VERSION ""

NS_ :

BS_:

BU_: EHR_Spare FEHR_3 PTO_SpeedSelector Dummy_Node_Ch2 FEHR_2 TrailerBrake OffBoardDiagnosticTool1_Ch2 PowerTakeOff_Ch2 Transmission1_Ch2 FEHR_1 REHR_5 REHR_4 REHR_3 REHR_2 REHR_1 InstrumentCluster_Ch2 ManagementComputer_Ch2 GWAY_OnBoardDiagnosticUnit_Ch2 GWAY_OffBoardDiagTool1_VB1_Ch2 GWAY_Engine1_Ch2 GWAY_CabDisplay1_Ch2 AuxiliaryValveControl_Ch2

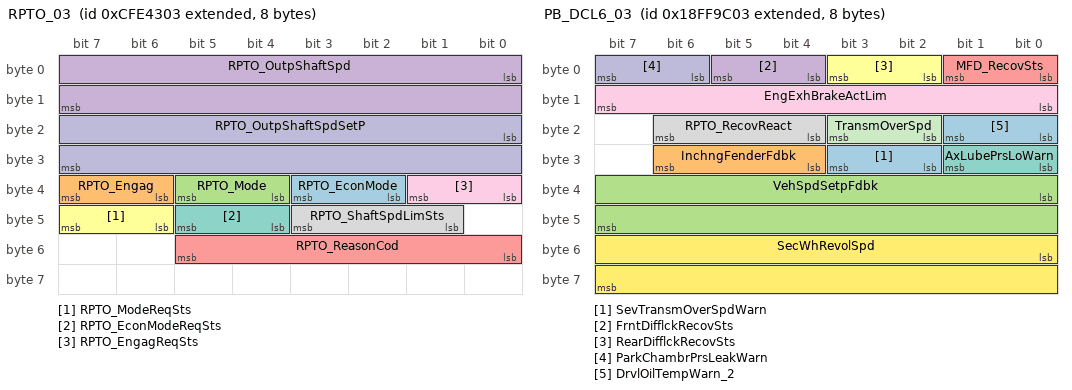
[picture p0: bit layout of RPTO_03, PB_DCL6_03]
BO_ 2365473539 RPTO_03: 8 Transmission1_Ch2
 SG_ RPTO_EconMode : 34|2@1+ (1,0) [0|3] ""  ManagementComputer_Ch2
 SG_ RPTO_Engag : 38|2@1+ (1,0) [0|3] ""  ManagementComputer_Ch2
 SG_ RPTO_Mode : 36|2@1+ (1,0) [0|3] ""  ManagementComputer_Ch2
 SG_ RPTO_OutpShaftSpd : 0|16@1+ (0.125,0) [0|8031.88] "1/min"  ManagementComputer_Ch2
 SG_ RPTO_ReasonCod : 48|6@1+ (1,0) [0|63] ""  ManagementComputer_Ch2
 SG_ RPTO_ModeReqSts : 46|2@1+ (1,0) [0|3] "" Vector__XXX
 SG_ RPTO_EconModeReqSts : 44|2@1+ (1,0) [0|3] "" Vector__XXX
 SG_ RPTO_ShaftSpdLimSts : 41|3@1+ (1,0) [0|7] "" Vector__XXX
 SG_ RPTO_EngagReqSts : 32|2@1+ (1,0) [0|3] "" Vector__XXX
 SG_ RPTO_OutpShaftSpdSetP : 16|16@1+ (0.125,0) [0|8031.88] "rpm" Vector__XXX

BO_ 2566877955 PB_ECU_DatasetChksum_03: 8 Transmission1_Ch2
 SG_ ECU_DatasetChksum : 0|32@1+ (1,0) [0|4294967295] ""  ManagementComputer_Ch2

BO_ 2565482243 RQST_03_27: 3 Transmission1_Ch2
 SG_ PGN_RQST_03_27 : 0|24@1+ (1,0) [0|16777200] ""  ManagementComputer_Ch2

BO_ 2566888451 PB_DCL6_03: 8 Transmission1_Ch2
 SG_ SevTransmOverSpdWarn : 26|2@1+ (1,0) [0|3] ""  ManagementComputer_Ch2
 SG_ InchngFenderFdbk : 28|3@1+ (1,0) [0|7] ""  ManagementComputer_Ch2
 SG_ VehSpdSetpFdbk : 32|16@1+ (0.015625,0) [0|1003.98] ""  ManagementComputer_Ch2
 SG_ FrntDifflckRecovSts : 4|2@1+ (1,0) [0|3] ""  ManagementComputer_Ch2
 SG_ MFD_RecovSts : 0|2@1+ (1,0) [0|3] ""  ManagementComputer_Ch2
 SG_ RearDifflckRecovSts : 2|2@1+ (1,0) [0|3] ""  ManagementComputer_Ch2
 SG_ AxLubePrsLoWarn : 24|2@1+ (1,0) [0|3] ""  ManagementComputer_Ch2
 SG_ RPTO_RecovReact : 20|3@1+ (1,0) [0|7] ""  ManagementComputer_Ch2
 SG_ EngExhBrakeActLim : 8|8@1+ (0.4,0) [0|100] "%"  ManagementComputer_Ch2
 SG_ ParkChambrPrsLeakWarn : 6|2@1+ (1,0) [0|3] ""  ManagementComputer_Ch2
 SG_ TransmOverSpd : 18|2@1+ (1,0) [0|3] ""  ManagementComputer_Ch2
 SG_ SecWhRevolSpd : 48|16@1+ (0.015625,0) [0|1003.98] ""  ManagementComputer_Ch2
 SG_ DrvlOilTempWarn_2 : 16|2@1+ (1,0) [0|3] "" Vector__XXX

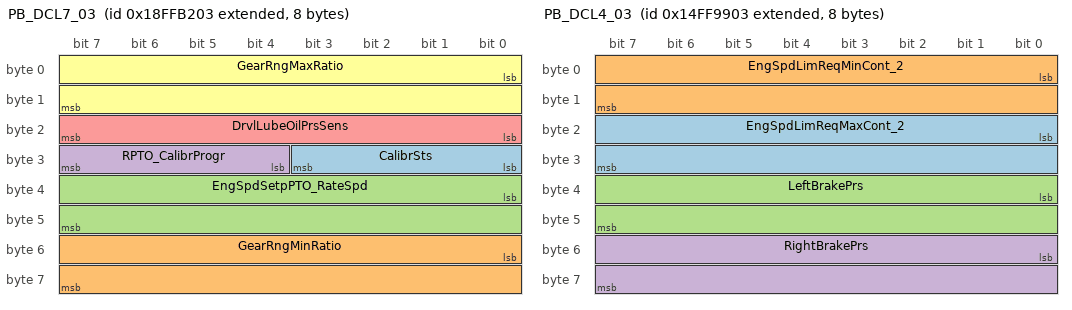
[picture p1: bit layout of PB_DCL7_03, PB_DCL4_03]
BO_ 2566894083 PB_DCL7_03: 8 Transmission1_Ch2
 SG_ CalibrSts : 24|4@1+ (1,0) [0|15] ""  ManagementComputer_Ch2
 SG_ GearRngMinRatio : 48|16@1+ (1E-05,0) [0|0.3] ""  ManagementComputer_Ch2
 SG_ EngSpdSetpPTO_RateSpd : 32|16@1+ (0.125,0) [0|8031.88] "rpm"  ManagementComputer_Ch2
 SG_ RPTO_CalibrProgr : 28|4@1+ (1,0) [0|15] ""  ManagementComputer_Ch2
 SG_ DrvlLubeOilPrsSens : 16|8@1+ (5,0) [0|1250] "kPa"  ManagementComputer_Ch2
 SG_ GearRngMaxRatio : 0|16@1+ (1E-05,0) [0|0.3] ""  ManagementComputer_Ch2

BO_ 2499778819 PB_DCL4_03: 8 Transmission1_Ch2
 SG_ EngSpdLimReqMaxCont_2 : 16|16@1+ (0.125,0) [0|8031.88] "rpm"  ManagementComputer_Ch2
 SG_ EngSpdLimReqMinCont_2 : 0|16@1+ (0.125,0) [0|8031.88] "rpm"  ManagementComputer_Ch2
 SG_ LeftBrakePrs : 32|16@1+ (1,0) [0|64255] "kPa"  ManagementComputer_Ch2
 SG_ RightBrakePrs : 48|16@1+ (1,0) [0|64255] "kPa"  ManagementComputer_Ch2

BO_ 2566842115 VH_03: 8 Transmission1_Ch2
 SG_ TotPTO_Hour : 32|32@1+ (0.05,0) [0|210554060.75] "h"  ManagementComputer_Ch2
 SG_ TotVehHour : 0|32@1+ (0.05,0) [0|2.10554E+18] "h"  ManagementComputer_Ch2

BO_ 2566801923 ETC7_03: 8 Transmission1_Ch2
 SG_ TransmReqGearFdbk : 24|8@1+ (1,-125) [-125|130] "gear value"  ManagementComputer_Ch2
 SG_ TransmMode_9Ind : 44|2@1+ (1,0) [0|3] "" Vector__XXX
 SG_ TransmMode_10Ind : 46|2@1+ (1,0) [0|3] "" Vector__XXX
 SG_ TransmAutoN_Sts : 51|3@1+ (1,0) [0|7] "" Vector__XXX
 SG_ TransmAirSupplyPrsInd : 48|3@1+ (1,0) [0|7] "" Vector__XXX
 SG_ TransmCurrRngDisplayBlnkSts : 0|2@1+ (1,0) [0|3] "" Vector__XXX
 SG_ TransmServInd : 2|2@1+ (1,0) [0|3] "" Vector__XXX
 SG_ TransmReqRngDisplayBlnkSts : 4|2@1+ (1,0) [0|3] "" Vector__XXX
 SG_ TransmReqRngDisplayFlashSts : 6|2@1+ (1,0) [0|3] "" Vector__XXX
 SG_ TransmReadyBrakeRleas : 8|2@1+ (1,0) [0|3] "" Vector__XXX
 SG_ ActvShftConsleInd : 10|2@1+ (1,0) [0|3] "" Vector__XXX
 SG_ TransmEngCrkEna : 12|2@1+ (1,0) [0|3] "" Vector__XXX
 SG_ TransmShftInhInd : 14|2@1+ (1,0) [0|3] "" Vector__XXX
 SG_ TransmMode_4Ind : 16|2@1+ (1,0) [0|3] "" Vector__XXX
 SG_ TransmMode_3Ind : 18|2@1+ (1,0) [0|3] "" Vector__XXX
 SG_ TransmMode_2Ind : 20|2@1+ (1,0) [0|3] "" Vector__XXX
 SG_ TransmMode_1Ind : 22|2@1+ (1,0) [0|3] "" Vector__XXX
 SG_ TransmMode_5Ind : 32|2@1+ (1,0) [0|3] "" Vector__XXX
 SG_ TransmMode_6Ind : 34|2@1+ (1,0) [0|3] "" Vector__XXX
 SG_ TransmMode_7Ind : 36|2@1+ (1,0) [0|3] "" Vector__XXX
 SG_ TransmMode_8Ind : 38|2@1+ (1,0) [0|3] "" Vector__XXX
 SG_ TransmRevGearShftInhSts : 40|2@1+ (1,0) [0|3] "" Vector__XXX
 SG_ TransmWarnInd : 42|2@1+ (1,0) [0|3] "" Vector__XXX

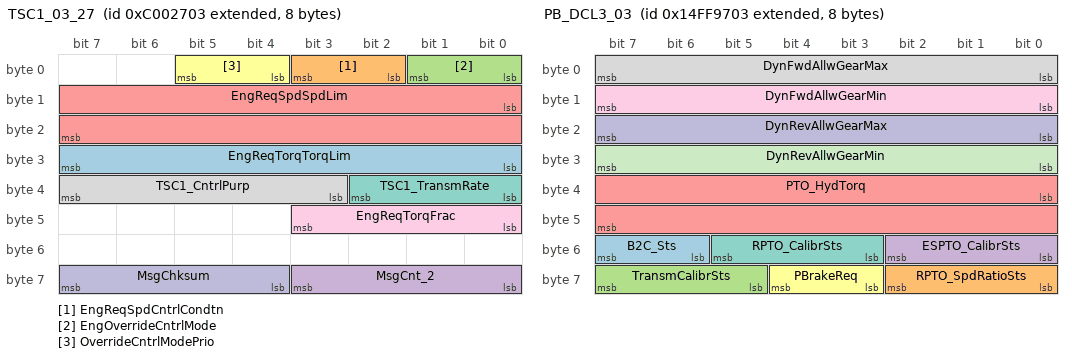
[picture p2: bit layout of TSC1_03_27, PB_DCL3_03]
BO_ 2348820227 TSC1_03_27: 8 Transmission1_Ch2
 SG_ EngReqTorqTorqLim : 24|8@1+ (1,-125) [-125|125] "%"  ManagementComputer_Ch2
 SG_ EngReqSpdCntrlCondtn : 2|2@1+ (1,0) [0|3] ""  ManagementComputer_Ch2
 SG_ EngOverrideCntrlMode : 0|2@1+ (1,0) [0|3] ""  ManagementComputer_Ch2
 SG_ MsgCnt_2 : 56|4@1+ (1,0) [0|15] "count"  ManagementComputer_Ch2
 SG_ EngReqSpdSpdLim : 8|16@1+ (0.125,0) [0|8031.88] "rpm"  ManagementComputer_Ch2
 SG_ OverrideCntrlModePrio : 4|2@1+ (1,0) [0|3] "" Vector__XXX
 SG_ TSC1_TransmRate : 32|3@1+ (1,0) [0|7] "" Vector__XXX
 SG_ TSC1_CntrlPurp : 35|5@1+ (1,0) [0|31] "" Vector__XXX
 SG_ EngReqTorqFrac : 40|4@1+ (0.125,0) [0|0.875] "%" Vector__XXX
 SG_ MsgChksum : 60|4@1+ (1,0) [0|15] "count" Vector__XXX

BO_ 2499778307 PB_DCL3_03: 8 Transmission1_Ch2
 SG_ B2C_Sts : 54|2@1+ (1,0) [0|3] ""  ManagementComputer_Ch2
 SG_ RPTO_SpdRatioSts : 56|3@1+ (1,0) [0|7] ""  ManagementComputer_Ch2
 SG_ TransmCalibrSts : 61|3@1+ (1,0) [0|7] ""  ManagementComputer_Ch2
 SG_ ESPTO_CalibrSts : 48|3@1+ (1,0) [0|7] ""  ManagementComputer_Ch2
 SG_ PTO_HydTorq : 32|16@1+ (1,0) [0|64255] "Nm"  ManagementComputer_Ch2
 SG_ PBrakeReq : 59|2@1+ (1,0) [0|3] ""  ManagementComputer_Ch2
 SG_ RPTO_CalibrSts : 51|3@1+ (1,0) [0|7] ""  ManagementComputer_Ch2
 SG_ DynFwdAllwGearMax : 0|8@1+ (1,-125) [-125|125] "gear value"  ManagementComputer_Ch2
 SG_ DynFwdAllwGearMin : 8|8@1+ (1,-125) [-125|125] "gear value"  ManagementComputer_Ch2
 SG_ DynRevAllwGearMax : 16|8@1+ (1,-125) [-125|125] "gear value"  ManagementComputer_Ch2
 SG_ DynRevAllwGearMin : 24|8@1+ (1,-125) [-125|125] "gear value"  ManagementComputer_Ch2

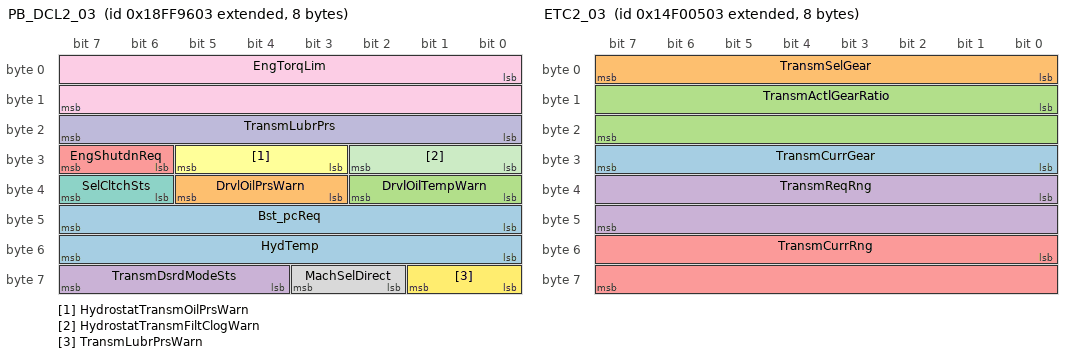
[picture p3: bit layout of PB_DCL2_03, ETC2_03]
BO_ 2566886915 PB_DCL2_03: 8 Transmission1_Ch2
 SG_ Bst_pcReq : 40|8@1+ (0.4,0) [0|100] "%"  ManagementComputer_Ch2
 SG_ DrvlOilPrsWarn : 35|3@1+ (1,0) [0|7] ""  ManagementComputer_Ch2
 SG_ DrvlOilTempWarn : 32|3@1+ (1,0) [0|7] ""  ManagementComputer_Ch2
 SG_ TransmDsrdModeSts : 60|4@1+ (1,0) [0|15] ""  ManagementComputer_Ch2
 SG_ EngShutdnReq : 30|2@1+ (1,0) [0|3] "enum"  ManagementComputer_Ch2
 SG_ HydrostatTransmOilPrsWarn : 27|3@1+ (1,0) [0|7] ""  ManagementComputer_Ch2
 SG_ SelCltchSts : 38|2@1+ (1,0) [0|3] ""  ManagementComputer_Ch2
 SG_ MachSelDirect : 58|2@1+ (1,0) [0|3] ""  ManagementComputer_Ch2
 SG_ EngTorqLim : 0|16@1+ (1,0) [0|64255] "Nm"  ManagementComputer_Ch2
 SG_ TransmLubrPrs : 16|8@1+ (16,0) [0|4000] "kPa"  ManagementComputer_Ch2
 SG_ HydrostatTransmFiltClogWarn : 24|3@1+ (1,0) [0|7] "" Vector__XXX
 SG_ TransmLubrPrsWarn : 56|2@1+ (1,0) [0|3] "" Vector__XXX
 SG_ HydTemp : 48|8@1+ (1,-40) [-40|210] "°C" Vector__XXX

BO_ 2566887427 PB_WRSAR_03: 8 Transmission1_Ch2
 SG_ FwdWhRevolSpdAllwRngMax : 16|16@1+ (0.015625,0) [0|1003.98] ""  ManagementComputer_Ch2
 SG_ RevWhRevolSpdAllwRngMax : 48|16@1+ (0.015625,0) [0|1003.98] ""  ManagementComputer_Ch2

BO_ 2498757891 ETC2_03: 8 Transmission1_Ch2
 SG_ TransmCurrGear : 24|8@1+ (1,-125) [-125|125] "gear value"  ManagementComputer_Ch2
 SG_ TransmSelGear : 0|8@1+ (1,-125) [-125|125] "gear value"  ManagementComputer_Ch2
 SG_ TransmActlGearRatio : 8|16@1+ (0.001,0) [0|64.255] "" Vector__XXX
 SG_ TransmReqRng : 32|16@1+ (1,0) [0|255] "per byte" Vector__XXX
 SG_ TransmCurrRng : 48|16@1+ (1,0) [0|255] "per byte" Vector__XXX

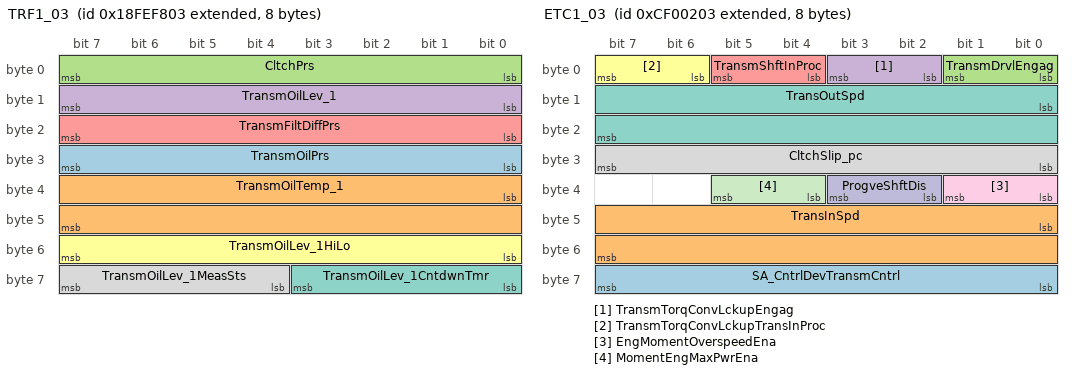
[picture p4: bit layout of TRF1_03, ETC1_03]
BO_ 2566846467 TRF1_03: 8 Transmission1_Ch2
 SG_ TransmOilPrs : 24|8@1+ (16,0) [0|4000] "kPa"  ManagementComputer_Ch2
 SG_ TransmOilTemp_1 : 32|16@1+ (0.03125,-273) [-273|1734.97] "°C"  ManagementComputer_Ch2
 SG_ CltchPrs : 0|8@1+ (16,0) [0|4000] "kPa" Vector__XXX
 SG_ TransmOilLev_1 : 8|8@1+ (0.4,0) [0|100] "%" Vector__XXX
 SG_ TransmFiltDiffPrs : 16|8@1+ (2,0) [0|500] "kPa" Vector__XXX
 SG_ TransmOilLev_1HiLo : 48|8@1+ (0.5,-62.5) [-62.5|62.5] "L" Vector__XXX
 SG_ TransmOilLev_1CntdwnTmr : 56|4@1+ (1,0) [0|15] "" Vector__XXX
 SG_ TransmOilLev_1MeasSts : 60|4@1+ (1,0) [0|15] "" Vector__XXX

BO_ 2364539395 ETC1_03: 8 Transmission1_Ch2
 SG_ SA_CntrlDevTransmCntrl : 56|8@1+ (1,0) [0|255] "source address/bit" Vector__XXX
 SG_ TransInSpd : 40|16@1+ (0.125,0) [0|8031.88] "rpm"  ManagementComputer_Ch2
 SG_ TransmDrvlEngag : 0|2@1+ (1,0) [0|3] "" Vector__XXX
 SG_ TransmTorqConvLckupEngag : 2|2@1+ (1,0) [0|3] "" Vector__XXX
 SG_ TransmShftInProc : 4|2@1+ (1,0) [0|3] "" Vector__XXX
 SG_ TransmTorqConvLckupTransInProc : 6|2@1+ (1,0) [0|3] "" Vector__XXX
 SG_ TransOutSpd : 8|16@1+ (0.125,0) [0|8031.88] "rpm" Vector__XXX
 SG_ CltchSlip_pc : 24|8@1+ (0.4,0) [0|100] "%" Vector__XXX
 SG_ EngMomentOverspeedEna : 32|2@1+ (1,0) [0|3] "" Vector__XXX
 SG_ ProgveShftDis : 34|2@1+ (1,0) [0|3] "" Vector__XXX
 SG_ MomentEngMaxPwrEna : 36|2@1+ (1,0) [0|3] "" Vector__XXX

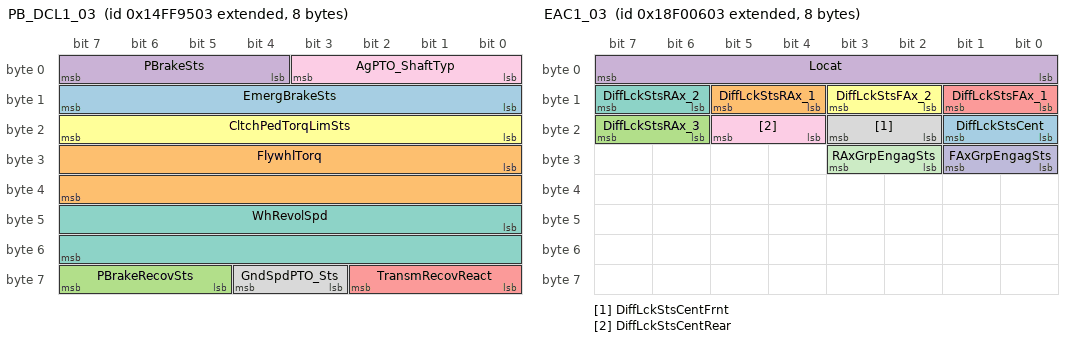
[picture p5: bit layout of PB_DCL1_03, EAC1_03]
BO_ 2499777795 PB_DCL1_03: 8 Transmission1_Ch2
 SG_ EmergBrakeSts : 8|8@1+ (0.4,0) [0|100] "%"  ManagementComputer_Ch2
 SG_ FlywhlTorq : 24|16@1+ (1,-32000) [-32000|32255] "Nm"  ManagementComputer_Ch2
 SG_ PBrakeRecovSts : 61|3@1+ (1,0) [0|7] ""  ManagementComputer_Ch2
 SG_ PBrakeSts : 4|4@1+ (1,0) [0|15] ""  ManagementComputer_Ch2
 SG_ TransmRecovReact : 56|3@1+ (1,0) [0|7] ""  ManagementComputer_Ch2
 SG_ CltchPedTorqLimSts : 16|8@1+ (1,-25) [-25|125] "%"  ManagementComputer_Ch2
 SG_ WhRevolSpd : 40|16@1+ (0.015625,0) [0|1003.98] ""  ManagementComputer_Ch2
 SG_ GndSpdPTO_Sts : 59|2@1+ (1,0) [0|3] ""  ManagementComputer_Ch2
 SG_ AgPTO_ShaftTyp : 0|4@1+ (1,0) [0|15] ""  ManagementComputer_Ch2

BO_ 2565867011 EAC1_03: 8 Transmission1_Ch2
 SG_ DiffLckStsCent : 16|2@1+ (1,0) [0|3] ""  ManagementComputer_Ch2
 SG_ DiffLckStsRAx_1 : 12|2@1+ (1,0) [0|3] ""  ManagementComputer_Ch2
 SG_ DiffLckStsRAx_3 : 22|2@1+ (1,0) [0|3] "" Vector__XXX
 SG_ Locat : 0|8@1+ (1,0) [0|255] "" Vector__XXX
 SG_ DiffLckStsFAx_1 : 8|2@1+ (1,0) [0|3] "" Vector__XXX
 SG_ DiffLckStsFAx_2 : 10|2@1+ (1,0) [0|3] "" Vector__XXX
 SG_ DiffLckStsRAx_2 : 14|2@1+ (1,0) [0|3] "" Vector__XXX
 SG_ DiffLckStsCentFrnt : 18|2@1+ (1,0) [0|3] "" Vector__XXX
 SG_ DiffLckStsCentRear : 20|2@1+ (1,0) [0|3] "" Vector__XXX
 SG_ FAxGrpEngagSts : 24|2@1+ (1,0) [0|3] "" Vector__XXX
 SG_ RAxGrpEngagSts : 26|2@1+ (1,0) [0|3] "" Vector__XXX

BO_ 2565344807 ACKM_27_0E: 8 ManagementComputer_Ch2
 SG_ PGN_RQST2_27_0E : 40|24@1+ (1,0) [0|16777200] ""  TrailerBrake
 SG_ AddrNegAck m1 : 32|8@1+ (1,0) [0|255] ""  TrailerBrake
 SG_ AddrBusy m3 : 32|8@1+ (1,0) [0|255] ""  TrailerBrake
 SG_ AddrAck m0 : 32|8@1+ (1,0) [0|255] ""  TrailerBrake
 SG_ AddrAccssDeny m2 : 32|8@1+ (1,0) [0|255] ""  TrailerBrake
 SG_ GrpFunctValAck : 8|8@1+ (1,0) [0|255] ""  TrailerBrake
 SG_ CByteAckm M : 0|8@1+ (1,0) [0|255] ""  TrailerBrake

BO_ 2565475879 RQST_27_0E: 3 ManagementComputer_Ch2
 SG_ PGN_RQST_27_0E : 0|24@1+ (1,0) [0|16777200] ""  TrailerBrake

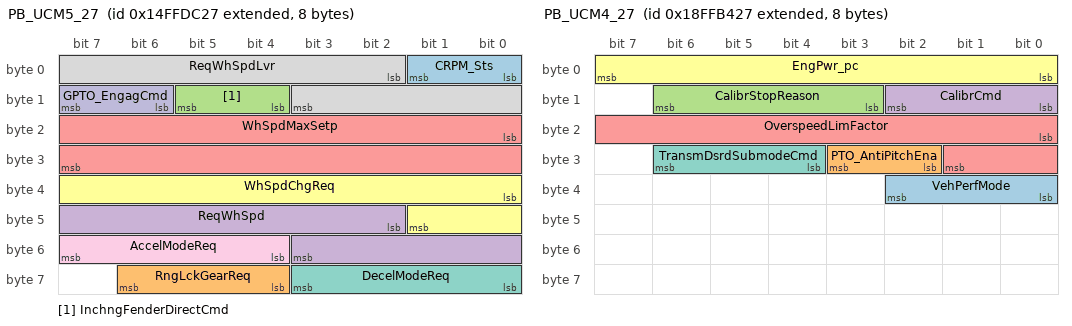
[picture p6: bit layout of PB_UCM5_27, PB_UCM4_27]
BO_ 2499796007 PB_UCM5_27: 8 ManagementComputer_Ch2
 SG_ CRPM_Sts : 0|2@1+ (1,0) [0|3] "" Vector__XXX
 SG_ RngLckGearReq : 60|3@1+ (1,0) [0|7] ""  Transmission1_Ch2
 SG_ InchngFenderDirectCmd : 12|2@1+ (1,0) [0|3] ""  Transmission1_Ch2
 SG_ ReqWhSpd : 42|10@1+ (0.1,0) [0|100] ""  Transmission1_Ch2
 SG_ WhSpdMaxSetp : 16|16@1+ (0.015625,0) [0|1003.98] ""  Transmission1_Ch2
 SG_ WhSpdChgReq : 32|10@1+ (0.1,-50) [-50|50] "%"  Transmission1_Ch2
 SG_ DecelModeReq : 56|4@1+ (1,0) [0|15] ""  Transmission1_Ch2
 SG_ ReqWhSpdLvr : 2|10@1+ (0.1,0) [0|100] ""  Transmission1_Ch2
 SG_ AccelModeReq : 52|4@1+ (1,0) [0|15] ""  Transmission1_Ch2
 SG_ GPTO_EngagCmd : 14|2@1+ (1,0) [0|3] "" Vector__XXX

BO_ 2566877991 PB_ECU_DatasetChksum_27: 8 ManagementComputer_Ch2
 SG_ ECU_DatasetChksum : 0|32@1+ (1,0) [0|4294967295] ""  Transmission1_Ch2

BO_ 2565473063 RQST_27_03: 3 ManagementComputer_Ch2
 SG_ PGN_RQST_27_03 : 0|24@1+ (1,0) [0|16777200] ""  Transmission1_Ch2

BO_ 2565341991 ACKM_27_03: 8 ManagementComputer_Ch2
 SG_ PGN_RQST2_27_03 : 40|24@1+ (1,0) [0|16777200] ""  Transmission1_Ch2
 SG_ AddrNegAck m1 : 32|8@1+ (1,0) [0|255] ""  Transmission1_Ch2
 SG_ AddrBusy m3 : 32|8@1+ (1,0) [0|255] ""  Transmission1_Ch2
 SG_ AddrAck m0 : 32|8@1+ (1,0) [0|255] ""  Transmission1_Ch2
 SG_ AddrAccssDeny m2 : 32|8@1+ (1,0) [0|255] ""  Transmission1_Ch2
 SG_ GrpFunctValAck : 8|8@1+ (1,0) [0|255] ""  Transmission1_Ch2
 SG_ CByteAckm M : 0|8@1+ (1,0) [0|255] ""  Transmission1_Ch2

BO_ 2566894631 PB_UCM4_27: 8 ManagementComputer_Ch2
 SG_ VehPerfMode : 32|3@1+ (1,0) [0|7] ""  Transmission1_Ch2
 SG_ PTO_AntiPitchEna : 26|2@1+ (1,0) [0|3] ""  Transmission1_Ch2
 SG_ CalibrStopReason : 11|4@1+ (1,0) [0|15] ""  Transmission1_Ch2
 SG_ CalibrCmd : 8|3@1+ (1,0) [0|7] ""  Transmission1_Ch2
 SG_ OverspeedLimFactor : 16|10@1+ (0.01,0) [0|10.23] " "  Transmission1_Ch2
 SG_ EngPwr_pc : 0|8@1+ (1,0) [0|250] "%"  Transmission1_Ch2
 SG_ TransmDsrdSubmodeCmd : 28|3@1+ (1,0) [0|7] ""  Transmission1_Ch2

BO_ 2566877735 PB_ECU_Dataset_27: 12 ManagementComputer_Ch2
 SG_ RAxRatio : 64|4@1+ (1,0) [0|15] "" Vector__XXX
 SG_ FrntBrakeOpt : 60|2@1+ (1,0) [0|3] "" Vector__XXX
 SG_ BrandDiff : 59|1@1+ (1,0) [0|1] "" Vector__XXX
 SG_ Brand : 56|3@1+ (1,0) [0|7] ""  Transmission1_Ch2
 SG_ EngRateSpd : 40|16@1+ (0.125,0) [0|8031.875] "rpm" Vector__XXX
 SG_ EngOverspeedLim : 8|16@1+ (1,0) [0|3500] "rpm" Vector__XXX
 SG_ EngAntistlLim : 24|16@1+ (1,0) [0|3500] "rpm" Vector__XXX
 SG_ ECU_DatasetInfoMapId : 0|8@1+ (1,0) [0|250] ""  Transmission1_Ch2

BO_ 2499798055 PB_Heartbeat_27_03: 8 ManagementComputer_Ch2
 SG_ SpecialModeResp : 47|1@1+ (1,0) [0|1] "" Vector__XXX
 SG_ SpecialModeReq : 44|3@1+ (1,0) [0|7] "" Vector__XXX
 SG_ MsgChksum_4 : 12|4@1+ (1,0) [0|15] "count"  Transmission1_Ch2
 SG_ KeyPositn : 48|8@1+ (1,0) [0|255] "" Vector__XXX
 SG_ BattMainSwHoldFunct : 40|4@1+ (1,0) [0|15] "" Vector__XXX
 SG_ ThisNetReq : 22|2@1+ (1,0) [0|3] "" Vector__XXX
 SG_ BattMainSwHoldReq : 20|2@1+ (1,0) [0|3] "" Vector__XXX
 SG_ OpSeatSw : 8|2@1+ (1,0) [0|3] ""  Transmission1_Ch2
 SG_ AutoGuideEnaSts : 16|2@1+ (1,0) [0|3] "" Vector__XXX
 SG_ Hrtbt : 0|8@1+ (1,0) [0|251] "count"  Transmission1_Ch2
 SG_ WakeUpInDozeMode : 24|2@1+ (1,0) [0|3] "" Vector__XXX
 SG_ WakeUpFunct : 28|4@1+ (1,0) [0|15] "" Vector__XXX
 SG_ VehMov : 36|2@1+ (1,0) [0|3] "" Vector__XXX
 SG_ KeySwNotOFF : 10|2@1+ (1,0) [0|3] "" Vector__XXX
 SG_ IgnON : 26|2@1+ (1,0) [0|3] "" Vector__XXX
 SG_ EngStartSts : 32|2@1+ (1,0) [0|3] "" Vector__XXX
 SG_ CByteNetManage : 18|2@1+ (1,0) [0|3] "" Vector__XXX
 SG_ EngRun : 34|2@1+ (1,0) [0|3] "" Vector__XXX
 SG_ EmergEngOff_ReqSts : 39|1@1+ (1,0) [0|1] "states/1 bit" Vector__XXX
 SG_ MasterDisconnSwSts : 38|1@1+ (1,0) [0|1] "states/1 bit" Vector__XXX

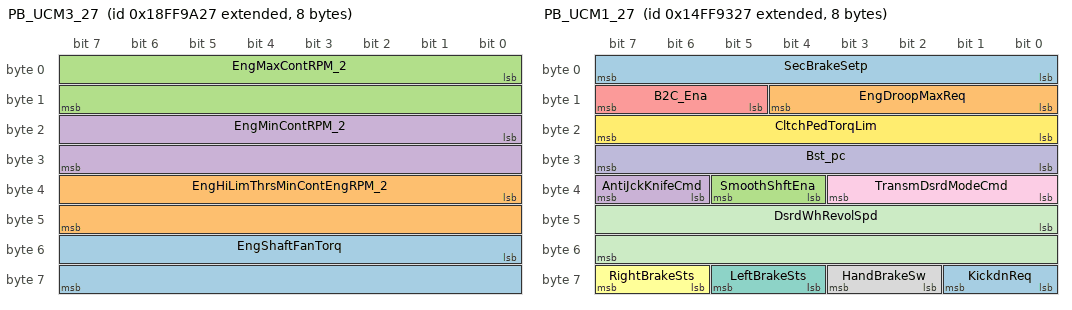
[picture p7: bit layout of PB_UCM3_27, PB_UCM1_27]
BO_ 2566887975 PB_UCM3_27: 8 ManagementComputer_Ch2
 SG_ EngShaftFanTorq : 48|16@1+ (1,0) [0|64255] "Nm"  Transmission1_Ch2
 SG_ EngHiLimThrsMinContEngRPM_2 : 32|16@1+ (0.125,0) [0|8031.88] "rpm"  Transmission1_Ch2
 SG_ EngMaxContRPM_2 : 0|16@1+ (0.125,0) [0|8031.88] "rpm"  Transmission1_Ch2
 SG_ EngMinContRPM_2 : 16|16@1+ (0.125,0) [0|8031.88] "rpm"  Transmission1_Ch2

BO_ 2499777319 PB_UCM1_27: 8 ManagementComputer_Ch2
 SG_ KickdnReq : 56|2@1+ (1,0) [0|3] ""  Transmission1_Ch2
 SG_ EngDroopMaxReq : 8|5@1+ (1,0) [0|31] ""  Transmission1_Ch2
 SG_ SmoothShftEna : 36|2@1+ (1,0) [0|3] ""  Transmission1_Ch2
 SG_ AntiJckKnifeCmd : 38|2@1+ (1,0) [0|3] ""  Transmission1_Ch2
 SG_ B2C_Ena : 13|3@1+ (1,0) [0|7] ""  Transmission1_Ch2
 SG_ RightBrakeSts : 62|2@1+ (1,0) [0|3] ""  Transmission1_Ch2
 SG_ LeftBrakeSts : 60|2@1+ (1,0) [0|3] ""  Transmission1_Ch2
 SG_ HandBrakeSw : 58|2@1+ (1,0) [0|3] ""  Transmission1_Ch2
 SG_ TransmDsrdModeCmd : 32|4@1+ (1,0) [0|15] ""  Transmission1_Ch2
 SG_ Bst_pc : 24|8@1+ (0.4,0) [0|100] "%"  Transmission1_Ch2
 SG_ DsrdWhRevolSpd : 40|16@1+ (0.015625,0) [0|1003.98] "rpm"  Transmission1_Ch2
 SG_ CltchPedTorqLim : 16|8@1+ (1,-25) [-25|125] "%"  Transmission1_Ch2
 SG_ SecBrakeSetp : 0|8@1+ (0.4,0) [0|100] "%"  Transmission1_Ch2

BO_ 2348941095 TC1_27: 8 ManagementComputer_Ch2
 SG_ TransmAutoN_Req : 48|2@1+ (1,0) [0|3] "" Vector__XXX
 SG_ TransmGearShftInhReq : 0|2@1+ (1,0) [0|3] "" Vector__XXX
 SG_ TransmTorqConvLckupDisReq : 2|2@1+ (1,0) [0|3] "" Vector__XXX
 SG_ DisengDrvlReq : 4|2@1+ (1,0) [0|3] ""  Transmission1_Ch2
 SG_ TransmRevGearShftInhReq : 6|2@1+ (1,0) [0|3] "" Vector__XXX
 SG_ Req_pcCltchSlip : 8|8@1+ (0.4,0) [0|100] "%" Vector__XXX
 SG_ TransmReqGear : 16|8@1+ (1,-125) [-125|125] "gear value"  Transmission1_Ch2
 SG_ DisengDiffLckReqFAx_1 : 24|2@1+ (1,0) [0|3] ""  Transmission1_Ch2
 SG_ DisengDiffLckReqFAx_2 : 26|2@1+ (1,0) [0|3] "" Vector__XXX
 SG_ DisengDiffLckReqRAx_1 : 28|2@1+ (1,0) [0|3] ""  Transmission1_Ch2
 SG_ DisengDiffLckReqRAx_2 : 30|2@1+ (1,0) [0|3] "" Vector__XXX
 SG_ DisengDiffLckReqCent : 32|2@1+ (1,0) [0|3] ""  Transmission1_Ch2
 SG_ DisengDiffLckReqCentFrnt : 34|2@1+ (1,0) [0|3] "" Vector__XXX
 SG_ DisengDiffLckReqCentRear : 36|2@1+ (1,0) [0|3] "" Vector__XXX
 SG_ TransmLoadReducInhReq : 38|2@1+ (1,0) [0|3] "" Vector__XXX
 SG_ TransmMode_1 : 40|2@1+ (1,0) [0|3] "" Vector__XXX
 SG_ TransmMode_2 : 42|2@1+ (1,0) [0|3] "" Vector__XXX
 SG_ TransmMode_3 : 44|2@1+ (1,0) [0|3] "" Vector__XXX
 SG_ TransmMode_4 : 46|2@1+ (1,0) [0|3] "" Vector__XXX
 SG_ TransmReqLaunchGear : 50|4@1+ (1,0) [0|15] "" Vector__XXX
 SG_ TransmShftSelDisplayModeSw : 54|2@1+ (1,0) [0|3] "" Vector__XXX
 SG_ TransmMode_5 : 56|2@1+ (1,0) [0|3] "" Vector__XXX
 SG_ TransmMode_6 : 58|2@1+ (1,0) [0|3] "" Vector__XXX
 SG_ TransmMode_7 : 60|2@1+ (1,0) [0|3] "" Vector__XXX
 SG_ TransmMode_8 : 62|2@1+ (1,0) [0|3] "" Vector__XXX

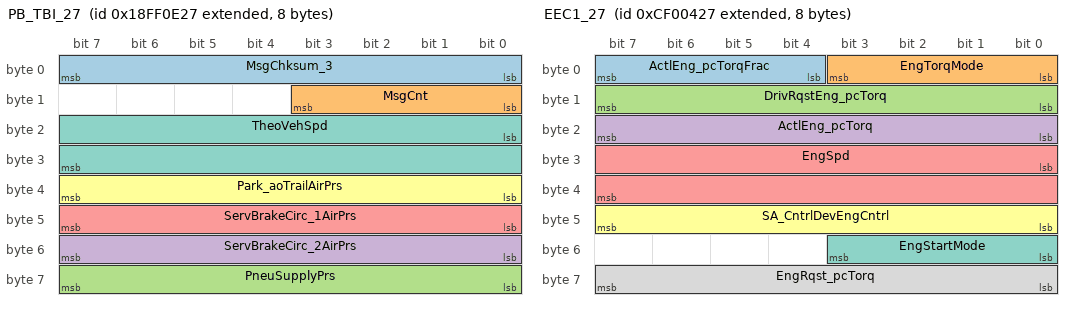
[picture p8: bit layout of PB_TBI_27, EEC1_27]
BO_ 2566852135 PB_TBI_27: 8 ManagementComputer_Ch2
 SG_ MsgChksum_3 : 0|8@1+ (1,0) [0|255] "count"  TrailerBrake
 SG_ MsgCnt : 8|4@1+ (1,0) [0|15] "count"  TrailerBrake
 SG_ PneuSupplyPrs : 56|8@1+ (8,0) [0|2000] "kPa"  TrailerBrake
 SG_ ServBrakeCirc_2AirPrs : 48|8@1+ (8,0) [0|2000] "kPa"  TrailerBrake
 SG_ ServBrakeCirc_1AirPrs : 40|8@1+ (8,0) [0|2000] "kPa"  TrailerBrake
 SG_ Park_aoTrailAirPrs : 32|8@1+ (8,0) [0|2000] "kPa"  TrailerBrake
 SG_ TheoVehSpd : 16|16@1+ (0.00390625,0) [0|250.996] "km/h"  TrailerBrake

BO_ 2632711975 TPDT_27: 8 ManagementComputer_Ch2
 SG_ PktDataTPDT : 8|56@1+ (1,0) [0|7.20575940379279E+16] ""  Transmission1_Ch2
 SG_ SN_TPDT : 0|8@1+ (1,0) [0|255] ""  Transmission1_Ch2

BO_ 2364539943 EEC1_27: 8 ManagementComputer_Ch2
 SG_ ActlEng_pcTorqFrac : 4|4@1+ (0.125,0) [0|0.875] "%" Vector__XXX
 SG_ EngTorqMode : 0|4@1+ (1,0) [0|15] ""  TrailerBrake
 SG_ DrivRqstEng_pcTorq : 8|8@1+ (1,-125) [-125|125] "%" Vector__XXX
 SG_ ActlEng_pcTorq : 16|8@1+ (1,-125) [-125|125] "%" Vector__XXX
 SG_ EngSpd : 24|16@1+ (0.125,0) [0|8031.88] "rpm" Vector__XXX
 SG_ SA_CntrlDevEngCntrl : 40|8@1+ (1,0) [0|255] "source address" Vector__XXX
 SG_ EngStartMode : 48|4@1+ (1,0) [0|15] "" Vector__XXX
 SG_ EngRqst_pcTorq : 56|8@1+ (1,-125) [-125|125] "%" Vector__XXX

BO_ 2632777511 TPCM_27: 8 ManagementComputer_Ch2
 SG_ CByteTPCM M : 0|8@1+ (1,0) [0|255] ""  Transmission1_Ch2
 SG_ TotMsgSizeTPCM_RTS m16 : 8|16@1+ (1,0) [0|64255] "counts"  Transmission1_Ch2
 SG_ TotNumPktTPCM_RTS m16 : 24|8@1+ (1,0) [0|255] ""  Transmission1_Ch2
 SG_ MaxNumPktTPCM_RTS m16 : 32|8@1+ (1,0) [0|255] ""  Transmission1_Ch2
 SG_ PGN_PktMsgTPCM_RTS m16 : 40|24@1+ (1,0) [0|16777200] ""  Transmission1_Ch2
 SG_ NumPktSentTPCM_CTS m17 : 8|8@1+ (1,0) [0|255] ""  Transmission1_Ch2
 SG_ NxtPktNumSentTPCM_CTS m17 : 16|8@1+ (1,0) [0|255] ""  Transmission1_Ch2
 SG_ ConnAbrtReason m255 : 8|8@1+ (1,0) [0|255] ""  Transmission1_Ch2
 SG_ TotNumPktBAM m32 : 24|8@1+ (1,0) [0|255] ""  Transmission1_Ch2
 SG_ TotMsgSizeBAM m32 : 8|16@1+ (1,0) [0|64255] "counts"  Transmission1_Ch2
 SG_ TotMsgSizeEoMA m19 : 8|16@1+ (1,0) [0|64255] "counts"  Transmission1_Ch2
 SG_ TotNumPktEoMA m19 : 24|8@1+ (1,0) [0|255] ""  Transmission1_Ch2
 SG_ PGN_PktMsgTPCM_ConnAbort m255 : 40|24@1+ (1,0) [0|16777200] ""  Transmission1_Ch2
 SG_ PGN_PktMsgTPCM_BAM m32 : 40|24@1+ (1,0) [0|16777200] ""  Transmission1_Ch2
 SG_ PGN_PktMsgTPCM_RTS2 m19 : 40|24@1+ (1,0) [0|16777200] ""  Transmission1_Ch2
 SG_ PGN_PktMsgTPCM_CTS m17 : 40|24@1+ (1,0) [0|16777200] ""  Transmission1_Ch2

CM_ BO_ 2365473539 "Primary or Rear Power Take off Output Shaft";
CM_ SG_ 2365473539 RPTO_Engag "VCL-DCL10-324 - feedback of RPTO_EngagCmd";
CM_ SG_ 2365473539 RPTO_OutpShaftSpd "VCL-DCL10-327 - revolution speed of the RPTO";
CM_ SG_ 2365473539 RPTO_ReasonCod "This parameter is used to indicate why the rear PTO cannot accept remote commands or has most recently ...";
CM_ SG_ 2365473539 RPTO_ModeReqSts "Parameter used to report the tractor ECUs status associated with a parameter whose requests are transient.";
CM_ SG_ 2365473539 RPTO_EconModeReqSts "Parameter used to report the tractor ECUs status associated with a parameter whose requests are transient.";
CM_ SG_ 2365473539 RPTO_ShaftSpdLimSts "Parameter used to report the tractor ECUs present limit status associated with a parameter whose commands are persistent";
CM_ SG_ 2365473539 RPTO_EngagReqSts "Parameter used to report the tractor ECUs status associated with a parameter whose requests are transient.";
CM_ BO_ 2566877955 "The message contains the checksum about ECU set PGN (0xFF72).";
CM_ SG_ 2566877955 ECU_DatasetChksum "The signal is a chekcusm according algorithm specified into system spec.";
CM_ BO_ 2565482243 "Used to Request a PGN from network device or devices.";
CM_ SG_ 2565482243 PGN_RQST_03_27 "PGN superset list which is requested by Request message";
CM_ BO_ 2566888451 "Message used to send to UCM some transmission parameters. This message was added after UCM-DEC splitting";
CM_ SG_ 2566888451 SevTransmOverSpdWarn "VCL-DCL10-58";
CM_ SG_ 2566888451 InchngFenderFdbk "VCL-DCL10-654 - Signal sent by DCL to UCM in order to give feedback about the Inching Fender availability/status";
CM_ SG_ 2566888451 VehSpdSetpFdbk "VCL-DCL10-404";
CM_ SG_ 2566888451 FrntDifflckRecovSts "VCL-DCL10-205, VCL-DCL10-508";
CM_ SG_ 2566888451 MFD_RecovSts "VCL-DCL10-207";
CM_ SG_ 2566888451 RearDifflckRecovSts "VCL-DCL10-206";
CM_ SG_ 2566888451 RPTO_RecovReact "VCL-DCL10-328";
CM_ SG_ 2566888451 EngExhBrakeActLim "VCL-DCL10-335 - This signal will set the amount of engine brake which is allowed according to the DEC algorithm. 100% = exhaust brake fully allowed/invalid, 0% = exhaust brake completely inhibited";
CM_ SG_ 2566888451 ParkChambrPrsLeakWarn "VCL-DCL10-354";
CM_ SG_ 2566888451 TransmOverSpd "VCL-DCL10-457";
CM_ SG_ 2566888451 SecWhRevolSpd "VCL-DCL10-67 - The speed measured contains the rear axle ratio";
CM_ SG_ 2566888451 DrvlOilTempWarn_2 "VCL-DCL10-58 - The DCL informs the VCL about the transmission oil temperature warning";
CM_ SG_ 2566894083 CalibrSts "VCL-DCL10-436 ACM0100 only";
CM_ SG_ 2566894083 GearRngMinRatio "VCL-DCL10-459";
CM_ SG_ 2566894083 RPTO_CalibrProgr "ACM0100 only";
CM_ SG_ 2566894083 DrvlLubeOilPrsSens "VCL-DCL10-413, ACM0100 only. ";
CM_ SG_ 2566894083 GearRngMaxRatio "VCL-DCL10-412";
CM_ BO_ 2499778819 "Message used to send to UCM some transmission parameters. This message was added after UCM-DEC splitting";
CM_ SG_ 2499778819 EngSpdLimReqMaxCont_2 "VCL-DCL10-85 - Requested maximum continuous engine speed. Engine Set Point Maximum Request parameter";
CM_ SG_ 2499778819 EngSpdLimReqMinCont_2 "VCL-DCL10-85 - Requested minimum continuous engine speed. Engine Set Point Minimum Request parameter";
CM_ SG_ 2499778819 LeftBrakePrs "VCL-DCL10-190 - absolute pressure of the left brake";
CM_ SG_ 2499778819 RightBrakePrs "VCL-DCL10-191 - absolute pressure of the right brake";
CM_ BO_ 2566842115 "Vehicle Hours";
CM_ SG_ 2566842115 TotPTO_Hour "Accumulated time of operation of power takeoff device.";
CM_ SG_ 2566842115 TotVehHour "Transmission hour - Accumulated time of operation of vehicle.";
CM_ BO_ 2566801923 "Transmission status information from the transmission controller to network.";
CM_ SG_ 2566801923 TransmReqGearFdbk "VCL-DCL10-203 - Feedback of the SPN 525 Transmission Requested Gear input as received from the VCL";
CM_ SG_ 2566801923 TransmMode_9Ind "Indicates that the transmission is operating under transmission mode 9 (SPN 6569) as commanded via the TC2 message (PGN 3328). The definition of the transmission mode is left to the discretion of the transmission manufacturer. 00 Transmission Mode 9 n...";
CM_ SG_ 2566801923 TransmMode_10Ind "Indicates that the transmission is operating under transmission mode 10 (SPN 6570) as commanded via the TC2 message (PGN 3328). The definition of the transmission mode is left to the discretion of the transmission manufacturer. 00 Transmission Mode 10...";
CM_ SG_ 2566801923 TransmAutoN_Sts "Indicates the transmission response to a Neutral request from SPN 7695 [Transmission Auto-Neutral (Manual Return) Request] or other vehicle input configured for Auto-Neutral (Manual Return) functionality. The applicability of the states and state tran...";
CM_ SG_ 2566801923 TransmAirSupplyPrsInd "Indicates whether transmission air supply is sufficient000   Normal Pressure Range - The transmission supply air pressure is within the normal operational range.001   Low pressure - The transmission supply air pressure is within a range that may reduc...";
CM_ SG_ 2566801923 TransmCurrRngDisplayBlnkSts "State signal indicating a transmission request for the display of the Transmission Current Range parameter (SPN 163) to ...";
CM_ SG_ 2566801923 TransmServInd "Signal from transmission indicating that some aspect of the gearbox requires servicing, such as the oil, filter, clutch(es) or ...";
CM_ SG_ 2566801923 TransmReqRngDisplayBlnkSts "State signal indicating a transmission request for the display of the Transmission Requested Range parameter (SPN162) ...";
CM_ SG_ 2566801923 TransmReqRngDisplayFlashSts "State signal indicating a transmission request for the display of the Transmission Requested Range parameter (SPN 162) ...";
CM_ SG_ 2566801923 TransmReadyBrakeRleas "This parameter indicates that enough torque / motive force is available at the transmission output shaft to release all the ...";
CM_ SG_ 2566801923 ActvShftConsleInd "Signal from transmission control unit indicating which shift console (primary or secondary) it currently considers as the ...";
CM_ SG_ 2566801923 TransmEngCrkEna "State signal from the transmission indicating if the transmission’s status is such that engine cranking is allowed (i.e.  at a ...";
CM_ SG_ 2566801923 TransmShftInhInd "State signal indicating a transmission request for the Shift Inhibit Indicator to be active or inactive. The shift inhibit ...";
CM_ SG_ 2566801923 TransmMode_4Ind "This state signal is the transmission’s indication that it is operating under transmission mode 4 (SPN 1855): Auto Function State: Auto Stand-By State Active";
CM_ SG_ 2566801923 TransmMode_3Ind "This state signal is the transmission’s indication that it is operating under transmission mode 3 (SPN 1854): Auto Function State: Auto Speed Matching State Active";
CM_ SG_ 2566801923 TransmMode_2Ind "This state signal is the transmission’s indication that it is operating under transmission mode 2 (SPN 1853): Control Mode: Autol Mode selection Request.";
CM_ SG_ 2566801923 TransmMode_1Ind "This state signal is the transmission’s indication that it is operating under transmission mode 1 (SPN 1852): Automatic Range Shift Enable.";
CM_ SG_ 2566801923 TransmMode_5Ind "Indicates whether transmission mode 5 is enabled. Auto Function State: Transport Mode ON State Active";
CM_ SG_ 2566801923 TransmMode_6Ind "Indicates whether transmission mode 6 is enabled: Auto Function State: Auto Upshift State Active";
CM_ SG_ 2566801923 TransmMode_7Ind "Indicates whether transmission mode 7 is enabled. Modes are manufacturer specific and are not necessarily mutually ...";
CM_ SG_ 2566801923 TransmMode_8Ind "Indicates whether transmission mode 8 is enabled. Modes are manufacturer specific and are not necessarily mutually ...";
CM_ SG_ 2566801923 TransmRevGearShftInhSts "Reflects the status of transmission reverse inhibit activity in response to requests via SPN 4242 - Transmission Reverse ...";
CM_ SG_ 2566801923 TransmWarnInd "Signal from transmission indicating that some aspect of its operation is not functioning correctly, and as a result, ...";
CM_ BO_ 2348820227 "NOTE - Retarder may be disabled by commanding a torque limit of 0%.  Use of the limit mode allows the use of the ...";
CM_ SG_ 2348820227 EngReqTorqTorqLim "VCL-DCL10-53.  Parameter provided to the engine or retarder in the torque/speed control message for controlling or limiting the output ...";
CM_ SG_ 2348820227 EngReqSpdCntrlCondtn "VCL-DCL10-51 - This mode tells the engine control system the governor characteristics that are desired during speed control. Engine Governor Suggested";
CM_ SG_ 2348820227 EngOverrideCntrlMode "VCL-DCL10-51 - The override control mode defines which sort of command is used: 00 Override disabled - Disable any existing control commanded by the source of this command.";
CM_ SG_ 2348820227 MsgCnt_2 "Used to detect situations where the transmitting ECU malfunction repeats the same frame all the time.Receiver may use this signal to detect this situation.The transmitter will increase the counter in every cycle, from 0 to 7 and then wrap.0xF if not used";
CM_ SG_ 2348820227 EngReqSpdSpdLim "VCL-DCL10-48 - Parameter provided to the engine from external sources in the torque/speed control message. Engine Suggested set point";
CM_ SG_ 2348820227 OverrideCntrlModePrio "VCL-DCL10-339 -This field is used as an input to the engine or retarder to determine the priority of the Override Control Mode received in ...";
CM_ SG_ 2348820227 TSC1_TransmRate "This parameter indicates the transmission rate at which the sending device will transmit the TSC1 message.  The engine ...";
CM_ SG_ 2348820227 TSC1_CntrlPurp "State signal which indicates which control mode the sending device is using to generate the TSC1 command.  Note that ...";
CM_ SG_ 2348820227 EngReqTorqFrac "This parameter displays an additional torque in percent of the reference engine torque.";
CM_ SG_ 2348820227 MsgChksum "The message checksum is used to verify the signal path from the transmitting device to the receiving device. It is calculated using the first 7 data bytes, the message counter and the bytes of the message identifier...";
CM_ BO_ 2499778307 "Message used to send to UCM some transmission parameters. This message was added after UCM-DEC splitting.Only for Discrete transmission";
CM_ SG_ 2499778307 B2C_Sts "VCL-DCL10-391.";
CM_ SG_ 2499778307 RPTO_SpdRatioSts "VCL-DCL10-331 - feedback of RPTO_SpdRatioCmd. Error value means that shifting is not allowed when in Neutral, RPTO_Mode and RPTO_EconMode must be not available";
CM_ SG_ 2499778307 TransmCalibrSts "VCL-DCL10-184";
CM_ SG_ 2499778307 ESPTO_CalibrSts "VCL-DCL10-332";
CM_ SG_ 2499778307 PTO_HydTorq "VCL-DCL10-91 - Measured torque by the PTO/Hydraulic Torque sensor";
CM_ SG_ 2499778307 PBrakeReq "VCL-DCL10-199 - This signal is used by DCL to inform the VCL about the needs of the Parking Brake System";
CM_ SG_ 2499778307 RPTO_CalibrSts "VCL-DCL10-329";
CM_ SG_ 2499778307 DynFwdAllwGearMax "VCL-DCL10-76 - Describes gear range allowed, maximum forward gear allowed";
CM_ SG_ 2499778307 DynFwdAllwGearMin "VCL-DCL10-76 - Describes gear range allowed, minimum forward gear allowed";
CM_ SG_ 2499778307 DynRevAllwGearMax "VCL-DCL10-76 - Describes gear range allowed, maximum reverse gear allowed";
CM_ SG_ 2499778307 DynRevAllwGearMin "VCL-DCL10-76 - Describes gear range allowed, minimum reverse gear allowed";
CM_ BO_ 2566886915 "Message used to send to UCM some transmission parameters. This message was added after UCM-DEC splitting";
CM_ SG_ 2566886915 Bst_pcReq "VCL-DCL10-90 - the signal Current Boost Percentage identifies the position of the current torque limit curve with respect to the unboosted (=0%) and boosted (=100%) curves";
CM_ SG_ 2566886915 DrvlOilPrsWarn "VCL-DCL10-453- The DCL informs the VCL about the internal recovery active (pressure warning)";
CM_ SG_ 2566886915 DrvlOilTempWarn "VCL-DCL10-58 - The DCL informs the VCL about the internal recovery active (temperature warning)";
CM_ SG_ 2566886915 TransmDsrdModeSts "VCL-DCL10-73 (DCT/PS) - Feedback of Desired Mode";
CM_ SG_ 2566886915 EngShutdnReq "VCL-DCL10-60 - FPT definition - Status signal which requests that all engine fuelling stop. External engine shutdown request is processed by the ECM only if vehicle speed is lower or equal to 20 Km/h.If speed is not available,it is considered as 0 Km/h.";
CM_ SG_ 2566886915 HydrostatTransmOilPrsWarn "VCL-DCL10-454 - This is the signal used by the DCL to notify the VCL about the HST Oil Pressure (Warning)";
CM_ SG_ 2566886915 SelCltchSts "The DCL informs the VCL about the Selected Clutch Status";
CM_ SG_ 2566886915 MachSelDirect "VCL-DCL10-37 - Current Wheel Direction Status";
CM_ SG_ 2566886915 EngTorqLim "Request by DCL to not exceed a specific Torque Value";
CM_ SG_ 2566886915 TransmLubrPrs "Used for 4WD tractor only";
CM_ SG_ 2566886915 HydrostatTransmFiltClogWarn "Not Used on ACM0100";
CM_ SG_ 2566886915 TransmLubrPrsWarn "VCL-DCL10-456";
CM_ SG_ 2566886915 HydTemp "Temp of hyd fluid.CH26 only.";
CM_ SG_ 2566887427 FwdWhRevolSpdAllwRngMax "VCL-DCL10-82 - wheel revolution speed setpoint (before wheels-no rolling circumference included)";
CM_ SG_ 2566887427 RevWhRevolSpdAllwRngMax "VCL-DCL10-82 - wheel revolution speed setpoint (before wheels-no rolling circumference included)";
CM_ BO_ 2498757891 "Electronic Transmission Controller 2";
CM_ SG_ 2498757891 TransmCurrGear "VCL-DCL10-74 - The gear currently engaged or the last gear engaged while the transmission is in the process of shifting to the new or selected gear,negative values are reverse gears, positive values are forward gears.Only for HiLoTransm: V1-Low; V2-High";
CM_ SG_ 2498757891 TransmSelGear "VCL-DCL10-75 - The gear the transmission will attempt to achieve during the current shift if a shift is in progress, or the next shift if one is pending. Values < 0 are reverse gears, values >0 are forward gears";
CM_ SG_ 2498757891 TransmActlGearRatio "Actual ratio of input shaft speed to output shaft speed.";
CM_ SG_ 2498757891 TransmReqRng "Range selected by the operator.  Characters may include P, Rx, Rx-1...R2, R1, R, Nx, Nx-1...N2, N1, N, D, D1, D2..., Dx, ...";
CM_ SG_ 2498757891 TransmCurrRng "Range currently being commanded by the transmission control system. Characters may include P, Rx, Rx-1...R2, R1, R, ...";
CM_ BO_ 2566846467 "Transmission Fluids 1";
CM_ SG_ 2566846467 TransmOilPrs "Gage pressure of lubrication fluid in transmission, measured after pump.";
CM_ SG_ 2566846467 TransmOilTemp_1 "VCL-DCL10-92 - First instance of transmission lubricant temperature.";
CM_ SG_ 2566846467 CltchPrs "Gage pressure of oil within a wet clutch.";
CM_ SG_ 2566846467 TransmOilLev_1 "First instance of a transmission oil level indicator. Conveys the ratio of volume of transmission sump oil to recommended ...";
CM_ SG_ 2566846467 TransmFiltDiffPrs "Change in transmission fluid pressure, measured after the filter, due to accumulation of solid or semisolid material on or in ...";
CM_ SG_ 2566846467 TransmOilLev_1HiLo "First instance of a transmission oil level indicator. Conveys the amount of current volume of transmission sump oil ...";
CM_ SG_ 2566846467 TransmOilLev_1CntdwnTmr "Countdown timer for the first instance of a transmission oil level indicator.  Once all vehicle conditions (such as vehicle ...";
CM_ SG_ 2566846467 TransmOilLev_1MeasSts "Measurement status for the first instance of a transmission oil level indicator.  Indicates if conditions are acceptable to ...";
CM_ BO_ 2364539395 "Electronic Transmission Controller 1";
CM_ SG_ 2364539395 SA_CntrlDevTransmCntrl "The source address of the SAE J1939 device currently controlling the transmission. Its value may be the source address ...";
CM_ SG_ 2364539395 TransInSpd "VCL-DCL10-65 - Rotational velocity of the primary shaft transferring power into the transmission.  When a torque converter is present, it is ...";
CM_ SG_ 2364539395 TransmDrvlEngag "VCL-DCL10-40 - Driveline engaged indicates the transmission controlled portion of the driveline is engaged sufficiently to allow a transfer.";
CM_ SG_ 2364539395 TransmTorqConvLckupEngag "State signal which indicates whether the torque converter lockup is engaged.";
CM_ SG_ 2364539395 TransmShftInProc "VCL-DCL10-338 - Indicates that the transmission is in process of shifting from the current gear to the selected gear.  This state is generally ...";
CM_ SG_ 2364539395 TransmTorqConvLckupTransInProc "State signal indicating whether or not the transmission torque converter lock up clutch is transitioning between being ...";
CM_ SG_ 2364539395 TransOutSpd "Calculated speed of the transmission output shaft.";
CM_ SG_ 2364539395 CltchSlip_pc "Parameter which represents the ratio of input shaft speed to current engine speed (in percent).";
CM_ SG_ 2364539395 EngMomentOverspeedEna "Command signal used to indicate that the engine speed may be boosted up to the maximum engine overspeed value to ...";
CM_ SG_ 2364539395 ProgveShftDis "Command signal used to indicate that progressive shifting by the engine should be disallowed.";
CM_ SG_ 2364539395 MomentEngMaxPwrEna "Momentarily Requesting highest torque map from the engine control ...";
CM_ BO_ 2499777795 "Message used to send to UCM some transmission parameters. This message was added after UCM-DEC splitting
";
CM_ SG_ 2499777795 EmergBrakeSts "VCL-DCL10-57 - Braking Status feedback calculated by the DCL";
CM_ SG_ 2499777795 FlywhlTorq "VCL-DCL10-66 - Measured torque by the damper inputs";
CM_ SG_ 2499777795 PBrakeRecovSts "VCL-DCL10-61 - This is the signal used by the DCL to notify the VCL about the Parking Brake status";
CM_ SG_ 2499777795 PBrakeSts "VCL-DCL10-38 - This is the signal used by the DCL to notify the VCL about the Parking Brake status";
CM_ SG_ 2499777795 TransmRecovReact "VCL-DCL10-59 - The DCL informs VCL about the effect on the vehicle that is in progress due to an internal recovery status";
CM_ SG_ 2499777795 CltchPedTorqLimSts "VCL-DCL10-41 - This signal is sent in order to notify the clutch coupling percentage";
CM_ SG_ 2499777795 WhRevolSpd "VCL-DCL10-67 - The speed measured contains the rear axle ratio";
CM_ SG_ 2499777795 GndSpdPTO_Sts "VCL-DCL10-325";
CM_ SG_ 2499777795 AgPTO_ShaftTyp "VCL-DCL10-326 - PTO splines detected";
CM_ BO_ 2565867011 "NOTE - Request has to be responded to with as many messages as necessary to transmit all available information.";
CM_ SG_ 2565867011 DiffLckStsCent "VCL-DCL10-179 - State used which indicates the condition of the central differential lock.  The differential locks are located as defined in ...";
CM_ SG_ 2565867011 DiffLckStsRAx_1 "VCL-DCL10-180 - State used which indicates the condition of the rear axle 1 differential lock.  The differential locks are located as defined in ...";
CM_ SG_ 2565867011 DiffLckStsRAx_3 "State used which indicates the condition of the rear axle 3 differential lock. The differential locks are located as defined in figure SPN 564_. [Ed note:  Forum comment resolution is in process.  The figure may need to be updated further and/or if an...";
CM_ SG_ 2565867011 Locat "NOT used. This byte should be filled with 0xFF.To identify to which of several similar devices (such as tires or fuel tanks) the information applies.";
CM_ SG_ 2565867011 DiffLckStsFAx_1 "VCL-DCL10-506 State used which indicates the condition of the front axle 1 differential lock.  The differential locks are located as defined ...";
CM_ SG_ 2565867011 DiffLckStsFAx_2 "NOT used. These bits should be filled with (11)b. State used which indicates the condition of the front axle 2 differential lock. The differential locks are located as defined in ...";
CM_ SG_ 2565867011 DiffLckStsRAx_2 "NOT used. These bits should be filled with (11)b. State used which indicates the condition of the rear axle 2 differential lock.  The differential locks are located as defined in ...";
CM_ SG_ 2565867011 DiffLckStsCentFrnt "NOT used. These bits should be filled with (11)b. State used which indicates the condition of the central front differential lock.  The differential locks are located as defined ...";
CM_ SG_ 2565867011 DiffLckStsCentRear "NOT used. These bits should be filled with (11)b. State used which indicates the condition of the central rear differential lock.  The differential locks are located as defined ...";
CM_ SG_ 2565867011 FAxGrpEngagSts "NOT used. These bits should be filled with (11)b. Front axle group engagement status ...";
CM_ SG_ 2565867011 RAxGrpEngagSts "NOT used. These bits should be filled with (11)b. Rear axle group engagement status ...";
CM_ BO_ 2565344807 "The Acknowledgment PG is used to provide a handshake mechanism between transmitting and receiving devices";
CM_ SG_ 2565344807 PGN_RQST2_27_0E "PGN which is requested by Request2 message";
CM_ SG_ 2565344807 GrpFunctValAck "Group Function of PGN being acknowledged. This field identifies for a device the specific group function of a PGN being acknowledged or declined.  This field is not used if the PGN being acknowledged or declined is not a group function PGN.";
CM_ BO_ 2565475879 "Used to Request a PGN from network device or devices.";
CM_ SG_ 2565475879 PGN_RQST_27_0E "Whenever it is necessary to identify a Parameter Group Number in the data field of a CAN data frame, it will be expressed in 24 bits.";
CM_ SG_ 2499796007 CRPM_Sts "VCL-DCL10-415";
CM_ SG_ 2499796007 RngLckGearReq "This a signal used to request to DEC a specific and fixed gear";
CM_ SG_ 2499796007 InchngFenderDirectCmd "VCL-DCL10-655 - This is signal used to request to the DCL a specific transmission status when the Fender Inching logic is in  enabled mode.";
CM_ SG_ 2499796007 ReqWhSpd "VCL-DCL10-402";
CM_ SG_ 2499796007 WhSpdMaxSetp "VCL-DCL10-401";
CM_ SG_ 2499796007 WhSpdChgReq "VCL-DCL10-403";
CM_ SG_ 2499796007 DecelModeReq "VCL-DCL10-406";
CM_ SG_ 2499796007 ReqWhSpdLvr "VCL-DCL10-458";
CM_ SG_ 2499796007 AccelModeReq "VCL-DCL10-405";
CM_ BO_ 2566877991 "The message contains the checksum about ECU set PGN (0xFF72).";
CM_ SG_ 2566877991 ECU_DatasetChksum "The signal is a chekcusm according algorithm specified into system spec.";
CM_ BO_ 2565473063 "Used to Request a PGN from network device or devices.";
CM_ SG_ 2565473063 PGN_RQST_27_03 "PGN superset list which is requested by Request message";
CM_ BO_ 2565341991 "The Acknowledgment PG is used to provide a handshake mechanism between transmitting and receiving devices";
CM_ SG_ 2565341991 PGN_RQST2_27_03 "PGN which is requested by Request2 message";
CM_ SG_ 2565341991 GrpFunctValAck "Group Function of PGN being acknowledged. This field identifies for a device the specific group function of a PGN being acknowledged or declined.  This field is not used if the PGN being acknowledged or declined is not a group function PGN.";
CM_ BO_ 2566894631 "Not Used on CH26";
CM_ SG_ 2566894631 CalibrStopReason "VCL-DCL10-435 ACM0100 only";
CM_ SG_ 2566894631 CalibrCmd "VCL-DCL10-434 ACM0100 Only";
CM_ SG_ 2566894631 OverspeedLimFactor "ACM0100 only";
CM_ SG_ 2566894631 EngPwr_pc "VCL-DCL10-396, Indicates the percentage relative to the maximum power.";
CM_ BO_ 2566877735 "The message contains the set of data of a specific ECU that are needed to other ECUs.";
CM_ SG_ 2566877735 EngRateSpd "The maximum governed rotational velocity of the engine crankshaft under full load conditions.  Note that the engine ...";
CM_ SG_ 2566877735 EngOverspeedLim "A signal from the UCM to the DEC to communicate the Engine Overspeed Limit";
CM_ SG_ 2566877735 EngAntistlLim "A signal from the UCM to the DEC to communicate the Engine Antistall Limit";
CM_ BO_ 2499798055 "All not used bits must be set at 1. Cycle time must be finalized (default value = 10 ms)";
CM_ SG_ 2499798055 SpecialModeResp "Not used on CH26. Setup with a value !=1 by all the other ECU that is receiving the Rqst information, on the WL SFB and maybe UCM";
CM_ SG_ 2499798055 SpecialModeReq "Not used on CH26. Setup with a value != 7 by each ECU that want to advise that it is starting a special mode, for the WL the display";
CM_ SG_ 2499798055 MsgChksum_4 "Chksum = (Byte1 + (Byte2 & 0x0F) + Byte3 + Byte4 + Byte5 + Byte6 + Byte7 + Bytes8 + msgID byte1 + msgID byte2 + msgID byte3 + msgID byte4)  = (((chksum >> 6) & 0x03) + (chksum >>3) + chksum) & 0x07 = ((chksum & 0x0F) << 4) + (chksum & 0x0F)";
CM_ SG_ 2499798055 KeyPositn "Bitmapped signal that indicates the Key position.";
CM_ SG_ 2499798055 BattMainSwHoldFunct "Managed by ECU performing the Manitain Power. Set to 0xF if not managed";
CM_ SG_ 2499798055 ThisNetReq "Request to hold the net on which the ECU is performing the communication. Set to 11b if not managed";
CM_ SG_ 2499798055 BattMainSwHoldReq "Request to hold the battery main switch.";
CM_ SG_ 2499798055 OpSeatSw "Senses the presence of the operator in the seat. (Satisfies requirement VCL-DCL10-357 only when mapped into PB_Heartbeat_27_03.)";
CM_ SG_ 2499798055 AutoGuideEnaSts "A status signal indicating the activation command sent to a subsystem. On the 'autoguidance' the transition 01->00 doesn't cause a status change (disable command not permitted). If not managed, set to 11b";
CM_ SG_ 2499798055 Hrtbt "Init Value 251; The transmitter will increase the counter in every cycle,  0 to 250 and then wrap.254 Error; 255 NA. Approach Unilateral";
CM_ SG_ 2499798055 WakeUpInDozeMode "Managed by ECU performing the Network Management. Set to 11b if not managed";
CM_ SG_ 2499798055 WakeUpFunct "Managed by ECU performing the Manitain Power. Set to 0xF if not managed";
CM_ SG_ 2499798055 VehMov "Set to 11b if not managed";
CM_ SG_ 2499798055 IgnON "Managed by ECU performing the Network Management. Set to 11b if not managed";
CM_ SG_ 2499798055 EngStartSts "If not managed, set to (11b)";
CM_ SG_ 2499798055 EngRun "Set to 11b if not managed";
CM_ BO_ 2566887975 "Message used to send to DEC some parameters. This message was added after UCM-DEC splitting";
CM_ SG_ 2566887975 EngShaftFanTorq "VCL-DCL10-361 - Only for NAR tractors.  This signal is the estimation of the current torque being consumed by the fan drive and therefore not available at the flywheel";
CM_ SG_ 2566887975 EngHiLimThrsMinContEngRPM_2 "VCL-DCL10-84 - Maximum allowable value for minimum continuous RPM from engine. Engine Lugging";
CM_ SG_ 2566887975 EngMaxContRPM_2 "VCL-DCL10-43 - Applied limit for maximum continuous engine RPM. Engine Set Point Maximum: Max Eng Speed that could be requested by VCL to Engine (via TSC1)";
CM_ SG_ 2566887975 EngMinContRPM_2 "VCL-DCL10-42 - Applied limit for minimum continuous engine RPM. Engine Set Point Minimum: Minimum Engine Speed that could be requested by VCL to Engine (via TSC1).";
CM_ BO_ 2499777319 "Message used to send to DEC some parameters. This message was added after UCM-DEC splitting";
CM_ SG_ 2499777319 KickdnReq "VCL-DCL10-373 - This signal is used to request to the DEC to downshift (if needed) the transmission in order to have the maximum acceleration of the vehicle. It is not used in manual mode";
CM_ SG_ 2499777319 EngDroopMaxReq "VCL-DCL10-370 - This signal is used only when in Auto Field or Auto Road, with PTO ON, to request a maximum droop on the Engine RPM between the requested and the measured.";
CM_ SG_ 2499777319 SmoothShftEna "VCL-DCL10-374 When Enabled, the DEC is not allowed to change RPM to improve drivability.";
CM_ SG_ 2499777319 AntiJckKnifeCmd "VCL-DCL10-372 If activated the DEC will downshift less aggressively.";
CM_ SG_ 2499777319 B2C_Ena "Feedback to the display about the status of Brake to clutch Function";
CM_ SG_ 2499777319 RightBrakeSts "VCL-DCL10-188 - This is the signal used by the VCL to notify the DCL about the Right Brake Pedal status";
CM_ SG_ 2499777319 LeftBrakeSts "VCL-DCL10-188 - This is the signal used by the VCL to notify the DCL about the Left Brake Pedal status";
CM_ SG_ 2499777319 HandBrakeSw "VCL-DCL10-375 satisfied by PB_UCM1_27 on VB2. This parameter is the current status of the handbrake switch input. ";
CM_ SG_ 2499777319 TransmDsrdModeCmd "VCL-DCL10-69 (10-78) - This signal is sent to request to the DCL a specific control mode to manage the Desired Gear requested";
CM_ SG_ 2499777319 Bst_pc "VCL-DCL10-89 - the signal Current Boost Percentage identifies the position of the current torque limit curve with respect to the unboosted (=0%) and boosted (=100%) curves.
Not Used on CH26";
CM_ SG_ 2499777319 DsrdWhRevolSpd "VCL-DCL10-72 (10-80) - wheel revolution speed used as limit for APM (for DCT). used as setpoint for CVT ";
CM_ SG_ 2499777319 CltchPedTorqLim "VCL-DCL10-39 - percentage of the applicable clutch torque";
CM_ SG_ 2499777319 SecBrakeSetp "VCL-DCL10-56 - Secondary brake setpoint";
CM_ BO_ 2348941095 "Transmission Control 1";
CM_ SG_ 2348941095 TransmAutoN_Req "This parameter conveys a vehicle system desire to override the operator’s current shift selector request (e.g. Drive, Reverse) and shift the transmission into Neutral. “Manual Return” indicates this parameter has the ability to initiate a transmission...";
CM_ SG_ 2348941095 TransmGearShftInhReq "Command signal to inhibit gear shifts.";
CM_ SG_ 2348941095 TransmTorqConvLckupDisReq "Command signal to prevent torque converter lockup, which may cause problems in certain circumstances for ASR.";
CM_ SG_ 2348941095 DisengDrvlReq "Command signal used to simply disengage the driveline, e.g., to prevent engine drag torque from causing high wheel slip ...";
CM_ SG_ 2348941095 TransmRevGearShftInhReq "Allows devices external to the normal transmission shift selector system to request the transmission to inhibit shifts into ...";
CM_ SG_ 2348941095 Req_pcCltchSlip "Parameter which represents the percent clutch slip requested by a device: Percent Clutch Slip = ((Engine rpm - Input shaft rpm)/(Engine rpm)) x 100. Clutch Engage Request";
CM_ SG_ 2348941095 TransmReqGear "VCL-DCL10-35 - Gear requested by the operator/VCL.To be used for Direction of Travel request too (F=0xFC, N=0x7D, R=0xDF, P=0xFB).Negative values are reverse gears, positive values are forward gears, zero is neutral";
CM_ SG_ 2348941095 DisengDiffLckReqFAx_1 "VCL-DCL10-635 - Command signal used to disengage the various differential locks, e.g., to allow an undistributed individual wheel control ...";
CM_ SG_ 2348941095 DisengDiffLckReqFAx_2 "Command signal used to disengage the various differential locks, e.g., to allow an undistributed individual wheel control ...";
CM_ SG_ 2348941095 DisengDiffLckReqRAx_1 "VCL-DCL10-177 - Command signal used to disengage the various differential locks, e.g., to allow an undistributed individual wheel control ...";
CM_ SG_ 2348941095 DisengDiffLckReqRAx_2 "Command signal used to disengage the various differential locks, e.g., to allow an undistributed individual wheel control ...";
CM_ SG_ 2348941095 DisengDiffLckReqCent "VCL-DCL10-176 - Command signal used to disengage the various differential locks, e.g., to allow an undistributed individual wheel control ...";
CM_ SG_ 2348941095 DisengDiffLckReqCentFrnt "Command signal used to disengage the various differential locks, e.g., to allow an undistributed individual wheel control ...";
CM_ SG_ 2348941095 DisengDiffLckReqCentRear "Command signal used to disengage the various differential locks, e.g., to allow an undistributed individual wheel control ...";
CM_ SG_ 2348941095 TransmLoadReducInhReq "Request signal to the transmission to inhibit activation of load reduction functions.";
CM_ SG_ 2348941095 TransmMode_1 "Automatic Range Shift Enable. Driveline is able to select the best gear after a range shift.";
CM_ SG_ 2348941095 TransmMode_2 "Control Mode: Autol Mode selection Request";
CM_ SG_ 2348941095 TransmMode_3 "Auto Function Mode: Auto Speed Matching Request";
CM_ SG_ 2348941095 TransmMode_4 "Auto Function Mode: Auto Stand-By Request";
CM_ SG_ 2348941095 TransmReqLaunchGear "Initial gear for the transmission to start out in when the vehicle is launched from a standing stop, as specified by the ...";
CM_ SG_ 2348941095 TransmShftSelDisplayModeSw "Status of the operator’s switch used to ‘toggle’ through multiple display modes of a shift selector display.";
CM_ SG_ 2348941095 TransmMode_5 "Auto Function Mode: Transport Mode ON Request";
CM_ SG_ 2348941095 TransmMode_6 "Auto Function Mode: Auto Upshift Request";
CM_ SG_ 2348941095 TransmMode_7 "Indicates whether transmission mode 7 is enabled. Modes are manufacturer specific and are not necessarily mutually ...";
CM_ SG_ 2348941095 TransmMode_8 "VCL-DCL10-679";
CM_ SG_ 2566852135 MsgChksum_3 "The message checksum is used to verify the signal path from the transmitting device to the receiving device. The message checksum is calculated using the first 7 data bytes, the message counter and the bytes of the message identifier. It is calculated...";
CM_ SG_ 2566852135 MsgCnt "Init Value 12. The transmitter will increase the counter in every cycle,  0 to 11 and then wrap.14 Error, 15 NA. Used to detect situations where the transmitting ECU malfunction repeats the same frame all the time";
CM_ SG_ 2566852135 PneuSupplyPrs "The pneumatic pressure in the main reservoir, sometimes referred to as the wet tank.";
CM_ SG_ 2566852135 ServBrakeCirc_2AirPrs "The pneumatic pressure in the secondary service brake circuit or reservoir, supplying the front axle.";
CM_ SG_ 2566852135 ServBrakeCirc_1AirPrs "The pneumatic pressure in the primary service brake circuit or reservoir, supplying the rear axle.";
CM_ SG_ 2566852135 Park_aoTrailAirPrs "The pneumatic pressure in the circuit or reservoir for the parking brake and/or the trailer supply.";
CM_ SG_ 2566852135 TheoVehSpd "A value of the speed of a machine as calculated from the measured wheel or tail shaft speed. If available from VCM. Out of operating range values are not considered and 0 km/h replacement value is used";
CM_ BO_ 2632711975 "Transport Protocol - Data Transfer";
CM_ SG_ 2632711975 PktDataTPDT "Relevant data for this PGNs unique use.";
CM_ BO_ 2364539943 "Ag: 20 ms time synchronous; CE: 10 ms time synchronous";
CM_ SG_ 2364539943 ActlEng_pcTorqFrac "Additional part of the calculated output torque of the engine, as a percent of the reference engine torque (SPN 544)";
CM_ SG_ 2364539943 EngTorqMode "State signal which indicates which engine or retarder torque mode is currently generating, limiting, or controlling the torque. Other modes are under control of VCM";
CM_ SG_ 2364539943 DrivRqstEng_pcTorq "The requested torque output of the engine by the driver (accelerator pedal), transmitted as inner torque, as a percent of the reference engine torque (SPN 544) Not evaluated by ECM in two box application.";
CM_ SG_ 2364539943 ActlEng_pcTorq "Actual engine – percent torque (related to the maximum positive torque). The calculated output torque of the engine. The data is transmitted as inner torque, as a percent of reference engine torque (SPN 544) 0xFE in case of error";
CM_ SG_ 2364539943 EngSpd "Actual engine speed which is calculated over a minimum crankshaft angle of 720 degrees divided by the number of cylinders. Current engine speed as sensed at crankshaft 0xFE00 in case of error";
CM_ SG_ 2364539943 SA_CntrlDevEngCntrl "The source address of the SAE J1939 device currently controlling the engine. For 2box application: will be only VCM, if it is requesting a positive torque";
CM_ SG_ 2364539943 EngRqst_pcTorq "The requested torque output of the engine (without considering TSC1 requests). The data is transmitted as inner torque, as a percent of reference engine torque (SPN 544)";
CM_ BO_ 2632777511 "Transport Protocol - Connection Management";
CM_ SG_ 2632777511 TotMsgSizeTPCM_RTS "Total message size (in bytes) for BAM message.Total message size (in bytes) for RTS/CTS message.Total message size (in bytes) for RTS/CTS message.";
CM_ SG_ 2632777511 TotNumPktTPCM_RTS "Total number of packets for BAM message.Total number of packets received for RTS/CTS message.Total number of packets for RTS/CTS message.";
CM_ SG_ 2632777511 MaxNumPktTPCM_RTS "Maximum number of packets for RTS/CTS message.";
CM_ SG_ 2632777511 NumPktSentTPCM_CTS "Number of Packets that can be sent (TP.CM_CTS)";
CM_ SG_ 2632777511 NxtPktNumSentTPCM_CTS "Next Packet Number to be sent (TP.CM_CTS)";
CM_ SG_ 2632777511 ConnAbrtReason "Reason for connection abort message.";
CM_ SG_ 2632777511 TotNumPktBAM "Total number of packets for BAM message.Total number of packets received for RTS/CTS message.Total number of packets for RTS/CTS message.";
CM_ SG_ 2632777511 TotMsgSizeBAM "Total message size (in bytes) for BAM message.Total message size (in bytes) for RTS/CTS message.Total message size (in bytes) for RTS/CTS message.";
CM_ SG_ 2632777511 TotMsgSizeEoMA "Total message size (in bytes) for BAM message.Total message size (in bytes) for RTS/CTS message.Total message size (in bytes) for RTS/CTS message.";
CM_ SG_ 2632777511 TotNumPktEoMA "Total number of packets for BAM message.Total number of packets received for RTS/CTS message.Total number of packets for RTS/CTS message.";
BA_DEF_ SG_  "GenSigReceiveSetting" STRING ;
BA_DEF_ SG_  "GenSigPreSetting" STRING ;
BA_DEF_ SG_  "GenSigPreIfSetting" STRING ;
BA_DEF_ SG_  "GenSigPostSetting" STRING ;
BA_DEF_ SG_  "GenSigPostIfSetting" STRING ;
BA_DEF_ SG_  "GenSigEnvVarType" ENUM  "int","float","undef";
BA_DEF_ SG_  "GenSigConditionalSend" STRING ;
BA_DEF_ SG_  "GenSigAutoGenSnd" ENUM  "No","Yes";
BA_DEF_ SG_  "GenSigAutoGenDsp" ENUM  "No","Yes";
BA_DEF_ SG_  "GenSigAssignSetting" STRING ;
BA_DEF_ SG_  "GenSigAltSetting" STRING ;
BA_DEF_ SG_  "SPN_Definition" STRING ;
BA_DEF_ SG_  "External_Reference_decod" STRING ;
BA_DEF_ SG_  "UtilizationOnNetwork" ENUM  "Used","NOT USED";
BA_DEF_ SG_  "CI_RepetitionNum" ENUM  "1","2";
BA_DEF_ SG_  "CI_RepetitionType" ENUM  "NA","1","2","3","4";
BA_DEF_ SG_  "CI_RepetitionComplemented" ENUM  "0","1","vector_leerstring";
BA_DEF_ SG_  "DDI" INT 0 65535;
BA_DEF_ SG_  "CI_FullName" STRING ;
BA_DEF_ SG_  "GenSigTimeoutTime" INT 0 3600000;
BA_DEF_ SG_  "CI_ParId" STRING ;
BA_DEF_ SG_  "CI_SLOT_Name" STRING ;
BA_DEF_ SG_  "CI_ParVersion" STRING ;
BA_DEF_ SG_  "GenSigSendType" ENUM  "Cyclic","OnWrite","OnWriteWithRepetition","OnChange","OnChangeWithRepetition","IfActive","IfActiveWithRepetition","NoSigSendType";
BA_DEF_ SG_  "GenSigInactiveValue" INT 0 2147483647;
BA_DEF_ SG_  "GenSigStartValue" INT 0 2147483647;
BA_DEF_ SG_  "GenSigEVName" STRING ;
BA_DEF_ SG_  "SPN" INT 0 524287;
BA_DEF_ SG_  "SigType" ENUM  "Default","Range","RangeSigned","ASCII","Discrete","Control","ReferencePGN","DTC","StringDelimiter","StringLength","StringLengthControl";
BA_DEF_ SG_  "GenSigILSupport" ENUM  "Yes","No";
BA_DEF_ BO_  "ShowSignals" INT -1 0;
BA_DEF_ BO_  "GroupSignals" INT 1 100;
BA_DEF_ BO_  "PGN_Definition" STRING ;
BA_DEF_ BO_  "External_Reference" STRING ;
BA_DEF_ BO_  "SingleFrame" INT 0 1;
BA_DEF_ BO_  "CI_AllowedLostMessages" ENUM  "NA","0","1","2","3","4";
BA_DEF_ BO_  "CI_AliveTimeout" INT 0 3600000;
BA_DEF_ BO_  "TpJ1939VarDlc" ENUM  "No","Yes";
BA_DEF_ BO_  "CI_ShowSignals" INT -1 0;
BA_DEF_ BO_  "CI_PgVersion" STRING ;
BA_DEF_ BO_  "CI_GroupSignals" INT 1 100;
BA_DEF_ BO_  "DiagUUDTResponse" ENUM  "No","Yes";
BA_DEF_ BO_  "DiagState" ENUM  "No","Yes";
BA_DEF_ BO_  "DiagResponse" ENUM  "No","Yes";
BA_DEF_ BO_  "DiagRequest" ENUM  "No","Yes";
BA_DEF_ BO_  "DiagConnection" INT 0 65535;
BA_DEF_ BO_  "GenMsgNrOfRepetition" INT 0 1000000;
BA_DEF_ BO_  "GenMsgILSupport" ENUM  "No","Yes";
BA_DEF_ BO_  "GenMsgFastOnStart" INT 0 100000;
BA_DEF_ BO_  "GenMsgCycleTimeFast" INT 0 3600000;
BA_DEF_ BO_  "GenMsgStartDelayTime" INT 0 100000;
BA_DEF_ BO_  "GenMsgDelayTime" INT 0 3600000;
BA_DEF_ BO_  "VFrameFormat" ENUM  "StandardCAN","ExtendedCAN","reserved","J1939PG";
BA_DEF_ BO_  "GenMsgCycleTime" INT 0 3600000;
BA_DEF_ BO_  "GenMsgRequestable" INT 0 1;
BA_DEF_ BO_  "GenMsgSendType" ENUM  "cyclic","reserved","cyclicIfActive","reserved","reserved","reserved","reserved","reserved","noMsgSendType";
BA_DEF_DEF_  "GenSigReceiveSetting" "";
BA_DEF_DEF_  "GenSigPreSetting" "";
BA_DEF_DEF_  "GenSigPreIfSetting" "";
BA_DEF_DEF_  "GenSigPostSetting" "";
BA_DEF_DEF_  "GenSigPostIfSetting" "";
BA_DEF_DEF_  "GenSigEnvVarType" "undef";
BA_DEF_DEF_  "GenSigConditionalSend" "";
BA_DEF_DEF_  "GenSigAutoGenSnd" "";
BA_DEF_DEF_  "GenSigAutoGenDsp" "";
BA_DEF_DEF_  "GenSigAssignSetting" "";
BA_DEF_DEF_  "GenSigAltSetting" "";
BA_DEF_DEF_  "SPN_Definition" "";
BA_DEF_DEF_  "External_Reference_decod" "";
BA_DEF_DEF_  "UtilizationOnNetwork" "Used";
BA_DEF_DEF_  "CI_RepetitionNum" "1";
BA_DEF_DEF_  "CI_RepetitionType" "NA";
BA_DEF_DEF_  "CI_RepetitionComplemented" "0";
BA_DEF_DEF_  "DDI" 0;
BA_DEF_DEF_  "CI_FullName" "";
BA_DEF_DEF_  "GenSigTimeoutTime" 0;
BA_DEF_DEF_  "CI_ParId" "";
BA_DEF_DEF_  "CI_SLOT_Name" "0";
BA_DEF_DEF_  "CI_ParVersion" "0";
BA_DEF_DEF_  "GenSigSendType" "NoSigSendType";
BA_DEF_DEF_  "GenSigInactiveValue" 0;
BA_DEF_DEF_  "GenSigStartValue" 0;
BA_DEF_DEF_  "GenSigEVName" "Env@Nodename_@Signame";
BA_DEF_DEF_  "SPN" 0;
BA_DEF_DEF_  "SigType" "Default";
BA_DEF_DEF_  "GenSigILSupport" "Yes";
BA_DEF_DEF_  "ShowSignals" -1;
BA_DEF_DEF_  "GroupSignals" 1;
BA_DEF_DEF_  "PGN_Definition" "N/A";
BA_DEF_DEF_  "External_Reference" "";
BA_DEF_DEF_  "SingleFrame" 1;
BA_DEF_DEF_  "CI_AllowedLostMessages" "NA";
BA_DEF_DEF_  "CI_AliveTimeout" 0;
BA_DEF_DEF_  "TpJ1939VarDlc" "No";
BA_DEF_DEF_  "CI_ShowSignals" -1;
BA_DEF_DEF_  "CI_PgVersion" "0";
BA_DEF_DEF_  "CI_GroupSignals" 1;
BA_DEF_DEF_  "DiagUUDTResponse" "No";
BA_DEF_DEF_  "DiagState" "No";
BA_DEF_DEF_  "DiagResponse" "No";
BA_DEF_DEF_  "DiagRequest" "No";
BA_DEF_DEF_  "DiagConnection" 0;
BA_DEF_DEF_  "GenMsgNrOfRepetition" 0;
BA_DEF_DEF_  "GenMsgILSupport" "Yes";
BA_DEF_DEF_  "GenMsgFastOnStart" 0;
BA_DEF_DEF_  "GenMsgCycleTimeFast" 0;
BA_DEF_DEF_  "GenMsgStartDelayTime" 0;
BA_DEF_DEF_  "GenMsgDelayTime" 1;
BA_DEF_DEF_  "VFrameFormat" "J1939PG";
BA_DEF_DEF_  "GenMsgCycleTime" 0;
BA_DEF_DEF_  "GenMsgRequestable" 0;
BA_DEF_DEF_  "GenMsgSendType" "noMsgSendType";
BA_ "CI_AliveTimeout" BO_ 2365473539 400;
BA_ "GenMsgCycleTime" BO_ 2365473539 100;
BA_ "GenMsgSendType" BO_ 2365473539 0;
BA_ "GenMsgRequestable" BO_ 2566877955 1;
BA_ "CI_PgVersion" BO_ 2565482243 "-1";
BA_ "CI_AliveTimeout" BO_ 2566888451 200;
BA_ "GenMsgCycleTime" BO_ 2566888451 50;
BA_ "GenMsgSendType" BO_ 2566888451 0;
BA_ "CI_AliveTimeout" BO_ 2566894083 800;
BA_ "GenMsgCycleTime" BO_ 2566894083 200;
BA_ "GenMsgSendType" BO_ 2566894083 0;
BA_ "CI_AliveTimeout" BO_ 2499778819 40;
BA_ "GenMsgCycleTime" BO_ 2499778819 10;
BA_ "GenMsgSendType" BO_ 2499778819 0;
BA_ "External_Reference" BO_ 2566842115 "720000";
BA_ "CI_AliveTimeout" BO_ 2566842115 120000;
BA_ "TpJ1939VarDlc" BO_ 2566842115 1;
BA_ "GenMsgCycleTime" BO_ 2566842115 60000;
BA_ "GenMsgSendType" BO_ 2566842115 0;
BA_ "CI_AliveTimeout" BO_ 2566801923 400;
BA_ "GenMsgCycleTime" BO_ 2566801923 100;
BA_ "GenMsgSendType" BO_ 2566801923 0;
BA_ "CI_AllowedLostMessages" BO_ 2348820227 2;
BA_ "CI_AliveTimeout" BO_ 2348820227 80;
BA_ "GenMsgCycleTime" BO_ 2348820227 20;
BA_ "GenMsgSendType" BO_ 2348820227 0;
BA_ "CI_AliveTimeout" BO_ 2499778307 40;
BA_ "GenMsgCycleTime" BO_ 2499778307 10;
BA_ "GenMsgSendType" BO_ 2499778307 0;
BA_ "CI_AliveTimeout" BO_ 2566886915 200;
BA_ "GenMsgCycleTime" BO_ 2566886915 50;
BA_ "GenMsgSendType" BO_ 2566886915 0;
BA_ "CI_AliveTimeout" BO_ 2566887427 2000;
BA_ "GenMsgCycleTime" BO_ 2566887427 500;
BA_ "GenMsgSendType" BO_ 2566887427 0;
BA_ "CI_AliveTimeout" BO_ 2498757891 40;
BA_ "GenMsgCycleTime" BO_ 2498757891 10;
BA_ "GenMsgSendType" BO_ 2498757891 0;
BA_ "External_Reference" BO_ 2566846467 "*";
BA_ "CI_AliveTimeout" BO_ 2566846467 4000;
BA_ "GenMsgCycleTime" BO_ 2566846467 1000;
BA_ "GenMsgSendType" BO_ 2566846467 0;
BA_ "CI_AliveTimeout" BO_ 2364539395 40;
BA_ "GenMsgCycleTime" BO_ 2364539395 10;
BA_ "GenMsgSendType" BO_ 2364539395 0;
BA_ "CI_AliveTimeout" BO_ 2499777795 40;
BA_ "GenMsgCycleTime" BO_ 2499777795 10;
BA_ "GenMsgSendType" BO_ 2499777795 0;
BA_ "CI_AliveTimeout" BO_ 2565867011 2000;
BA_ "GenMsgCycleTime" BO_ 2565867011 500;
BA_ "GenMsgSendType" BO_ 2565867011 0;
BA_ "CI_ShowSignals" BO_ 2565344807 0;
BA_ "CI_PgVersion" BO_ 2565344807 "-1";
BA_ "CI_GroupSignals" BO_ 2565344807 18;
BA_ "TpJ1939VarDlc" BO_ 2565475879 1;
BA_ "CI_GroupSignals" BO_ 2565475879 11;
BA_ "GenMsgRequestable" BO_ 2565475879 1;
BA_ "CI_AliveTimeout" BO_ 2499796007 40;
BA_ "GenMsgCycleTime" BO_ 2499796007 10;
BA_ "GenMsgSendType" BO_ 2499796007 0;
BA_ "CI_GroupSignals" BO_ 2566877991 2;
BA_ "GenMsgRequestable" BO_ 2566877991 1;
BA_ "CI_PgVersion" BO_ 2565473063 "-1";
BA_ "CI_GroupSignals" BO_ 2565473063 10;
BA_ "CI_ShowSignals" BO_ 2565341991 0;
BA_ "CI_PgVersion" BO_ 2565341991 "-1";
BA_ "CI_GroupSignals" BO_ 2565341991 18;
BA_ "CI_AliveTimeout" BO_ 2566894631 400;
BA_ "GenMsgCycleTime" BO_ 2566894631 100;
BA_ "GenMsgSendType" BO_ 2566894631 0;
BA_ "CI_GroupSignals" BO_ 2566877735 2;
BA_ "GenMsgRequestable" BO_ 2566877735 1;
BA_ "CI_AllowedLostMessages" BO_ 2499798055 3;
BA_ "CI_AliveTimeout" BO_ 2499798055 40;
BA_ "CI_GroupSignals" BO_ 2499798055 6;
BA_ "GenMsgCycleTime" BO_ 2499798055 10;
BA_ "GenMsgSendType" BO_ 2499798055 0;
BA_ "CI_AliveTimeout" BO_ 2566887975 200;
BA_ "GenMsgCycleTime" BO_ 2566887975 50;
BA_ "GenMsgSendType" BO_ 2566887975 0;
BA_ "CI_AliveTimeout" BO_ 2499777319 40;
BA_ "GenMsgCycleTime" BO_ 2499777319 10;
BA_ "GenMsgSendType" BO_ 2499777319 0;
BA_ "CI_AliveTimeout" BO_ 2348941095 40;
BA_ "GenMsgCycleTime" BO_ 2348941095 10;
BA_ "GenMsgSendType" BO_ 2348941095 0;
BA_ "GenMsgCycleTime" BO_ 2566852135 100;
BA_ "GenMsgSendType" BO_ 2566852135 0;
BA_ "TpJ1939VarDlc" BO_ 2632711975 1;
BA_ "CI_ShowSignals" BO_ 2632711975 0;
BA_ "CI_AliveTimeout" BO_ 2364539943 40;
BA_ "CI_ShowSignals" BO_ 2364539943 0;
BA_ "CI_PgVersion" BO_ 2364539943 "-1";
BA_ "GenMsgCycleTime" BO_ 2364539943 20;
BA_ "GenMsgSendType" BO_ 2364539943 0;
BA_ "TpJ1939VarDlc" BO_ 2632777511 1;
BA_ "CI_ShowSignals" BO_ 2632777511 0;
BA_ "CI_RepetitionComplemented" SG_ 2365473539 RPTO_EconMode 2;
BA_ "CI_FullName" SG_ 2365473539 RPTO_EconMode "Rear Power Take Off Economy Mode";
BA_ "CI_ParId" SG_ 2365473539 RPTO_EconMode "ESMD_09086";
BA_ "SPN" SG_ 2365473539 RPTO_EconMode 1892;
BA_ "CI_RepetitionComplemented" SG_ 2365473539 RPTO_Engag 2;
BA_ "CI_FullName" SG_ 2365473539 RPTO_Engag "Rear Power Take Off Engagement";
BA_ "CI_ParId" SG_ 2365473539 RPTO_Engag "ESMD_09089";
BA_ "SPN" SG_ 2365473539 RPTO_Engag 2408;
BA_ "CI_RepetitionComplemented" SG_ 2365473539 RPTO_Mode 2;
BA_ "CI_FullName" SG_ 2365473539 RPTO_Mode "Rear Power Take Off Mode";
BA_ "CI_ParId" SG_ 2365473539 RPTO_Mode "ESMD_09093";
BA_ "SPN" SG_ 2365473539 RPTO_Mode 1890;
BA_ "CI_RepetitionComplemented" SG_ 2365473539 RPTO_OutpShaftSpd 2;
BA_ "CI_FullName" SG_ 2365473539 RPTO_OutpShaftSpd "Rear PTO output shaft speed";
BA_ "CI_ParId" SG_ 2365473539 RPTO_OutpShaftSpd "ESMD_09096";
BA_ "SPN" SG_ 2365473539 RPTO_OutpShaftSpd 1883;
BA_ "CI_RepetitionComplemented" SG_ 2365473539 RPTO_ReasonCod 2;
BA_ "CI_FullName" SG_ 2365473539 RPTO_ReasonCod "Rear PTO exit/reason code";
BA_ "CI_ParId" SG_ 2365473539 RPTO_ReasonCod "ESMD_09092";
BA_ "SPN" SG_ 2365473539 RPTO_ReasonCod 5820;
BA_ "CI_RepetitionComplemented" SG_ 2365473539 RPTO_ModeReqSts 2;
BA_ "CI_FullName" SG_ 2365473539 RPTO_ModeReqSts "Rear PTO mode request status";
BA_ "CI_ParId" SG_ 2365473539 RPTO_ModeReqSts "ESMD_09095";
BA_ "SPN" SG_ 2365473539 RPTO_ModeReqSts 5157;
BA_ "CI_RepetitionComplemented" SG_ 2365473539 RPTO_EconModeReqSts 2;
BA_ "CI_FullName" SG_ 2365473539 RPTO_EconModeReqSts "Rear PTO Economy mode request status";
BA_ "CI_ParId" SG_ 2365473539 RPTO_EconModeReqSts "ESMD_09088";
BA_ "SPN" SG_ 2365473539 RPTO_EconModeReqSts 5158;
BA_ "CI_RepetitionComplemented" SG_ 2365473539 RPTO_ShaftSpdLimSts 2;
BA_ "CI_FullName" SG_ 2365473539 RPTO_ShaftSpdLimSts "Rear PTO shaft speed limit status";
BA_ "CI_ParId" SG_ 2365473539 RPTO_ShaftSpdLimSts "ESMD_09099";
BA_ "SPN" SG_ 2365473539 RPTO_ShaftSpdLimSts 5159;
BA_ "CI_RepetitionComplemented" SG_ 2365473539 RPTO_EngagReqSts 2;
BA_ "CI_FullName" SG_ 2365473539 RPTO_EngagReqSts "Rear PTO engagement request status";
BA_ "CI_ParId" SG_ 2365473539 RPTO_EngagReqSts "ESMD_09091";
BA_ "SPN" SG_ 2365473539 RPTO_EngagReqSts 5156;
BA_ "CI_RepetitionComplemented" SG_ 2365473539 RPTO_OutpShaftSpdSetP 2;
BA_ "CI_FullName" SG_ 2365473539 RPTO_OutpShaftSpdSetP "Rear PTO Output Shaft Speed Set Point";
BA_ "CI_ParId" SG_ 2365473539 RPTO_OutpShaftSpdSetP "ESMD_09097";
BA_ "CI_SLOT_Name" SG_ 2365473539 RPTO_OutpShaftSpdSetP "SAEvr01";
BA_ "SPN" SG_ 2365473539 RPTO_OutpShaftSpdSetP 1885;
BA_ "CI_FullName" SG_ 2566877955 ECU_DatasetChksum "ECU dataset Checksum";
BA_ "CI_ParId" SG_ 2566877955 ECU_DatasetChksum "ESMD_23038";
BA_ "CI_SLOT_Name" SG_ 2566877955 ECU_DatasetChksum "SAEct07";
BA_ "SPN" SG_ 2566877955 ECU_DatasetChksum 516612;
BA_ "SigType" SG_ 2566877955 ECU_DatasetChksum 1;
BA_ "CI_FullName" SG_ 2565482243 PGN_RQST_03_27 "Parameter Group Number (RQST)";
BA_ "CI_ParId" SG_ 2565482243 PGN_RQST_03_27 "ESMD_20277";
BA_ "SPN" SG_ 2565482243 PGN_RQST_03_27 2540;
BA_ "SigType" SG_ 2565482243 PGN_RQST_03_27 6;
BA_ "GenSigAutoGenSnd" SG_ 2566888451 SevTransmOverSpdWarn 0;
BA_ "GenSigAutoGenDsp" SG_ 2566888451 SevTransmOverSpdWarn 0;
BA_ "CI_RepetitionNum" SG_ 2566888451 SevTransmOverSpdWarn 1;
BA_ "CI_RepetitionType" SG_ 2566888451 SevTransmOverSpdWarn 3;
BA_ "CI_FullName" SG_ 2566888451 SevTransmOverSpdWarn "Severe Transmission Over Speed Warning";
BA_ "CI_ParId" SG_ 2566888451 SevTransmOverSpdWarn "ESMD_27764";
BA_ "CI_SLOT_Name" SG_ 2566888451 SevTransmOverSpdWarn "SAEbs02";
BA_ "SPN" SG_ 2566888451 SevTransmOverSpdWarn 519707;
BA_ "CI_FullName" SG_ 2566888451 InchngFenderFdbk "Inching by Fender Feedback";
BA_ "CI_ParId" SG_ 2566888451 InchngFenderFdbk "ESMD_20003";
BA_ "CI_SLOT_Name" SG_ 2566888451 InchngFenderFdbk "SAEbs03";
BA_ "SPN" SG_ 2566888451 InchngFenderFdbk 519812;
BA_ "CI_RepetitionNum" SG_ 2566888451 VehSpdSetpFdbk 1;
BA_ "CI_RepetitionType" SG_ 2566888451 VehSpdSetpFdbk 3;
BA_ "CI_FullName" SG_ 2566888451 VehSpdSetpFdbk "Vehicle Speed Setpoint Feedback";
BA_ "CI_ParId" SG_ 2566888451 VehSpdSetpFdbk "ESMD_23675";
BA_ "CI_SLOT_Name" SG_ 2566888451 VehSpdSetpFdbk "CNHvr02";
BA_ "SPN" SG_ 2566888451 VehSpdSetpFdbk 519390;
BA_ "CI_RepetitionNum" SG_ 2566888451 FrntDifflckRecovSts 1;
BA_ "CI_RepetitionType" SG_ 2566888451 FrntDifflckRecovSts 3;
BA_ "CI_FullName" SG_ 2566888451 FrntDifflckRecovSts "Front Difflock Recovery Status";
BA_ "CI_ParId" SG_ 2566888451 FrntDifflckRecovSts "ESMD_23623";
BA_ "CI_SLOT_Name" SG_ 2566888451 FrntDifflckRecovSts "SAEbs02";
BA_ "SPN" SG_ 2566888451 FrntDifflckRecovSts 518650;
BA_ "CI_RepetitionNum" SG_ 2566888451 MFD_RecovSts 1;
BA_ "CI_RepetitionType" SG_ 2566888451 MFD_RecovSts 3;
BA_ "CI_FullName" SG_ 2566888451 MFD_RecovSts "MFD Difflock Recovery Status";
BA_ "CI_ParId" SG_ 2566888451 MFD_RecovSts "ESMD_23624";
BA_ "CI_SLOT_Name" SG_ 2566888451 MFD_RecovSts "SAEbs02";
BA_ "SPN" SG_ 2566888451 MFD_RecovSts 518651;
BA_ "CI_RepetitionNum" SG_ 2566888451 RearDifflckRecovSts 1;
BA_ "CI_RepetitionType" SG_ 2566888451 RearDifflckRecovSts 3;
BA_ "CI_FullName" SG_ 2566888451 RearDifflckRecovSts "Rear Difflock Recovery Status";
BA_ "CI_ParId" SG_ 2566888451 RearDifflckRecovSts "ESMD_23625";
BA_ "CI_SLOT_Name" SG_ 2566888451 RearDifflckRecovSts "SAEbs02";
BA_ "SPN" SG_ 2566888451 RearDifflckRecovSts 518652;
BA_ "CI_RepetitionNum" SG_ 2566888451 AxLubePrsLoWarn 1;
BA_ "CI_RepetitionType" SG_ 2566888451 AxLubePrsLoWarn 3;
BA_ "CI_FullName" SG_ 2566888451 AxLubePrsLoWarn "Axle Lube Pressure Low Warning";
BA_ "CI_ParId" SG_ 2566888451 AxLubePrsLoWarn "ESMD_26238";
BA_ "CI_SLOT_Name" SG_ 2566888451 AxLubePrsLoWarn "SAEbs02";
BA_ "SPN" SG_ 2566888451 AxLubePrsLoWarn 517652;
BA_ "CI_RepetitionNum" SG_ 2566888451 RPTO_RecovReact 1;
BA_ "CI_RepetitionType" SG_ 2566888451 RPTO_RecovReact 3;
BA_ "CI_FullName" SG_ 2566888451 RPTO_RecovReact "RPTO Recovery Reaction";
BA_ "CI_ParId" SG_ 2566888451 RPTO_RecovReact "ESMD_27913";
BA_ "CI_SLOT_Name" SG_ 2566888451 RPTO_RecovReact "SAEbs03";
BA_ "SPN" SG_ 2566888451 RPTO_RecovReact 520325;
BA_ "CI_RepetitionNum" SG_ 2566888451 EngExhBrakeActLim 1;
BA_ "CI_RepetitionType" SG_ 2566888451 EngExhBrakeActLim 3;
BA_ "CI_FullName" SG_ 2566888451 EngExhBrakeActLim "Engine Exhaust Brake Actuator Limit";
BA_ "CI_ParId" SG_ 2566888451 EngExhBrakeActLim "ESMD_23626";
BA_ "CI_SLOT_Name" SG_ 2566888451 EngExhBrakeActLim "SAEpc03";
BA_ "SPN" SG_ 2566888451 EngExhBrakeActLim 517784;
BA_ "CI_RepetitionNum" SG_ 2566888451 ParkChambrPrsLeakWarn 1;
BA_ "CI_RepetitionType" SG_ 2566888451 ParkChambrPrsLeakWarn 3;
BA_ "CI_FullName" SG_ 2566888451 ParkChambrPrsLeakWarn "Park chamber pressure leakage warning";
BA_ "CI_ParId" SG_ 2566888451 ParkChambrPrsLeakWarn "ESMD_23629";
BA_ "CI_SLOT_Name" SG_ 2566888451 ParkChambrPrsLeakWarn "SAEbs02";
BA_ "SPN" SG_ 2566888451 ParkChambrPrsLeakWarn 517978;
BA_ "CI_RepetitionNum" SG_ 2566888451 TransmOverSpd 1;
BA_ "CI_RepetitionType" SG_ 2566888451 TransmOverSpd 3;
BA_ "CI_FullName" SG_ 2566888451 TransmOverSpd "Transmission Over Speed";
BA_ "CI_ParId" SG_ 2566888451 TransmOverSpd "ESMD_23628";
BA_ "CI_SLOT_Name" SG_ 2566888451 TransmOverSpd "SAEbs02";
BA_ "SPN" SG_ 2566888451 TransmOverSpd 517785;
BA_ "CI_RepetitionNum" SG_ 2566888451 SecWhRevolSpd 1;
BA_ "CI_RepetitionType" SG_ 2566888451 SecWhRevolSpd 3;
BA_ "CI_FullName" SG_ 2566888451 SecWhRevolSpd "Second Wheel Revolution Speed";
BA_ "CI_ParId" SG_ 2566888451 SecWhRevolSpd "ESMD_23682";
BA_ "CI_SLOT_Name" SG_ 2566888451 SecWhRevolSpd "CNHvr02";
BA_ "SPN" SG_ 2566888451 SecWhRevolSpd 519539;
BA_ "CI_RepetitionNum" SG_ 2566888451 DrvlOilTempWarn_2 1;
BA_ "CI_RepetitionType" SG_ 2566888451 DrvlOilTempWarn_2 3;
BA_ "CI_FullName" SG_ 2566888451 DrvlOilTempWarn_2 "driveline oil temperature warning 2";
BA_ "CI_ParId" SG_ 2566888451 DrvlOilTempWarn_2 "ESMD_23627";
BA_ "CI_SLOT_Name" SG_ 2566888451 DrvlOilTempWarn_2 "SAEbs02";
BA_ "SPN" SG_ 2566888451 DrvlOilTempWarn_2 517771;
BA_ "CI_FullName" SG_ 2566894083 CalibrSts "Calibration Status";
BA_ "CI_ParId" SG_ 2566894083 CalibrSts "ESMD_28274";
BA_ "CI_SLOT_Name" SG_ 2566894083 CalibrSts "SAEbs04";
BA_ "SPN" SG_ 2566894083 CalibrSts 519636;
BA_ "CI_FullName" SG_ 2566894083 GearRngMinRatio "Gear Range Min Ratio";
BA_ "CI_ParId" SG_ 2566894083 GearRngMinRatio "ESMD_28316";
BA_ "CI_SLOT_Name" SG_ 2566894083 GearRngMinRatio "CNHgr01";
BA_ "SPN" SG_ 2566894083 GearRngMinRatio 519729;
BA_ "CI_RepetitionNum" SG_ 2566894083 EngSpdSetpPTO_RateSpd 1;
BA_ "CI_RepetitionType" SG_ 2566894083 EngSpdSetpPTO_RateSpd 3;
BA_ "CI_FullName" SG_ 2566894083 EngSpdSetpPTO_RateSpd "Engine Speed Setpoint for PTO Rated Speed";
BA_ "CI_ParId" SG_ 2566894083 EngSpdSetpPTO_RateSpd "ESMD_28302";
BA_ "CI_SLOT_Name" SG_ 2566894083 EngSpdSetpPTO_RateSpd "SAEvr01";
BA_ "SPN" SG_ 2566894083 EngSpdSetpPTO_RateSpd 519704;
BA_ "CI_FullName" SG_ 2566894083 RPTO_CalibrProgr "RPTO Calibration Progress";
BA_ "CI_ParId" SG_ 2566894083 RPTO_CalibrProgr "ESMD_28303";
BA_ "CI_SLOT_Name" SG_ 2566894083 RPTO_CalibrProgr "SAEbs04";
BA_ "SPN" SG_ 2566894083 RPTO_CalibrProgr 519705;
BA_ "CI_FullName" SG_ 2566894083 DrvlLubeOilPrsSens "Driveline Lube Oil Pressure Sensor";
BA_ "CI_ParId" SG_ 2566894083 DrvlLubeOilPrsSens "ESMD_23647";
BA_ "CI_SLOT_Name" SG_ 2566894083 DrvlLubeOilPrsSens "SAEpr11";
BA_ "SPN" SG_ 2566894083 DrvlLubeOilPrsSens 519178;
BA_ "CI_FullName" SG_ 2566894083 GearRngMaxRatio "Gear Range Max Ratio";
BA_ "CI_ParId" SG_ 2566894083 GearRngMaxRatio "ESMD_23683";
BA_ "CI_SLOT_Name" SG_ 2566894083 GearRngMaxRatio "CNHgr01";
BA_ "SPN" SG_ 2566894083 GearRngMaxRatio 519729;
BA_ "CI_RepetitionNum" SG_ 2499778819 EngSpdLimReqMaxCont_2 1;
BA_ "CI_RepetitionType" SG_ 2499778819 EngSpdLimReqMaxCont_2 3;
BA_ "CI_FullName" SG_ 2499778819 EngSpdLimReqMaxCont_2 "Engine Speed Limit Request - Maximum Continuous 2";
BA_ "CI_ParId" SG_ 2499778819 EngSpdLimReqMaxCont_2 "ESMD_23613";
BA_ "CI_SLOT_Name" SG_ 2499778819 EngSpdLimReqMaxCont_2 "SAEvr01";
BA_ "SPN" SG_ 2499778819 EngSpdLimReqMaxCont_2 518637;
BA_ "CI_RepetitionNum" SG_ 2499778819 EngSpdLimReqMinCont_2 1;
BA_ "CI_RepetitionType" SG_ 2499778819 EngSpdLimReqMinCont_2 3;
BA_ "CI_FullName" SG_ 2499778819 EngSpdLimReqMinCont_2 "Engine Speed Limit Request - Minimum Continuous 2";
BA_ "CI_ParId" SG_ 2499778819 EngSpdLimReqMinCont_2 "ESMD_23614";
BA_ "CI_SLOT_Name" SG_ 2499778819 EngSpdLimReqMinCont_2 "SAEvr01";
BA_ "SPN" SG_ 2499778819 EngSpdLimReqMinCont_2 518638;
BA_ "CI_RepetitionNum" SG_ 2499778819 LeftBrakePrs 1;
BA_ "CI_RepetitionType" SG_ 2499778819 LeftBrakePrs 3;
BA_ "CI_FullName" SG_ 2499778819 LeftBrakePrs "Left Brake Pressure";
BA_ "CI_ParId" SG_ 2499778819 LeftBrakePrs "ESMD_23608";
BA_ "CI_SLOT_Name" SG_ 2499778819 LeftBrakePrs "SAEpr22";
BA_ "SPN" SG_ 2499778819 LeftBrakePrs 518632;
BA_ "CI_RepetitionNum" SG_ 2499778819 RightBrakePrs 1;
BA_ "CI_RepetitionType" SG_ 2499778819 RightBrakePrs 3;
BA_ "CI_FullName" SG_ 2499778819 RightBrakePrs "Right Brake Pressure";
BA_ "CI_ParId" SG_ 2499778819 RightBrakePrs "ESMD_23609";
BA_ "CI_SLOT_Name" SG_ 2499778819 RightBrakePrs "SAEpr22";
BA_ "SPN" SG_ 2499778819 RightBrakePrs 518633;
BA_ "CI_FullName" SG_ 2566842115 TotPTO_Hour "Total Power Takeoff Hours";
BA_ "CI_ParId" SG_ 2566842115 TotPTO_Hour "ESMD_03437";
BA_ "CI_SLOT_Name" SG_ 2566842115 TotPTO_Hour "SAEtm09";
BA_ "SPN" SG_ 2566842115 TotPTO_Hour 248;
BA_ "CI_RepetitionComplemented" SG_ 2566842115 TotVehHour 2;
BA_ "CI_FullName" SG_ 2566842115 TotVehHour "Total Vehicle Hours";
BA_ "CI_ParId" SG_ 2566842115 TotVehHour "ESMD_03439";
BA_ "CI_SLOT_Name" SG_ 2566842115 TotVehHour "SAEtm09";
BA_ "SPN" SG_ 2566842115 TotVehHour 246;
BA_ "CI_RepetitionNum" SG_ 2566801923 TransmReqGearFdbk 1;
BA_ "CI_RepetitionType" SG_ 2566801923 TransmReqGearFdbk 3;
BA_ "CI_FullName" SG_ 2566801923 TransmReqGearFdbk "Transmission Requested Gear Feedback";
BA_ "CI_ParId" SG_ 2566801923 TransmReqGearFdbk "ESMD_03583";
BA_ "CI_SLOT_Name" SG_ 2566801923 TransmReqGearFdbk "SAEgv01";
BA_ "SPN" SG_ 2566801923 TransmReqGearFdbk 3289;
BA_ "CI_FullName" SG_ 2566801923 TransmMode_9Ind "Transmission Mode 9 Indicator";
BA_ "CI_ParId" SG_ 2566801923 TransmMode_9Ind "ESMD_15669";
BA_ "CI_SLOT_Name" SG_ 2566801923 TransmMode_9Ind "SAEbs02";
BA_ "SPN" SG_ 2566801923 TransmMode_9Ind 6567;
BA_ "CI_FullName" SG_ 2566801923 TransmMode_10Ind "Transmission Mode 10 Indicator";
BA_ "CI_ParId" SG_ 2566801923 TransmMode_10Ind "ESMD_15670";
BA_ "CI_SLOT_Name" SG_ 2566801923 TransmMode_10Ind "SAEbs02";
BA_ "SPN" SG_ 2566801923 TransmMode_10Ind 6568;
BA_ "CI_FullName" SG_ 2566801923 TransmAutoN_Sts "Transmission Auto-Neutral (Manual Return) State";
BA_ "CI_ParId" SG_ 2566801923 TransmAutoN_Sts "ESMD_24010";
BA_ "CI_SLOT_Name" SG_ 2566801923 TransmAutoN_Sts "SAEbs03";
BA_ "SPN" SG_ 2566801923 TransmAutoN_Sts 7696;
BA_ "CI_FullName" SG_ 2566801923 TransmAirSupplyPrsInd "Transmission Air Supply Pressure Indicator";
BA_ "CI_ParId" SG_ 2566801923 TransmAirSupplyPrsInd "ESMD_15668";
BA_ "CI_SLOT_Name" SG_ 2566801923 TransmAirSupplyPrsInd "SAEbs03";
BA_ "SPN" SG_ 2566801923 TransmAirSupplyPrsInd 6566;
BA_ "CI_RepetitionNum" SG_ 2566801923 TransmCurrRngDisplayBlnkSts 1;
BA_ "CI_RepetitionType" SG_ 2566801923 TransmCurrRngDisplayBlnkSts 3;
BA_ "CI_FullName" SG_ 2566801923 TransmCurrRngDisplayBlnkSts "Transmission Current Range Display Blank State";
BA_ "CI_ParId" SG_ 2566801923 TransmCurrRngDisplayBlnkSts "ESMD_03666";
BA_ "CI_SLOT_Name" SG_ 2566801923 TransmCurrRngDisplayBlnkSts "SAEbs02";
BA_ "SPN" SG_ 2566801923 TransmCurrRngDisplayBlnkSts 4176;
BA_ "CI_RepetitionNum" SG_ 2566801923 TransmServInd 1;
BA_ "CI_RepetitionType" SG_ 2566801923 TransmServInd 3;
BA_ "CI_FullName" SG_ 2566801923 TransmServInd "Transmission Service Indicator";
BA_ "CI_ParId" SG_ 2566801923 TransmServInd "ESMD_03589";
BA_ "CI_SLOT_Name" SG_ 2566801923 TransmServInd "SAEbs02";
BA_ "SPN" SG_ 2566801923 TransmServInd 4178;
BA_ "CI_RepetitionNum" SG_ 2566801923 TransmReqRngDisplayBlnkSts 1;
BA_ "CI_RepetitionType" SG_ 2566801923 TransmReqRngDisplayBlnkSts 3;
BA_ "CI_FullName" SG_ 2566801923 TransmReqRngDisplayBlnkSts "Transmission Requested Range Display Blank State";
BA_ "CI_ParId" SG_ 2566801923 TransmReqRngDisplayBlnkSts "ESMD_03667";
BA_ "CI_SLOT_Name" SG_ 2566801923 TransmReqRngDisplayBlnkSts "SAEbs02";
BA_ "SPN" SG_ 2566801923 TransmReqRngDisplayBlnkSts 1850;
BA_ "CI_RepetitionNum" SG_ 2566801923 TransmReqRngDisplayFlashSts 1;
BA_ "CI_RepetitionType" SG_ 2566801923 TransmReqRngDisplayFlashSts 3;
BA_ "CI_FullName" SG_ 2566801923 TransmReqRngDisplayFlashSts "Transmission Requested Range Display Flash State";
BA_ "CI_ParId" SG_ 2566801923 TransmReqRngDisplayFlashSts "ESMD_03668";
BA_ "CI_SLOT_Name" SG_ 2566801923 TransmReqRngDisplayFlashSts "SAEbs02";
BA_ "SPN" SG_ 2566801923 TransmReqRngDisplayFlashSts 1849;
BA_ "CI_RepetitionNum" SG_ 2566801923 TransmReadyBrakeRleas 1;
BA_ "CI_RepetitionType" SG_ 2566801923 TransmReadyBrakeRleas 3;
BA_ "CI_FullName" SG_ 2566801923 TransmReadyBrakeRleas "Transmission Ready for Brake Release";
BA_ "CI_ParId" SG_ 2566801923 TransmReadyBrakeRleas "ESMD_03581";
BA_ "CI_SLOT_Name" SG_ 2566801923 TransmReadyBrakeRleas "SAEbs02";
BA_ "SPN" SG_ 2566801923 TransmReadyBrakeRleas 3086;
BA_ "CI_RepetitionNum" SG_ 2566801923 ActvShftConsleInd 1;
BA_ "CI_RepetitionType" SG_ 2566801923 ActvShftConsleInd 3;
BA_ "CI_FullName" SG_ 2566801923 ActvShftConsleInd "Active Shift Console Indicator";
BA_ "CI_ParId" SG_ 2566801923 ActvShftConsleInd "ESMD_00028";
BA_ "CI_SLOT_Name" SG_ 2566801923 ActvShftConsleInd "SAEbs02";
BA_ "SPN" SG_ 2566801923 ActvShftConsleInd 2945;
BA_ "CI_RepetitionNum" SG_ 2566801923 TransmEngCrkEna 1;
BA_ "CI_RepetitionType" SG_ 2566801923 TransmEngCrkEna 3;
BA_ "CI_FullName" SG_ 2566801923 TransmEngCrkEna "Transmission Engine Crank Enable";
BA_ "CI_ParId" SG_ 2566801923 TransmEngCrkEna "ESMD_03521";
BA_ "CI_SLOT_Name" SG_ 2566801923 TransmEngCrkEna "SAEbs02";
BA_ "SPN" SG_ 2566801923 TransmEngCrkEna 2900;
BA_ "CI_RepetitionNum" SG_ 2566801923 TransmShftInhInd 1;
BA_ "CI_RepetitionType" SG_ 2566801923 TransmShftInhInd 3;
BA_ "CI_FullName" SG_ 2566801923 TransmShftInhInd "Transmission Shift Inhibit Indicator";
BA_ "CI_ParId" SG_ 2566801923 TransmShftInhInd "ESMD_03597";
BA_ "CI_SLOT_Name" SG_ 2566801923 TransmShftInhInd "SAEbs02";
BA_ "SPN" SG_ 2566801923 TransmShftInhInd 1851;
BA_ "CI_RepetitionNum" SG_ 2566801923 TransmMode_4Ind 1;
BA_ "CI_RepetitionType" SG_ 2566801923 TransmMode_4Ind 3;
BA_ "CI_FullName" SG_ 2566801923 TransmMode_4Ind "Transmission Mode 4 Indicator";
BA_ "CI_ParId" SG_ 2566801923 TransmMode_4Ind "ESMD_03552";
BA_ "CI_SLOT_Name" SG_ 2566801923 TransmMode_4Ind "SAEbs02";
BA_ "SPN" SG_ 2566801923 TransmMode_4Ind 2539;
BA_ "CI_RepetitionNum" SG_ 2566801923 TransmMode_3Ind 1;
BA_ "CI_RepetitionType" SG_ 2566801923 TransmMode_3Ind 3;
BA_ "CI_FullName" SG_ 2566801923 TransmMode_3Ind "Transmission Mode 3 Indicator";
BA_ "CI_ParId" SG_ 2566801923 TransmMode_3Ind "ESMD_03550";
BA_ "CI_SLOT_Name" SG_ 2566801923 TransmMode_3Ind "SAEbs02";
BA_ "SPN" SG_ 2566801923 TransmMode_3Ind 2538;
BA_ "CI_RepetitionNum" SG_ 2566801923 TransmMode_2Ind 1;
BA_ "CI_RepetitionType" SG_ 2566801923 TransmMode_2Ind 3;
BA_ "CI_FullName" SG_ 2566801923 TransmMode_2Ind "Transmission Mode 2 Indicator";
BA_ "CI_ParId" SG_ 2566801923 TransmMode_2Ind "ESMD_03548";
BA_ "CI_SLOT_Name" SG_ 2566801923 TransmMode_2Ind "SAEbs02";
BA_ "SPN" SG_ 2566801923 TransmMode_2Ind 2537;
BA_ "CI_RepetitionNum" SG_ 2566801923 TransmMode_1Ind 1;
BA_ "CI_RepetitionType" SG_ 2566801923 TransmMode_1Ind 3;
BA_ "CI_FullName" SG_ 2566801923 TransmMode_1Ind "Transmission Mode 1 Indicator";
BA_ "CI_ParId" SG_ 2566801923 TransmMode_1Ind "ESMD_03546";
BA_ "CI_SLOT_Name" SG_ 2566801923 TransmMode_1Ind "SAEbs02";
BA_ "SPN" SG_ 2566801923 TransmMode_1Ind 2536;
BA_ "CI_RepetitionNum" SG_ 2566801923 TransmMode_5Ind 1;
BA_ "CI_RepetitionType" SG_ 2566801923 TransmMode_5Ind 3;
BA_ "CI_FullName" SG_ 2566801923 TransmMode_5Ind "Transmission Mode 5 Indicator";
BA_ "CI_ParId" SG_ 2566801923 TransmMode_5Ind "ESMD_03554";
BA_ "CI_SLOT_Name" SG_ 2566801923 TransmMode_5Ind "SAEbs02";
BA_ "SPN" SG_ 2566801923 TransmMode_5Ind 4250;
BA_ "CI_RepetitionNum" SG_ 2566801923 TransmMode_6Ind 1;
BA_ "CI_RepetitionType" SG_ 2566801923 TransmMode_6Ind 3;
BA_ "CI_FullName" SG_ 2566801923 TransmMode_6Ind "Transmission Mode 6 Indicator";
BA_ "CI_ParId" SG_ 2566801923 TransmMode_6Ind "ESMD_03556";
BA_ "CI_SLOT_Name" SG_ 2566801923 TransmMode_6Ind "SAEbs02";
BA_ "SPN" SG_ 2566801923 TransmMode_6Ind 4251;
BA_ "CI_RepetitionNum" SG_ 2566801923 TransmMode_7Ind 1;
BA_ "CI_RepetitionType" SG_ 2566801923 TransmMode_7Ind 3;
BA_ "CI_FullName" SG_ 2566801923 TransmMode_7Ind "Transmission Mode 7 Indicator";
BA_ "CI_ParId" SG_ 2566801923 TransmMode_7Ind "ESMD_03558";
BA_ "CI_SLOT_Name" SG_ 2566801923 TransmMode_7Ind "SAEbs02";
BA_ "SPN" SG_ 2566801923 TransmMode_7Ind 4252;
BA_ "CI_RepetitionNum" SG_ 2566801923 TransmMode_8Ind 1;
BA_ "CI_RepetitionType" SG_ 2566801923 TransmMode_8Ind 3;
BA_ "CI_FullName" SG_ 2566801923 TransmMode_8Ind "Transmission Mode 8 Indicator";
BA_ "CI_ParId" SG_ 2566801923 TransmMode_8Ind "ESMD_03560";
BA_ "CI_SLOT_Name" SG_ 2566801923 TransmMode_8Ind "SAEbs02";
BA_ "SPN" SG_ 2566801923 TransmMode_8Ind 4253;
BA_ "CI_RepetitionNum" SG_ 2566801923 TransmRevGearShftInhSts 1;
BA_ "CI_RepetitionType" SG_ 2566801923 TransmRevGearShftInhSts 3;
BA_ "CI_FullName" SG_ 2566801923 TransmRevGearShftInhSts "Transmission Reverse Gear Shift Inhibit Status";
BA_ "CI_ParId" SG_ 2566801923 TransmRevGearShftInhSts "ESMD_03669";
BA_ "CI_SLOT_Name" SG_ 2566801923 TransmRevGearShftInhSts "SAEbs02";
BA_ "SPN" SG_ 2566801923 TransmRevGearShftInhSts 4261;
BA_ "CI_RepetitionNum" SG_ 2566801923 TransmWarnInd 1;
BA_ "CI_RepetitionType" SG_ 2566801923 TransmWarnInd 3;
BA_ "CI_FullName" SG_ 2566801923 TransmWarnInd "Transmission Warning Indicator";
BA_ "CI_ParId" SG_ 2566801923 TransmWarnInd "ESMD_03605";
BA_ "CI_SLOT_Name" SG_ 2566801923 TransmWarnInd "SAEbs02";
BA_ "SPN" SG_ 2566801923 TransmWarnInd 5344;
BA_ "GenSigAutoGenSnd" SG_ 2348820227 EngReqTorqTorqLim 0;
BA_ "GenSigAutoGenDsp" SG_ 2348820227 EngReqTorqTorqLim 0;
BA_ "CI_RepetitionNum" SG_ 2348820227 EngReqTorqTorqLim 1;
BA_ "CI_RepetitionType" SG_ 2348820227 EngReqTorqTorqLim 3;
BA_ "CI_RepetitionComplemented" SG_ 2348820227 EngReqTorqTorqLim 2;
BA_ "CI_FullName" SG_ 2348820227 EngReqTorqTorqLim "Engine Requested Torque/Torque Limit";
BA_ "CI_ParId" SG_ 2348820227 EngReqTorqTorqLim "ESMD_01754";
BA_ "CI_SLOT_Name" SG_ 2348820227 EngReqTorqTorqLim "SAEpc05";
BA_ "SPN" SG_ 2348820227 EngReqTorqTorqLim 518;
BA_ "GenSigAutoGenSnd" SG_ 2348820227 EngReqSpdCntrlCondtn 0;
BA_ "GenSigAutoGenDsp" SG_ 2348820227 EngReqSpdCntrlCondtn 0;
BA_ "CI_RepetitionNum" SG_ 2348820227 EngReqSpdCntrlCondtn 1;
BA_ "CI_RepetitionType" SG_ 2348820227 EngReqSpdCntrlCondtn 3;
BA_ "CI_RepetitionComplemented" SG_ 2348820227 EngReqSpdCntrlCondtn 2;
BA_ "CI_FullName" SG_ 2348820227 EngReqSpdCntrlCondtn "Engine Requested Speed Control Conditions";
BA_ "CI_ParId" SG_ 2348820227 EngReqSpdCntrlCondtn "ESMD_20225";
BA_ "CI_SLOT_Name" SG_ 2348820227 EngReqSpdCntrlCondtn "SAEbs02";
BA_ "SPN" SG_ 2348820227 EngReqSpdCntrlCondtn 696;
BA_ "GenSigAutoGenSnd" SG_ 2348820227 EngOverrideCntrlMode 0;
BA_ "GenSigAutoGenDsp" SG_ 2348820227 EngOverrideCntrlMode 0;
BA_ "CI_RepetitionNum" SG_ 2348820227 EngOverrideCntrlMode 1;
BA_ "CI_RepetitionType" SG_ 2348820227 EngOverrideCntrlMode 3;
BA_ "CI_RepetitionComplemented" SG_ 2348820227 EngOverrideCntrlMode 2;
BA_ "CI_FullName" SG_ 2348820227 EngOverrideCntrlMode "Engine Override Control Mode";
BA_ "CI_ParId" SG_ 2348820227 EngOverrideCntrlMode "ESMD_01721";
BA_ "CI_SLOT_Name" SG_ 2348820227 EngOverrideCntrlMode "SAEbs02";
BA_ "SPN" SG_ 2348820227 EngOverrideCntrlMode 695;
BA_ "GenSigAutoGenSnd" SG_ 2348820227 MsgCnt_2 0;
BA_ "GenSigAutoGenDsp" SG_ 2348820227 MsgCnt_2 0;
BA_ "CI_RepetitionNum" SG_ 2348820227 MsgCnt_2 1;
BA_ "CI_RepetitionType" SG_ 2348820227 MsgCnt_2 3;
BA_ "CI_RepetitionComplemented" SG_ 2348820227 MsgCnt_2 2;
BA_ "CI_FullName" SG_ 2348820227 MsgCnt_2 "Message Counter 2";
BA_ "CI_ParId" SG_ 2348820227 MsgCnt_2 "ESMD_02700";
BA_ "CI_SLOT_Name" SG_ 2348820227 MsgCnt_2 "SAEct08";
BA_ "SPN" SG_ 2348820227 MsgCnt_2 4206;
BA_ "GenSigAutoGenSnd" SG_ 2348820227 EngReqSpdSpdLim 0;
BA_ "GenSigAutoGenDsp" SG_ 2348820227 EngReqSpdSpdLim 0;
BA_ "CI_RepetitionNum" SG_ 2348820227 EngReqSpdSpdLim 1;
BA_ "CI_RepetitionType" SG_ 2348820227 EngReqSpdSpdLim 3;
BA_ "CI_RepetitionComplemented" SG_ 2348820227 EngReqSpdSpdLim 2;
BA_ "CI_FullName" SG_ 2348820227 EngReqSpdSpdLim "Engine Requested Speed/Speed Limit";
BA_ "CI_ParId" SG_ 2348820227 EngReqSpdSpdLim "ESMD_01752";
BA_ "CI_SLOT_Name" SG_ 2348820227 EngReqSpdSpdLim "SAEvr01";
BA_ "SPN" SG_ 2348820227 EngReqSpdSpdLim 898;
BA_ "GenSigAutoGenSnd" SG_ 2348820227 OverrideCntrlModePrio 0;
BA_ "GenSigAutoGenDsp" SG_ 2348820227 OverrideCntrlModePrio 0;
BA_ "CI_RepetitionNum" SG_ 2348820227 OverrideCntrlModePrio 1;
BA_ "CI_RepetitionType" SG_ 2348820227 OverrideCntrlModePrio 3;
BA_ "CI_RepetitionComplemented" SG_ 2348820227 OverrideCntrlModePrio 2;
BA_ "CI_FullName" SG_ 2348820227 OverrideCntrlModePrio "Override Control Mode Priority";
BA_ "CI_ParId" SG_ 2348820227 OverrideCntrlModePrio "ESMD_02826";
BA_ "CI_SLOT_Name" SG_ 2348820227 OverrideCntrlModePrio "SAEbs02";
BA_ "SPN" SG_ 2348820227 OverrideCntrlModePrio 897;
BA_ "GenSigAutoGenSnd" SG_ 2348820227 TSC1_TransmRate 0;
BA_ "GenSigAutoGenDsp" SG_ 2348820227 TSC1_TransmRate 0;
BA_ "CI_RepetitionNum" SG_ 2348820227 TSC1_TransmRate 1;
BA_ "CI_RepetitionType" SG_ 2348820227 TSC1_TransmRate 3;
BA_ "CI_RepetitionComplemented" SG_ 2348820227 TSC1_TransmRate 2;
BA_ "CI_FullName" SG_ 2348820227 TSC1_TransmRate "TSC1 Transmission Rate";
BA_ "CI_ParId" SG_ 2348820227 TSC1_TransmRate "ESMD_03680";
BA_ "CI_SLOT_Name" SG_ 2348820227 TSC1_TransmRate "SAEbs03";
BA_ "SPN" SG_ 2348820227 TSC1_TransmRate 3349;
BA_ "GenSigAutoGenSnd" SG_ 2348820227 TSC1_CntrlPurp 0;
BA_ "GenSigAutoGenDsp" SG_ 2348820227 TSC1_CntrlPurp 0;
BA_ "CI_RepetitionNum" SG_ 2348820227 TSC1_CntrlPurp 1;
BA_ "CI_RepetitionType" SG_ 2348820227 TSC1_CntrlPurp 3;
BA_ "CI_RepetitionComplemented" SG_ 2348820227 TSC1_CntrlPurp 2;
BA_ "CI_FullName" SG_ 2348820227 TSC1_CntrlPurp "TSC1 Control Purpose";
BA_ "CI_ParId" SG_ 2348820227 TSC1_CntrlPurp "ESMD_03679";
BA_ "CI_SLOT_Name" SG_ 2348820227 TSC1_CntrlPurp "SAEbs05";
BA_ "SPN" SG_ 2348820227 TSC1_CntrlPurp 3350;
BA_ "GenSigAutoGenSnd" SG_ 2348820227 EngReqTorqFrac 0;
BA_ "GenSigAutoGenDsp" SG_ 2348820227 EngReqTorqFrac 0;
BA_ "CI_RepetitionNum" SG_ 2348820227 EngReqTorqFrac 1;
BA_ "CI_RepetitionType" SG_ 2348820227 EngReqTorqFrac 3;
BA_ "CI_RepetitionComplemented" SG_ 2348820227 EngReqTorqFrac 2;
BA_ "CI_FullName" SG_ 2348820227 EngReqTorqFrac "Engine Requested Torque (Fractional)";
BA_ "CI_ParId" SG_ 2348820227 EngReqTorqFrac "ESMD_01755";
BA_ "CI_SLOT_Name" SG_ 2348820227 EngReqTorqFrac "SAEpc10";
BA_ "SPN" SG_ 2348820227 EngReqTorqFrac 4191;
BA_ "CI_RepetitionNum" SG_ 2348820227 MsgChksum 1;
BA_ "CI_RepetitionType" SG_ 2348820227 MsgChksum 3;
BA_ "CI_FullName" SG_ 2348820227 MsgChksum "Message Checksum";
BA_ "CI_ParId" SG_ 2348820227 MsgChksum "ESMD_02697";
BA_ "CI_SLOT_Name" SG_ 2348820227 MsgChksum "SAEct08";
BA_ "SPN" SG_ 2348820227 MsgChksum 3690;
BA_ "CI_FullName" SG_ 2499778307 B2C_Sts "B2C Enable";
BA_ "CI_ParId" SG_ 2499778307 B2C_Sts "ESMD_23638";
BA_ "CI_SLOT_Name" SG_ 2499778307 B2C_Sts "SAEbs02";
BA_ "SPN" SG_ 2499778307 B2C_Sts 518318;
BA_ "CI_RepetitionNum" SG_ 2499778307 RPTO_SpdRatioSts 1;
BA_ "CI_RepetitionType" SG_ 2499778307 RPTO_SpdRatioSts 3;
BA_ "CI_FullName" SG_ 2499778307 RPTO_SpdRatioSts "RPTO Speed Ratio Status";
BA_ "CI_ParId" SG_ 2499778307 RPTO_SpdRatioSts "ESMD_23621";
BA_ "CI_SLOT_Name" SG_ 2499778307 RPTO_SpdRatioSts "SAEbs03";
BA_ "SPN" SG_ 2499778307 RPTO_SpdRatioSts 518642;
BA_ "CI_RepetitionNum" SG_ 2499778307 TransmCalibrSts 1;
BA_ "CI_RepetitionType" SG_ 2499778307 TransmCalibrSts 3;
BA_ "CI_FullName" SG_ 2499778307 TransmCalibrSts "Transmission Calibration Status";
BA_ "CI_ParId" SG_ 2499778307 TransmCalibrSts "ESMD_23630";
BA_ "CI_SLOT_Name" SG_ 2499778307 TransmCalibrSts "SAEbs03";
BA_ "SPN" SG_ 2499778307 TransmCalibrSts 518707;
BA_ "CI_RepetitionNum" SG_ 2499778307 ESPTO_CalibrSts 1;
BA_ "CI_RepetitionType" SG_ 2499778307 ESPTO_CalibrSts 3;
BA_ "CI_FullName" SG_ 2499778307 ESPTO_CalibrSts "Electronic Shiftable PTO Calibration Status";
BA_ "CI_ParId" SG_ 2499778307 ESPTO_CalibrSts "ESMD_23619";
BA_ "CI_SLOT_Name" SG_ 2499778307 ESPTO_CalibrSts "SAEbs03";
BA_ "SPN" SG_ 2499778307 ESPTO_CalibrSts 518640;
BA_ "CI_RepetitionNum" SG_ 2499778307 PTO_HydTorq 1;
BA_ "CI_RepetitionType" SG_ 2499778307 PTO_HydTorq 3;
BA_ "CI_FullName" SG_ 2499778307 PTO_HydTorq "PTO Hydraulic Torque";
BA_ "CI_ParId" SG_ 2499778307 PTO_HydTorq "ESMD_20080";
BA_ "CI_SLOT_Name" SG_ 2499778307 PTO_HydTorq "SAEtq02";
BA_ "SPN" SG_ 2499778307 PTO_HydTorq 518697;
BA_ "CI_RepetitionNum" SG_ 2499778307 PBrakeReq 1;
BA_ "CI_RepetitionType" SG_ 2499778307 PBrakeReq 3;
BA_ "CI_FullName" SG_ 2499778307 PBrakeReq "Parking Brake Request";
BA_ "CI_ParId" SG_ 2499778307 PBrakeReq "ESMD_23618";
BA_ "CI_SLOT_Name" SG_ 2499778307 PBrakeReq "SAEbs02";
BA_ "SPN" SG_ 2499778307 PBrakeReq 518639;
BA_ "CI_RepetitionNum" SG_ 2499778307 RPTO_CalibrSts 1;
BA_ "CI_RepetitionType" SG_ 2499778307 RPTO_CalibrSts 3;
BA_ "CI_FullName" SG_ 2499778307 RPTO_CalibrSts "RPTO Calibration Status";
BA_ "CI_ParId" SG_ 2499778307 RPTO_CalibrSts "ESMD_23620";
BA_ "CI_SLOT_Name" SG_ 2499778307 RPTO_CalibrSts "SAEbs03";
BA_ "SPN" SG_ 2499778307 RPTO_CalibrSts 518641;
BA_ "CI_RepetitionNum" SG_ 2499778307 DynFwdAllwGearMax 1;
BA_ "CI_RepetitionType" SG_ 2499778307 DynFwdAllwGearMax 3;
BA_ "CI_FullName" SG_ 2499778307 DynFwdAllwGearMax "Dynamic Forward Allowed Gear Max";
BA_ "CI_ParId" SG_ 2499778307 DynFwdAllwGearMax "ESMD_20021";
BA_ "CI_SLOT_Name" SG_ 2499778307 DynFwdAllwGearMax "SAEgv01";
BA_ "SPN" SG_ 2499778307 DynFwdAllwGearMax 517643;
BA_ "CI_RepetitionNum" SG_ 2499778307 DynFwdAllwGearMin 1;
BA_ "CI_RepetitionType" SG_ 2499778307 DynFwdAllwGearMin 3;
BA_ "CI_FullName" SG_ 2499778307 DynFwdAllwGearMin "Dynamic Forward Allowed Gear Min";
BA_ "CI_ParId" SG_ 2499778307 DynFwdAllwGearMin "ESMD_20022";
BA_ "CI_SLOT_Name" SG_ 2499778307 DynFwdAllwGearMin "SAEgv01";
BA_ "SPN" SG_ 2499778307 DynFwdAllwGearMin 517644;
BA_ "CI_RepetitionNum" SG_ 2499778307 DynRevAllwGearMax 1;
BA_ "CI_RepetitionType" SG_ 2499778307 DynRevAllwGearMax 3;
BA_ "CI_FullName" SG_ 2499778307 DynRevAllwGearMax "Dynamic Reverse Allowed Gear Max";
BA_ "CI_ParId" SG_ 2499778307 DynRevAllwGearMax "ESMD_20024";
BA_ "CI_SLOT_Name" SG_ 2499778307 DynRevAllwGearMax "SAEgv01";
BA_ "SPN" SG_ 2499778307 DynRevAllwGearMax 517655;
BA_ "CI_RepetitionNum" SG_ 2499778307 DynRevAllwGearMin 1;
BA_ "CI_RepetitionType" SG_ 2499778307 DynRevAllwGearMin 3;
BA_ "CI_FullName" SG_ 2499778307 DynRevAllwGearMin "Dynamic Reverse Allowed Gear Min";
BA_ "CI_ParId" SG_ 2499778307 DynRevAllwGearMin "ESMD_20023";
BA_ "CI_SLOT_Name" SG_ 2499778307 DynRevAllwGearMin "SAEgv01";
BA_ "SPN" SG_ 2499778307 DynRevAllwGearMin 517656;
BA_ "CI_RepetitionNum" SG_ 2566886915 Bst_pcReq 1;
BA_ "CI_RepetitionType" SG_ 2566886915 Bst_pcReq 3;
BA_ "CI_FullName" SG_ 2566886915 Bst_pcReq "Boost Percentage request";
BA_ "CI_ParId" SG_ 2566886915 Bst_pcReq "ESMD_20089";
BA_ "CI_SLOT_Name" SG_ 2566886915 Bst_pcReq "SAEpc03";
BA_ "SPN" SG_ 2566886915 Bst_pcReq 518696;
BA_ "CI_RepetitionNum" SG_ 2566886915 DrvlOilPrsWarn 1;
BA_ "CI_RepetitionType" SG_ 2566886915 DrvlOilPrsWarn 3;
BA_ "CI_FullName" SG_ 2566886915 DrvlOilPrsWarn "driveline oil pressure warning";
BA_ "CI_ParId" SG_ 2566886915 DrvlOilPrsWarn "ESMD_20081";
BA_ "CI_SLOT_Name" SG_ 2566886915 DrvlOilPrsWarn "SAEbs03";
BA_ "SPN" SG_ 2566886915 DrvlOilPrsWarn 518698;
BA_ "CI_RepetitionNum" SG_ 2566886915 DrvlOilTempWarn 1;
BA_ "CI_RepetitionType" SG_ 2566886915 DrvlOilTempWarn 3;
BA_ "CI_FullName" SG_ 2566886915 DrvlOilTempWarn "driveline oil temperature warning";
BA_ "CI_ParId" SG_ 2566886915 DrvlOilTempWarn "ESMD_20082";
BA_ "CI_SLOT_Name" SG_ 2566886915 DrvlOilTempWarn "SAEbs03";
BA_ "SPN" SG_ 2566886915 DrvlOilTempWarn 518699;
BA_ "CI_RepetitionNum" SG_ 2566886915 TransmDsrdModeSts 1;
BA_ "CI_RepetitionType" SG_ 2566886915 TransmDsrdModeSts 3;
BA_ "CI_FullName" SG_ 2566886915 TransmDsrdModeSts "Transmission Desired mode Status";
BA_ "CI_ParId" SG_ 2566886915 TransmDsrdModeSts "ESMD_20091";
BA_ "CI_SLOT_Name" SG_ 2566886915 TransmDsrdModeSts "SAEbs04";
BA_ "SPN" SG_ 2566886915 TransmDsrdModeSts 518706;
BA_ "GenSigAutoGenSnd" SG_ 2566886915 EngShutdnReq 0;
BA_ "GenSigAutoGenDsp" SG_ 2566886915 EngShutdnReq 0;
BA_ "CI_RepetitionNum" SG_ 2566886915 EngShutdnReq 1;
BA_ "CI_RepetitionType" SG_ 2566886915 EngShutdnReq 3;
BA_ "CI_FullName" SG_ 2566886915 EngShutdnReq "Engine Shutdown Request";
BA_ "CI_ParId" SG_ 2566886915 EngShutdnReq "ESMD_20162";
BA_ "CI_RepetitionNum" SG_ 2566886915 HydrostatTransmOilPrsWarn 1;
BA_ "CI_RepetitionType" SG_ 2566886915 HydrostatTransmOilPrsWarn 3;
BA_ "CI_FullName" SG_ 2566886915 HydrostatTransmOilPrsWarn "Hydrostatic Transmission oil pressure warning";
BA_ "CI_ParId" SG_ 2566886915 HydrostatTransmOilPrsWarn "ESMD_20079";
BA_ "CI_SLOT_Name" SG_ 2566886915 HydrostatTransmOilPrsWarn "SAEbs03";
BA_ "SPN" SG_ 2566886915 HydrostatTransmOilPrsWarn 518691;
BA_ "CI_RepetitionNum" SG_ 2566886915 SelCltchSts 1;
BA_ "CI_RepetitionType" SG_ 2566886915 SelCltchSts 3;
BA_ "CI_FullName" SG_ 2566886915 SelCltchSts "Selected Clutch Status ";
BA_ "CI_ParId" SG_ 2566886915 SelCltchSts "ESMD_20083";
BA_ "CI_SLOT_Name" SG_ 2566886915 SelCltchSts "SAEbs02";
BA_ "SPN" SG_ 2566886915 SelCltchSts 518700;
BA_ "CI_RepetitionNum" SG_ 2566886915 MachSelDirect 1;
BA_ "CI_RepetitionType" SG_ 2566886915 MachSelDirect 3;
BA_ "CI_FullName" SG_ 2566886915 MachSelDirect "Machine selected direction";
BA_ "CI_ParId" SG_ 2566886915 MachSelDirect "ESMD_08840";
BA_ "SPN" SG_ 2566886915 MachSelDirect 4309;
BA_ "CI_RepetitionNum" SG_ 2566886915 EngTorqLim 1;
BA_ "CI_RepetitionType" SG_ 2566886915 EngTorqLim 3;
BA_ "CI_FullName" SG_ 2566886915 EngTorqLim "Engine Torque Limit";
BA_ "CI_ParId" SG_ 2566886915 EngTorqLim "ESMD_20018";
BA_ "CI_SLOT_Name" SG_ 2566886915 EngTorqLim "SAEtq02";
BA_ "SPN" SG_ 2566886915 EngTorqLim 517661;
BA_ "CI_RepetitionNum" SG_ 2566886915 TransmLubrPrs 1;
BA_ "CI_RepetitionType" SG_ 2566886915 TransmLubrPrs 3;
BA_ "CI_FullName" SG_ 2566886915 TransmLubrPrs "Transmission Lubrication Pressure";
BA_ "CI_ParId" SG_ 2566886915 TransmLubrPrs "ESMD_20025";
BA_ "CI_SLOT_Name" SG_ 2566886915 TransmLubrPrs "SAEpr14";
BA_ "SPN" SG_ 2566886915 TransmLubrPrs 517663;
BA_ "CI_RepetitionNum" SG_ 2566886915 HydrostatTransmFiltClogWarn 1;
BA_ "CI_RepetitionType" SG_ 2566886915 HydrostatTransmFiltClogWarn 3;
BA_ "CI_FullName" SG_ 2566886915 HydrostatTransmFiltClogWarn "Hydrostatic Transmission Filter clogged warning";
BA_ "CI_ParId" SG_ 2566886915 HydrostatTransmFiltClogWarn "ESMD_20084";
BA_ "CI_SLOT_Name" SG_ 2566886915 HydrostatTransmFiltClogWarn "SAEbs03";
BA_ "SPN" SG_ 2566886915 HydrostatTransmFiltClogWarn 518701;
BA_ "CI_RepetitionNum" SG_ 2566886915 TransmLubrPrsWarn 1;
BA_ "CI_RepetitionType" SG_ 2566886915 TransmLubrPrsWarn 3;
BA_ "CI_RepetitionComplemented" SG_ 2566886915 TransmLubrPrsWarn 2;
BA_ "CI_FullName" SG_ 2566886915 TransmLubrPrsWarn "Transmission lubrication pressure warning";
BA_ "CI_ParId" SG_ 2566886915 TransmLubrPrsWarn "ESMD_20026";
BA_ "CI_SLOT_Name" SG_ 2566886915 TransmLubrPrsWarn "SAEbs02";
BA_ "SPN" SG_ 2566886915 TransmLubrPrsWarn 517664;
BA_ "CI_RepetitionNum" SG_ 2566886915 HydTemp 1;
BA_ "CI_RepetitionType" SG_ 2566886915 HydTemp 3;
BA_ "CI_FullName" SG_ 2566886915 HydTemp "Hydraulic Temperature";
BA_ "CI_ParId" SG_ 2566886915 HydTemp "ESMD_02113";
BA_ "CI_SLOT_Name" SG_ 2566886915 HydTemp "SAEtp01";
BA_ "SPN" SG_ 2566886915 HydTemp 1638;
BA_ "CI_RepetitionNum" SG_ 2566887427 FwdWhRevolSpdAllwRngMax 1;
BA_ "CI_RepetitionType" SG_ 2566887427 FwdWhRevolSpdAllwRngMax 3;
BA_ "CI_FullName" SG_ 2566887427 FwdWhRevolSpdAllwRngMax "Forward Wheel Revolution Speed Allowed Range Max";
BA_ "CI_ParId" SG_ 2566887427 FwdWhRevolSpdAllwRngMax "ESMD_20015";
BA_ "SPN" SG_ 2566887427 FwdWhRevolSpdAllwRngMax 517645;
BA_ "CI_RepetitionNum" SG_ 2566887427 RevWhRevolSpdAllwRngMax 1;
BA_ "CI_RepetitionType" SG_ 2566887427 RevWhRevolSpdAllwRngMax 3;
BA_ "CI_FullName" SG_ 2566887427 RevWhRevolSpdAllwRngMax "Reverse Wheel Revolution Speed Allowed Range Max";
BA_ "CI_ParId" SG_ 2566887427 RevWhRevolSpdAllwRngMax "ESMD_20017";
BA_ "SPN" SG_ 2566887427 RevWhRevolSpdAllwRngMax 517657;
BA_ "CI_RepetitionNum" SG_ 2498757891 TransmCurrGear 1;
BA_ "CI_RepetitionType" SG_ 2498757891 TransmCurrGear 3;
BA_ "CI_FullName" SG_ 2498757891 TransmCurrGear "Transmission Current Gear";
BA_ "CI_ParId" SG_ 2498757891 TransmCurrGear "ESMD_03517";
BA_ "CI_SLOT_Name" SG_ 2498757891 TransmCurrGear "SAEgv01";
BA_ "SPN" SG_ 2498757891 TransmCurrGear 523;
BA_ "CI_RepetitionNum" SG_ 2498757891 TransmSelGear 1;
BA_ "CI_RepetitionType" SG_ 2498757891 TransmSelGear 3;
BA_ "CI_FullName" SG_ 2498757891 TransmSelGear "Transmission Selected Gear";
BA_ "CI_ParId" SG_ 2498757891 TransmSelGear "ESMD_03588";
BA_ "CI_SLOT_Name" SG_ 2498757891 TransmSelGear "SAEgv01";
BA_ "SPN" SG_ 2498757891 TransmSelGear 524;
BA_ "CI_RepetitionNum" SG_ 2498757891 TransmActlGearRatio 1;
BA_ "CI_RepetitionType" SG_ 2498757891 TransmActlGearRatio 3;
BA_ "CI_FullName" SG_ 2498757891 TransmActlGearRatio "Transmission Actual Gear Ratio";
BA_ "CI_ParId" SG_ 2498757891 TransmActlGearRatio "ESMD_03514";
BA_ "CI_SLOT_Name" SG_ 2498757891 TransmActlGearRatio "SAEr01";
BA_ "SPN" SG_ 2498757891 TransmActlGearRatio 526;
BA_ "CI_RepetitionNum" SG_ 2498757891 TransmReqRng 1;
BA_ "CI_RepetitionType" SG_ 2498757891 TransmReqRng 3;
BA_ "CI_FullName" SG_ 2498757891 TransmReqRng "Transmission Requested Range";
BA_ "CI_ParId" SG_ 2498757891 TransmReqRng "ESMD_03585";
BA_ "CI_SLOT_Name" SG_ 2498757891 TransmReqRng "SAEatf0002";
BA_ "SPN" SG_ 2498757891 TransmReqRng 162;
BA_ "CI_RepetitionNum" SG_ 2498757891 TransmCurrRng 1;
BA_ "CI_RepetitionType" SG_ 2498757891 TransmCurrRng 3;
BA_ "CI_FullName" SG_ 2498757891 TransmCurrRng "Transmission Current Range";
BA_ "CI_ParId" SG_ 2498757891 TransmCurrRng "ESMD_03518";
BA_ "CI_SLOT_Name" SG_ 2498757891 TransmCurrRng "SAEatf0002";
BA_ "SPN" SG_ 2498757891 TransmCurrRng 163;
BA_ "CI_RepetitionNum" SG_ 2566846467 TransmOilPrs 1;
BA_ "CI_RepetitionType" SG_ 2566846467 TransmOilPrs 3;
BA_ "CI_FullName" SG_ 2566846467 TransmOilPrs "Transmission Oil Pressure";
BA_ "CI_ParId" SG_ 2566846467 TransmOilPrs "ESMD_03573";
BA_ "CI_SLOT_Name" SG_ 2566846467 TransmOilPrs "SAEpr14";
BA_ "SPN" SG_ 2566846467 TransmOilPrs 127;
BA_ "CI_RepetitionNum" SG_ 2566846467 TransmOilTemp_1 1;
BA_ "CI_RepetitionType" SG_ 2566846467 TransmOilTemp_1 3;
BA_ "CI_RepetitionComplemented" SG_ 2566846467 TransmOilTemp_1 2;
BA_ "CI_FullName" SG_ 2566846467 TransmOilTemp_1 "Transmission Oil Temperature 1";
BA_ "CI_ParId" SG_ 2566846467 TransmOilTemp_1 "ESMD_03574";
BA_ "CI_SLOT_Name" SG_ 2566846467 TransmOilTemp_1 "SAEtp02";
BA_ "SPN" SG_ 2566846467 TransmOilTemp_1 177;
BA_ "CI_RepetitionNum" SG_ 2566846467 CltchPrs 1;
BA_ "CI_RepetitionType" SG_ 2566846467 CltchPrs 3;
BA_ "CI_FullName" SG_ 2566846467 CltchPrs "Clutch Pressure";
BA_ "CI_ParId" SG_ 2566846467 CltchPrs "ESMD_00913";
BA_ "CI_SLOT_Name" SG_ 2566846467 CltchPrs "SAEpr14";
BA_ "SPN" SG_ 2566846467 CltchPrs 123;
BA_ "CI_RepetitionNum" SG_ 2566846467 TransmOilLev_1 1;
BA_ "CI_RepetitionType" SG_ 2566846467 TransmOilLev_1 3;
BA_ "CI_FullName" SG_ 2566846467 TransmOilLev_1 "Transmission Oil Level 1";
BA_ "CI_ParId" SG_ 2566846467 TransmOilLev_1 "ESMD_03563";
BA_ "CI_SLOT_Name" SG_ 2566846467 TransmOilLev_1 "SAEpc03";
BA_ "SPN" SG_ 2566846467 TransmOilLev_1 124;
BA_ "CI_RepetitionNum" SG_ 2566846467 TransmFiltDiffPrs 1;
BA_ "CI_RepetitionType" SG_ 2566846467 TransmFiltDiffPrs 3;
BA_ "CI_FullName" SG_ 2566846467 TransmFiltDiffPrs "Transmission Filter Differential Pressure";
BA_ "CI_ParId" SG_ 2566846467 TransmFiltDiffPrs "ESMD_03526";
BA_ "CI_SLOT_Name" SG_ 2566846467 TransmFiltDiffPrs "SAEpr07";
BA_ "SPN" SG_ 2566846467 TransmFiltDiffPrs 126;
BA_ "CI_RepetitionNum" SG_ 2566846467 TransmOilLev_1HiLo 1;
BA_ "CI_RepetitionType" SG_ 2566846467 TransmOilLev_1HiLo 3;
BA_ "CI_FullName" SG_ 2566846467 TransmOilLev_1HiLo "Transmission Oil Level 1 High / Low";
BA_ "CI_ParId" SG_ 2566846467 TransmOilLev_1HiLo "ESMD_03565";
BA_ "CI_SLOT_Name" SG_ 2566846467 TransmOilLev_1HiLo "SAEvm3";
BA_ "SPN" SG_ 2566846467 TransmOilLev_1HiLo 3027;
BA_ "CI_RepetitionNum" SG_ 2566846467 TransmOilLev_1CntdwnTmr 1;
BA_ "CI_RepetitionType" SG_ 2566846467 TransmOilLev_1CntdwnTmr 3;
BA_ "CI_FullName" SG_ 2566846467 TransmOilLev_1CntdwnTmr "Transmission Oil Level 1 Countdown Timer";
BA_ "CI_ParId" SG_ 2566846467 TransmOilLev_1CntdwnTmr "ESMD_03564";
BA_ "CI_SLOT_Name" SG_ 2566846467 TransmOilLev_1CntdwnTmr "SAEbs04";
BA_ "SPN" SG_ 2566846467 TransmOilLev_1CntdwnTmr 3028;
BA_ "CI_RepetitionNum" SG_ 2566846467 TransmOilLev_1MeasSts 1;
BA_ "CI_RepetitionType" SG_ 2566846467 TransmOilLev_1MeasSts 3;
BA_ "CI_FullName" SG_ 2566846467 TransmOilLev_1MeasSts "Transmission Oil Level 1 Measurement Status";
BA_ "CI_ParId" SG_ 2566846467 TransmOilLev_1MeasSts "ESMD_03566";
BA_ "CI_SLOT_Name" SG_ 2566846467 TransmOilLev_1MeasSts "SAEbs04";
BA_ "SPN" SG_ 2566846467 TransmOilLev_1MeasSts 3026;
BA_ "CI_RepetitionNum" SG_ 2364539395 SA_CntrlDevTransmCntrl 1;
BA_ "CI_RepetitionType" SG_ 2364539395 SA_CntrlDevTransmCntrl 3;
BA_ "CI_FullName" SG_ 2364539395 SA_CntrlDevTransmCntrl "Source Address of Controlling Device for Transmission Control";
BA_ "CI_ParId" SG_ 2364539395 SA_CntrlDevTransmCntrl "ESMD_03266";
BA_ "CI_SLOT_Name" SG_ 2364539395 SA_CntrlDevTransmCntrl "SAEsa01";
BA_ "SPN" SG_ 2364539395 SA_CntrlDevTransmCntrl 1482;
BA_ "CI_RepetitionNum" SG_ 2364539395 TransInSpd 1;
BA_ "CI_RepetitionType" SG_ 2364539395 TransInSpd 3;
BA_ "CI_FullName" SG_ 2364539395 TransInSpd "Transmission Input Shaft Speed";
BA_ "CI_ParId" SG_ 2364539395 TransInSpd "ESMD_03535";
BA_ "CI_SLOT_Name" SG_ 2364539395 TransInSpd "SAEvr01";
BA_ "SPN" SG_ 2364539395 TransInSpd 161;
BA_ "CI_RepetitionNum" SG_ 2364539395 TransmDrvlEngag 1;
BA_ "CI_RepetitionType" SG_ 2364539395 TransmDrvlEngag 3;
BA_ "CI_FullName" SG_ 2364539395 TransmDrvlEngag "Transmission Driveline Engaged";
BA_ "CI_ParId" SG_ 2364539395 TransmDrvlEngag "ESMD_03520";
BA_ "CI_SLOT_Name" SG_ 2364539395 TransmDrvlEngag "SAEbs02";
BA_ "SPN" SG_ 2364539395 TransmDrvlEngag 560;
BA_ "CI_RepetitionNum" SG_ 2364539395 TransmTorqConvLckupEngag 1;
BA_ "CI_RepetitionType" SG_ 2364539395 TransmTorqConvLckupEngag 3;
BA_ "CI_FullName" SG_ 2364539395 TransmTorqConvLckupEngag "Transmission Torque Converter Lockup Engaged";
BA_ "CI_ParId" SG_ 2364539395 TransmTorqConvLckupEngag "ESMD_03673";
BA_ "CI_SLOT_Name" SG_ 2364539395 TransmTorqConvLckupEngag "SAEbs02";
BA_ "SPN" SG_ 2364539395 TransmTorqConvLckupEngag 573;
BA_ "CI_RepetitionNum" SG_ 2364539395 TransmShftInProc 1;
BA_ "CI_RepetitionType" SG_ 2364539395 TransmShftInProc 3;
BA_ "CI_FullName" SG_ 2364539395 TransmShftInProc "Transmission Shift In Process";
BA_ "CI_ParId" SG_ 2364539395 TransmShftInProc "ESMD_03598";
BA_ "CI_SLOT_Name" SG_ 2364539395 TransmShftInProc "SAEbs02";
BA_ "SPN" SG_ 2364539395 TransmShftInProc 574;
BA_ "CI_RepetitionNum" SG_ 2364539395 TransmTorqConvLckupTransInProc 1;
BA_ "CI_RepetitionType" SG_ 2364539395 TransmTorqConvLckupTransInProc 3;
BA_ "CI_FullName" SG_ 2364539395 TransmTorqConvLckupTransInProc "Transmission Torque Converter Lockup Transition in Process";
BA_ "CI_ParId" SG_ 2364539395 TransmTorqConvLckupTransInProc "ESMD_03675";
BA_ "CI_SLOT_Name" SG_ 2364539395 TransmTorqConvLckupTransInProc "SAEbs02";
BA_ "SPN" SG_ 2364539395 TransmTorqConvLckupTransInProc 4816;
BA_ "CI_RepetitionNum" SG_ 2364539395 TransOutSpd 1;
BA_ "CI_RepetitionType" SG_ 2364539395 TransOutSpd 3;
BA_ "CI_FullName" SG_ 2364539395 TransOutSpd "Transmission Output Shaft Speed";
BA_ "CI_ParId" SG_ 2364539395 TransOutSpd "ESMD_03577";
BA_ "CI_SLOT_Name" SG_ 2364539395 TransOutSpd "SAEvr01";
BA_ "SPN" SG_ 2364539395 TransOutSpd 191;
BA_ "CI_RepetitionNum" SG_ 2364539395 CltchSlip_pc 1;
BA_ "CI_RepetitionType" SG_ 2364539395 CltchSlip_pc 3;
BA_ "CI_FullName" SG_ 2364539395 CltchSlip_pc "Clutch Slip Percent";
BA_ "CI_ParId" SG_ 2364539395 CltchSlip_pc "ESMD_02860";
BA_ "CI_SLOT_Name" SG_ 2364539395 CltchSlip_pc "SAEpc03";
BA_ "SPN" SG_ 2364539395 CltchSlip_pc 522;
BA_ "CI_RepetitionNum" SG_ 2364539395 EngMomentOverspeedEna 1;
BA_ "CI_RepetitionType" SG_ 2364539395 EngMomentOverspeedEna 3;
BA_ "CI_FullName" SG_ 2364539395 EngMomentOverspeedEna "Engine Momentary Overspeed Enable";
BA_ "CI_ParId" SG_ 2364539395 EngMomentOverspeedEna "ESMD_01694";
BA_ "CI_SLOT_Name" SG_ 2364539395 EngMomentOverspeedEna "SAEbs02";
BA_ "SPN" SG_ 2364539395 EngMomentOverspeedEna 606;
BA_ "CI_RepetitionNum" SG_ 2364539395 ProgveShftDis 1;
BA_ "CI_RepetitionType" SG_ 2364539395 ProgveShftDis 3;
BA_ "CI_FullName" SG_ 2364539395 ProgveShftDis "Progressive Shift Disable";
BA_ "CI_ParId" SG_ 2364539395 ProgveShftDis "ESMD_02900";
BA_ "CI_SLOT_Name" SG_ 2364539395 ProgveShftDis "SAEbs02";
BA_ "SPN" SG_ 2364539395 ProgveShftDis 607;
BA_ "CI_RepetitionNum" SG_ 2364539395 MomentEngMaxPwrEna 1;
BA_ "CI_RepetitionType" SG_ 2364539395 MomentEngMaxPwrEna 3;
BA_ "CI_FullName" SG_ 2364539395 MomentEngMaxPwrEna "Momentary Engine Maximum Power Enable";
BA_ "CI_ParId" SG_ 2364539395 MomentEngMaxPwrEna "ESMD_02718";
BA_ "CI_SLOT_Name" SG_ 2364539395 MomentEngMaxPwrEna "SAEbs02";
BA_ "SPN" SG_ 2364539395 MomentEngMaxPwrEna 5015;
BA_ "CI_RepetitionNum" SG_ 2499777795 EmergBrakeSts 1;
BA_ "CI_RepetitionType" SG_ 2499777795 EmergBrakeSts 3;
BA_ "CI_FullName" SG_ 2499777795 EmergBrakeSts "Emergency Braking Status";
BA_ "CI_ParId" SG_ 2499777795 EmergBrakeSts "ESMD_20004";
BA_ "CI_SLOT_Name" SG_ 2499777795 EmergBrakeSts "SAEpc03";
BA_ "SPN" SG_ 2499777795 EmergBrakeSts 517635;
BA_ "CI_RepetitionNum" SG_ 2499777795 FlywhlTorq 1;
BA_ "CI_RepetitionType" SG_ 2499777795 FlywhlTorq 3;
BA_ "CI_FullName" SG_ 2499777795 FlywhlTorq "Flywheel Torque";
BA_ "CI_ParId" SG_ 2499777795 FlywhlTorq "ESMD_20009";
BA_ "CI_SLOT_Name" SG_ 2499777795 FlywhlTorq "SAEtq01";
BA_ "SPN" SG_ 2499777795 FlywhlTorq 517650;
BA_ "CI_RepetitionNum" SG_ 2499777795 PBrakeRecovSts 1;
BA_ "CI_RepetitionType" SG_ 2499777795 PBrakeRecovSts 3;
BA_ "CI_FullName" SG_ 2499777795 PBrakeRecovSts "Parking Brake Recovery Status";
BA_ "CI_ParId" SG_ 2499777795 PBrakeRecovSts "ESMD_20078";
BA_ "CI_SLOT_Name" SG_ 2499777795 PBrakeRecovSts "SAEbs03";
BA_ "SPN" SG_ 2499777795 PBrakeRecovSts 518690;
BA_ "CI_RepetitionNum" SG_ 2499777795 PBrakeSts 1;
BA_ "CI_RepetitionType" SG_ 2499777795 PBrakeSts 3;
BA_ "CI_FullName" SG_ 2499777795 PBrakeSts "Parking Brake Status";
BA_ "CI_ParId" SG_ 2499777795 PBrakeSts "ESMD_20815";
BA_ "CI_SLOT_Name" SG_ 2499777795 PBrakeSts "SAEbs04";
BA_ "SPN" SG_ 2499777795 PBrakeSts 518692;
BA_ "CI_RepetitionNum" SG_ 2499777795 TransmRecovReact 1;
BA_ "CI_RepetitionType" SG_ 2499777795 TransmRecovReact 3;
BA_ "CI_FullName" SG_ 2499777795 TransmRecovReact "Transmission Recovery Reaction";
BA_ "CI_ParId" SG_ 2499777795 TransmRecovReact "ESMD_20085";
BA_ "CI_SLOT_Name" SG_ 2499777795 TransmRecovReact "SAEbs03";
BA_ "SPN" SG_ 2499777795 TransmRecovReact 518702;
BA_ "CI_RepetitionNum" SG_ 2499777795 CltchPedTorqLimSts 1;
BA_ "CI_RepetitionType" SG_ 2499777795 CltchPedTorqLimSts 3;
BA_ "CI_FullName" SG_ 2499777795 CltchPedTorqLimSts "Clutch Pedal Torque Limit Status";
BA_ "CI_ParId" SG_ 2499777795 CltchPedTorqLimSts "ESMD_20007";
BA_ "SPN" SG_ 2499777795 CltchPedTorqLimSts 517638;
BA_ "CI_RepetitionNum" SG_ 2499777795 WhRevolSpd 1;
BA_ "CI_RepetitionType" SG_ 2499777795 WhRevolSpd 3;
BA_ "CI_FullName" SG_ 2499777795 WhRevolSpd "Wheel Revolution Speed";
BA_ "CI_ParId" SG_ 2499777795 WhRevolSpd "ESMD_20422";
BA_ "SPN" SG_ 2499777795 WhRevolSpd 517639;
BA_ "CI_RepetitionNum" SG_ 2499777795 GndSpdPTO_Sts 1;
BA_ "CI_RepetitionType" SG_ 2499777795 GndSpdPTO_Sts 3;
BA_ "CI_FullName" SG_ 2499777795 GndSpdPTO_Sts "Ground Speed PTO Status";
BA_ "CI_ParId" SG_ 2499777795 GndSpdPTO_Sts "ESMD_20000";
BA_ "CI_SLOT_Name" SG_ 2499777795 GndSpdPTO_Sts "SAEbs02";
BA_ "SPN" SG_ 2499777795 GndSpdPTO_Sts 517649;
BA_ "CI_RepetitionNum" SG_ 2499777795 AgPTO_ShaftTyp 1;
BA_ "CI_RepetitionType" SG_ 2499777795 AgPTO_ShaftTyp 3;
BA_ "CI_FullName" SG_ 2499777795 AgPTO_ShaftTyp "Agricoltural PTO Shaft Type";
BA_ "CI_ParId" SG_ 2499777795 AgPTO_ShaftTyp "ESMD_20001";
BA_ "CI_SLOT_Name" SG_ 2499777795 AgPTO_ShaftTyp "SAEbs04";
BA_ "SPN" SG_ 2499777795 AgPTO_ShaftTyp 517633;
BA_ "CI_RepetitionNum" SG_ 2565867011 DiffLckStsCent 1;
BA_ "CI_RepetitionType" SG_ 2565867011 DiffLckStsCent 3;
BA_ "CI_FullName" SG_ 2565867011 DiffLckStsCent "Differential Lock State - Central";
BA_ "CI_ParId" SG_ 2565867011 DiffLckStsCent "ESMD_01035";
BA_ "CI_SLOT_Name" SG_ 2565867011 DiffLckStsCent "SAEbs02";
BA_ "SPN" SG_ 2565867011 DiffLckStsCent 564;
BA_ "CI_RepetitionNum" SG_ 2565867011 DiffLckStsRAx_1 1;
BA_ "CI_RepetitionType" SG_ 2565867011 DiffLckStsRAx_1 3;
BA_ "CI_FullName" SG_ 2565867011 DiffLckStsRAx_1 "Differential Lock State - Rear Axle 1";
BA_ "CI_ParId" SG_ 2565867011 DiffLckStsRAx_1 "ESMD_01040";
BA_ "CI_SLOT_Name" SG_ 2565867011 DiffLckStsRAx_1 "SAEbs02";
BA_ "SPN" SG_ 2565867011 DiffLckStsRAx_1 569;
BA_ "CI_FullName" SG_ 2565867011 DiffLckStsRAx_3 "Differential Lock State - Rear Axle 3";
BA_ "CI_ParId" SG_ 2565867011 DiffLckStsRAx_3 "ESMD_24030";
BA_ "CI_SLOT_Name" SG_ 2565867011 DiffLckStsRAx_3 "SAEbs02";
BA_ "SPN" SG_ 2565867011 DiffLckStsRAx_3 7716;
BA_ "CI_RepetitionNum" SG_ 2565867011 Locat 1;
BA_ "CI_RepetitionType" SG_ 2565867011 Locat 3;
BA_ "CI_FullName" SG_ 2565867011 Locat "Location";
BA_ "CI_ParId" SG_ 2565867011 Locat "ESMD_02621";
BA_ "CI_SLOT_Name" SG_ 2565867011 Locat "SAEbs08";
BA_ "SPN" SG_ 2565867011 Locat 927;
BA_ "CI_RepetitionNum" SG_ 2565867011 DiffLckStsFAx_1 1;
BA_ "CI_RepetitionType" SG_ 2565867011 DiffLckStsFAx_1 3;
BA_ "CI_FullName" SG_ 2565867011 DiffLckStsFAx_1 "Differential Lock State - Front Axle 1";
BA_ "CI_ParId" SG_ 2565867011 DiffLckStsFAx_1 "ESMD_01038";
BA_ "CI_SLOT_Name" SG_ 2565867011 DiffLckStsFAx_1 "SAEbs02";
BA_ "SPN" SG_ 2565867011 DiffLckStsFAx_1 567;
BA_ "CI_RepetitionNum" SG_ 2565867011 DiffLckStsFAx_2 1;
BA_ "CI_RepetitionType" SG_ 2565867011 DiffLckStsFAx_2 3;
BA_ "CI_FullName" SG_ 2565867011 DiffLckStsFAx_2 "Differential Lock State - Front Axle 2";
BA_ "CI_ParId" SG_ 2565867011 DiffLckStsFAx_2 "ESMD_01039";
BA_ "CI_SLOT_Name" SG_ 2565867011 DiffLckStsFAx_2 "SAEbs02";
BA_ "SPN" SG_ 2565867011 DiffLckStsFAx_2 568;
BA_ "CI_RepetitionNum" SG_ 2565867011 DiffLckStsRAx_2 1;
BA_ "CI_RepetitionType" SG_ 2565867011 DiffLckStsRAx_2 3;
BA_ "CI_FullName" SG_ 2565867011 DiffLckStsRAx_2 "Differential Lock State - Rear Axle 2";
BA_ "CI_ParId" SG_ 2565867011 DiffLckStsRAx_2 "ESMD_01041";
BA_ "CI_SLOT_Name" SG_ 2565867011 DiffLckStsRAx_2 "SAEbs02";
BA_ "SPN" SG_ 2565867011 DiffLckStsRAx_2 570;
BA_ "CI_RepetitionNum" SG_ 2565867011 DiffLckStsCentFrnt 1;
BA_ "CI_RepetitionType" SG_ 2565867011 DiffLckStsCentFrnt 3;
BA_ "CI_FullName" SG_ 2565867011 DiffLckStsCentFrnt "Differential Lock State - Central Front";
BA_ "CI_ParId" SG_ 2565867011 DiffLckStsCentFrnt "ESMD_01036";
BA_ "CI_SLOT_Name" SG_ 2565867011 DiffLckStsCentFrnt "SAEbs02";
BA_ "SPN" SG_ 2565867011 DiffLckStsCentFrnt 565;
BA_ "CI_RepetitionNum" SG_ 2565867011 DiffLckStsCentRear 1;
BA_ "CI_RepetitionType" SG_ 2565867011 DiffLckStsCentRear 3;
BA_ "CI_FullName" SG_ 2565867011 DiffLckStsCentRear "Differential Lock State - Central Rear";
BA_ "CI_ParId" SG_ 2565867011 DiffLckStsCentRear "ESMD_01037";
BA_ "CI_SLOT_Name" SG_ 2565867011 DiffLckStsCentRear "SAEbs02";
BA_ "SPN" SG_ 2565867011 DiffLckStsCentRear 566;
BA_ "CI_RepetitionNum" SG_ 2565867011 FAxGrpEngagSts 1;
BA_ "CI_RepetitionType" SG_ 2565867011 FAxGrpEngagSts 3;
BA_ "CI_FullName" SG_ 2565867011 FAxGrpEngagSts "Front axle group engagement status";
BA_ "CI_ParId" SG_ 2565867011 FAxGrpEngagSts "ESMD_01980";
BA_ "CI_SLOT_Name" SG_ 2565867011 FAxGrpEngagSts "SAEbs02";
BA_ "SPN" SG_ 2565867011 FAxGrpEngagSts 3819;
BA_ "CI_RepetitionNum" SG_ 2565867011 RAxGrpEngagSts 1;
BA_ "CI_RepetitionType" SG_ 2565867011 RAxGrpEngagSts 3;
BA_ "CI_FullName" SG_ 2565867011 RAxGrpEngagSts "Rear axle group engagement status";
BA_ "CI_ParId" SG_ 2565867011 RAxGrpEngagSts "ESMD_02929";
BA_ "CI_SLOT_Name" SG_ 2565867011 RAxGrpEngagSts "SAEbs02";
BA_ "SPN" SG_ 2565867011 RAxGrpEngagSts 3820;
BA_ "CI_FullName" SG_ 2565344807 PGN_RQST2_27_0E "Parameter Group Number (RQST2)";
BA_ "CI_ParId" SG_ 2565344807 PGN_RQST2_27_0E "ESMD_20978";
BA_ "SPN" SG_ 2565344807 PGN_RQST2_27_0E 2574;
BA_ "SigType" SG_ 2565344807 PGN_RQST2_27_0E 6;
BA_ "GenSigAutoGenSnd" SG_ 2565344807 AddrNegAck 0;
BA_ "GenSigAutoGenDsp" SG_ 2565344807 AddrNegAck 0;
BA_ "CI_FullName" SG_ 2565344807 AddrNegAck "Address Negative Acknowledgement";
BA_ "CI_ParId" SG_ 2565344807 AddrNegAck "ESMD_00044";
BA_ "SPN" SG_ 2565344807 AddrNegAck 3291;
BA_ "GenSigAutoGenSnd" SG_ 2565344807 AddrBusy 0;
BA_ "GenSigAutoGenDsp" SG_ 2565344807 AddrBusy 0;
BA_ "CI_FullName" SG_ 2565344807 AddrBusy "Address Busy";
BA_ "CI_ParId" SG_ 2565344807 AddrBusy "ESMD_00043";
BA_ "SPN" SG_ 2565344807 AddrBusy 3293;
BA_ "GenSigAutoGenSnd" SG_ 2565344807 AddrAck 0;
BA_ "GenSigAutoGenDsp" SG_ 2565344807 AddrAck 0;
BA_ "CI_FullName" SG_ 2565344807 AddrAck "Address Acknowledged";
BA_ "CI_ParId" SG_ 2565344807 AddrAck "ESMD_00041";
BA_ "SPN" SG_ 2565344807 AddrAck 3290;
BA_ "GenSigAutoGenSnd" SG_ 2565344807 AddrAccssDeny 0;
BA_ "GenSigAutoGenDsp" SG_ 2565344807 AddrAccssDeny 0;
BA_ "CI_FullName" SG_ 2565344807 AddrAccssDeny "Address Access Denied";
BA_ "CI_ParId" SG_ 2565344807 AddrAccssDeny "ESMD_00040";
BA_ "SPN" SG_ 2565344807 AddrAccssDeny 3292;
BA_ "GenSigAutoGenSnd" SG_ 2565344807 GrpFunctValAck 0;
BA_ "GenSigAutoGenDsp" SG_ 2565344807 GrpFunctValAck 0;
BA_ "CI_RepetitionComplemented" SG_ 2565344807 GrpFunctValAck 2;
BA_ "CI_FullName" SG_ 2565344807 GrpFunctValAck "Group Function Value (ACK)";
BA_ "CI_ParId" SG_ 2565344807 GrpFunctValAck "ESMD_02063";
BA_ "SPN" SG_ 2565344807 GrpFunctValAck 2542;
BA_ "SigType" SG_ 2565344807 GrpFunctValAck 1;
BA_ "GenSigAutoGenSnd" SG_ 2565344807 CByteAckm 0;
BA_ "GenSigAutoGenDsp" SG_ 2565344807 CByteAckm 0;
BA_ "CI_FullName" SG_ 2565344807 CByteAckm "Control Byte (ACKM)";
BA_ "CI_ParId" SG_ 2565344807 CByteAckm "ESMD_00942";
BA_ "SPN" SG_ 2565344807 CByteAckm 2541;
BA_ "SigType" SG_ 2565344807 CByteAckm 1;
BA_ "CI_FullName" SG_ 2565475879 PGN_RQST_27_0E "Parameter Group Number (RQST)";
BA_ "CI_ParId" SG_ 2565475879 PGN_RQST_27_0E "ESMD_20279";
BA_ "SPN" SG_ 2565475879 PGN_RQST_27_0E 2540;
BA_ "CI_FullName" SG_ 2499796007 CRPM_Sts "CRPM Status";
BA_ "CI_ParId" SG_ 2499796007 CRPM_Sts "ESMD_28301";
BA_ "CI_SLOT_Name" SG_ 2499796007 CRPM_Sts "SAEbs02";
BA_ "SPN" SG_ 2499796007 CRPM_Sts 518444;
BA_ "CI_FullName" SG_ 2499796007 RngLckGearReq "Range lock gear request";
BA_ "CI_ParId" SG_ 2499796007 RngLckGearReq "ESMD_23684";
BA_ "CI_SLOT_Name" SG_ 2499796007 RngLckGearReq "SAEbs03";
BA_ "SPN" SG_ 2499796007 RngLckGearReq 519844;
BA_ "CI_FullName" SG_ 2499796007 InchngFenderDirectCmd "Inching by Fender direction command";
BA_ "CI_ParId" SG_ 2499796007 InchngFenderDirectCmd "ESMD_20097";
BA_ "CI_SLOT_Name" SG_ 2499796007 InchngFenderDirectCmd "SAEbs02";
BA_ "SPN" SG_ 2499796007 InchngFenderDirectCmd 519827;
BA_ "CI_FullName" SG_ 2499796007 ReqWhSpd "Requested Wheel Speed";
BA_ "CI_ParId" SG_ 2499796007 ReqWhSpd "ESMD_23665";
BA_ "CI_SLOT_Name" SG_ 2499796007 ReqWhSpd "SAEpc02";
BA_ "SPN" SG_ 2499796007 ReqWhSpd 3042;
BA_ "CI_RepetitionNum" SG_ 2499796007 WhSpdMaxSetp 1;
BA_ "CI_RepetitionType" SG_ 2499796007 WhSpdMaxSetp 3;
BA_ "CI_FullName" SG_ 2499796007 WhSpdMaxSetp "Wheel Speed Max Setpoint";
BA_ "CI_ParId" SG_ 2499796007 WhSpdMaxSetp "ESMD_23664";
BA_ "CI_SLOT_Name" SG_ 2499796007 WhSpdMaxSetp "CNHvr02";
BA_ "SPN" SG_ 2499796007 WhSpdMaxSetp 519347;
BA_ "CI_FullName" SG_ 2499796007 WhSpdChgReq "Wheel Speed Change Request";
BA_ "CI_ParId" SG_ 2499796007 WhSpdChgReq "ESMD_23666";
BA_ "CI_SLOT_Name" SG_ 2499796007 WhSpdChgReq "CNHpc04";
BA_ "SPN" SG_ 2499796007 WhSpdChgReq 519348;
BA_ "CI_FullName" SG_ 2499796007 DecelModeReq "Deceleration Mode Request";
BA_ "CI_ParId" SG_ 2499796007 DecelModeReq "ESMD_23669";
BA_ "CI_SLOT_Name" SG_ 2499796007 DecelModeReq "SAEbs04";
BA_ "CI_FullName" SG_ 2499796007 ReqWhSpdLvr "Requested Wheel Speed Lever";
BA_ "CI_ParId" SG_ 2499796007 ReqWhSpdLvr "ESMD_28315";
BA_ "CI_SLOT_Name" SG_ 2499796007 ReqWhSpdLvr "SAEpc02";
BA_ "SPN" SG_ 2499796007 ReqWhSpdLvr 519728;
BA_ "CI_FullName" SG_ 2499796007 AccelModeReq "Acceleration Mode Request";
BA_ "CI_ParId" SG_ 2499796007 AccelModeReq "ESMD_23668";
BA_ "CI_SLOT_Name" SG_ 2499796007 AccelModeReq "SAEbs04";
BA_ "SPN" SG_ 2499796007 AccelModeReq 519350;
BA_ "CI_FullName" SG_ 2499796007 GPTO_EngagCmd "Ground Power Take Off Engagement Command";
BA_ "CI_ParId" SG_ 2499796007 GPTO_EngagCmd "NWD-1659";
BA_ "CI_SLOT_Name" SG_ 2499796007 GPTO_EngagCmd "SAEbs02";
BA_ "SPN" SG_ 2499796007 GPTO_EngagCmd 522008;
BA_ "CI_FullName" SG_ 2566877991 ECU_DatasetChksum "ECU dataset Checksum";
BA_ "CI_ParId" SG_ 2566877991 ECU_DatasetChksum "ESMD_23038";
BA_ "CI_SLOT_Name" SG_ 2566877991 ECU_DatasetChksum "SAEct07";
BA_ "SPN" SG_ 2566877991 ECU_DatasetChksum 516612;
BA_ "SigType" SG_ 2566877991 ECU_DatasetChksum 1;
BA_ "CI_FullName" SG_ 2565473063 PGN_RQST_27_03 "Parameter Group Number (RQST)";
BA_ "CI_ParId" SG_ 2565473063 PGN_RQST_27_03 "ESMD_20276";
BA_ "SPN" SG_ 2565473063 PGN_RQST_27_03 2540;
BA_ "SigType" SG_ 2565473063 PGN_RQST_27_03 6;
BA_ "CI_FullName" SG_ 2565341991 PGN_RQST2_27_03 "Parameter Group Number (RQST2)";
BA_ "CI_ParId" SG_ 2565341991 PGN_RQST2_27_03 "ESMD_20973";
BA_ "SPN" SG_ 2565341991 PGN_RQST2_27_03 2574;
BA_ "SigType" SG_ 2565341991 PGN_RQST2_27_03 6;
BA_ "GenSigAutoGenSnd" SG_ 2565341991 AddrNegAck 0;
BA_ "GenSigAutoGenDsp" SG_ 2565341991 AddrNegAck 0;
BA_ "CI_FullName" SG_ 2565341991 AddrNegAck "Address Negative Acknowledgement";
BA_ "CI_ParId" SG_ 2565341991 AddrNegAck "ESMD_00044";
BA_ "SPN" SG_ 2565341991 AddrNegAck 3291;
BA_ "GenSigAutoGenSnd" SG_ 2565341991 AddrBusy 0;
BA_ "GenSigAutoGenDsp" SG_ 2565341991 AddrBusy 0;
BA_ "CI_FullName" SG_ 2565341991 AddrBusy "Address Busy";
BA_ "CI_ParId" SG_ 2565341991 AddrBusy "ESMD_00043";
BA_ "SPN" SG_ 2565341991 AddrBusy 3293;
BA_ "GenSigAutoGenSnd" SG_ 2565341991 AddrAck 0;
BA_ "GenSigAutoGenDsp" SG_ 2565341991 AddrAck 0;
BA_ "CI_FullName" SG_ 2565341991 AddrAck "Address Acknowledged";
BA_ "CI_ParId" SG_ 2565341991 AddrAck "ESMD_00041";
BA_ "SPN" SG_ 2565341991 AddrAck 3290;
BA_ "GenSigAutoGenSnd" SG_ 2565341991 AddrAccssDeny 0;
BA_ "GenSigAutoGenDsp" SG_ 2565341991 AddrAccssDeny 0;
BA_ "CI_FullName" SG_ 2565341991 AddrAccssDeny "Address Access Denied";
BA_ "CI_ParId" SG_ 2565341991 AddrAccssDeny "ESMD_00040";
BA_ "SPN" SG_ 2565341991 AddrAccssDeny 3292;
BA_ "GenSigAutoGenSnd" SG_ 2565341991 GrpFunctValAck 0;
BA_ "GenSigAutoGenDsp" SG_ 2565341991 GrpFunctValAck 0;
BA_ "CI_RepetitionComplemented" SG_ 2565341991 GrpFunctValAck 2;
BA_ "CI_FullName" SG_ 2565341991 GrpFunctValAck "Group Function Value (ACK)";
BA_ "CI_ParId" SG_ 2565341991 GrpFunctValAck "ESMD_02063";
BA_ "SPN" SG_ 2565341991 GrpFunctValAck 2542;
BA_ "SigType" SG_ 2565341991 GrpFunctValAck 1;
BA_ "GenSigAutoGenSnd" SG_ 2565341991 CByteAckm 0;
BA_ "GenSigAutoGenDsp" SG_ 2565341991 CByteAckm 0;
BA_ "CI_FullName" SG_ 2565341991 CByteAckm "Control Byte (ACKM)";
BA_ "CI_ParId" SG_ 2565341991 CByteAckm "ESMD_00942";
BA_ "SPN" SG_ 2565341991 CByteAckm 2541;
BA_ "SigType" SG_ 2565341991 CByteAckm 1;
BA_ "CI_FullName" SG_ 2566894631 VehPerfMode "Vehicle Performance Mode";
BA_ "CI_ParId" SG_ 2566894631 VehPerfMode "NWD-3024";
BA_ "CI_SLOT_Name" SG_ 2566894631 VehPerfMode "SAEbs03";
BA_ "SPN" SG_ 2566894631 VehPerfMode 10295;
BA_ "CI_FullName" SG_ 2566894631 PTO_AntiPitchEna "PTO Anti Pitch Enable";
BA_ "CI_ParId" SG_ 2566894631 PTO_AntiPitchEna "NW-2515";
BA_ "CI_SLOT_Name" SG_ 2566894631 PTO_AntiPitchEna "SAEbs02";
BA_ "SPN" SG_ 2566894631 PTO_AntiPitchEna 520541;
BA_ "CI_FullName" SG_ 2566894631 CalibrStopReason "Calibration Stop Reason";
BA_ "CI_ParId" SG_ 2566894631 CalibrStopReason "ESMD_28276";
BA_ "CI_SLOT_Name" SG_ 2566894631 CalibrStopReason "SAEbs04";
BA_ "SPN" SG_ 2566894631 CalibrStopReason 519638;
BA_ "CI_FullName" SG_ 2566894631 CalibrCmd "Calibration Command";
BA_ "CI_ParId" SG_ 2566894631 CalibrCmd "ESMD_28275";
BA_ "CI_SLOT_Name" SG_ 2566894631 CalibrCmd "SAEbs03";
BA_ "SPN" SG_ 2566894631 CalibrCmd 519637;
BA_ "CI_FullName" SG_ 2566894631 OverspeedLimFactor "Overspeed Limit Factor";
BA_ "CI_ParId" SG_ 2566894631 OverspeedLimFactor "ESMD_23687";
BA_ "CI_SLOT_Name" SG_ 2566894631 OverspeedLimFactor "CNHr01";
BA_ "SPN" SG_ 2566894631 OverspeedLimFactor 520090;
BA_ "CI_FullName" SG_ 2566894631 EngPwr_pc "Engine Power Percentage";
BA_ "CI_ParId" SG_ 2566894631 EngPwr_pc "ESMD_21566";
BA_ "CI_SLOT_Name" SG_ 2566894631 EngPwr_pc "SAEpc06";
BA_ "SPN" SG_ 2566894631 EngPwr_pc 518358;
BA_ "CI_ParId" SG_ 2566894631 TransmDsrdSubmodeCmd "NWD-1663";
BA_ "CI_SLOT_Name" SG_ 2566894631 TransmDsrdSubmodeCmd "SAEbs03";
BA_ "SPN" SG_ 2566894631 TransmDsrdSubmodeCmd 522009;
BA_ "CI_FullName" SG_ 2566877735 RAxRatio "Rear Axle Ratio";
BA_ "CI_ParId" SG_ 2566877735 RAxRatio "NWD-1895";
BA_ "CI_SLOT_Name" SG_ 2566877735 RAxRatio "SAEbs04";
BA_ "SPN" SG_ 2566877735 RAxRatio 522484;
BA_ "CI_FullName" SG_ 2566877735 FrntBrakeOpt "Front Brake Option";
BA_ "CI_ParId" SG_ 2566877735 FrntBrakeOpt "NWD-1742";
BA_ "CI_SLOT_Name" SG_ 2566877735 FrntBrakeOpt "SAEbs02";
BA_ "SPN" SG_ 2566877735 FrntBrakeOpt 522360;
BA_ "CI_FullName" SG_ 2566877735 BrandDiff "Brand Differentiation";
BA_ "CI_ParId" SG_ 2566877735 BrandDiff "NWD-1294";
BA_ "CI_SLOT_Name" SG_ 2566877735 BrandDiff "SAEbs03";
BA_ "SPN" SG_ 2566877735 BrandDiff 522099;
BA_ "CI_FullName" SG_ 2566877735 Brand "Brand";
BA_ "CI_ParId" SG_ 2566877735 Brand "NW-2641";
BA_ "CI_SLOT_Name" SG_ 2566877735 Brand "SAEbs03";
BA_ "SPN" SG_ 2566877735 Brand 519000;
BA_ "CI_FullName" SG_ 2566877735 EngRateSpd "Engine Rated Speed";
BA_ "CI_ParId" SG_ 2566877735 EngRateSpd "ESMD_01746";
BA_ "CI_SLOT_Name" SG_ 2566877735 EngRateSpd "SAEvr01";
BA_ "SPN" SG_ 2566877735 EngRateSpd 189;
BA_ "CI_FullName" SG_ 2566877735 EngOverspeedLim "Engine Overspeed Limit";
BA_ "CI_ParId" SG_ 2566877735 EngOverspeedLim "ESMD_26968";
BA_ "CI_SLOT_Name" SG_ 2566877735 EngOverspeedLim "SAEvr06";
BA_ "SPN" SG_ 2566877735 EngOverspeedLim 519251;
BA_ "CI_FullName" SG_ 2566877735 EngAntistlLim "Engine Antistall Limit";
BA_ "CI_ParId" SG_ 2566877735 EngAntistlLim "ESMD_26969";
BA_ "CI_SLOT_Name" SG_ 2566877735 EngAntistlLim "SAEvr06";
BA_ "SPN" SG_ 2566877735 EngAntistlLim 519252;
BA_ "CI_FullName" SG_ 2566877735 ECU_DatasetInfoMapId "ECU dataset - Information mapping ID";
BA_ "CI_ParId" SG_ 2566877735 ECU_DatasetInfoMapId "ESMD_23037";
BA_ "CI_SLOT_Name" SG_ 2566877735 ECU_DatasetInfoMapId "SAEid01";
BA_ "SPN" SG_ 2566877735 ECU_DatasetInfoMapId 516611;
BA_ "SigType" SG_ 2566877735 ECU_DatasetInfoMapId 1;
BA_ "CI_FullName" SG_ 2499798055 SpecialModeResp "Special Mode Response";
BA_ "CI_ParId" SG_ 2499798055 SpecialModeResp "ESMD_20020";
BA_ "CI_SLOT_Name" SG_ 2499798055 SpecialModeResp "";
BA_ "GenSigStartValue" SG_ 2499798055 SpecialModeResp 1;
BA_ "SPN" SG_ 2499798055 SpecialModeResp 522813;
BA_ "CI_FullName" SG_ 2499798055 SpecialModeReq "Special Mode Request";
BA_ "CI_ParId" SG_ 2499798055 SpecialModeReq "ESMD_20019";
BA_ "GenSigStartValue" SG_ 2499798055 SpecialModeReq 7;
BA_ "SPN" SG_ 2499798055 SpecialModeReq 522812;
BA_ "GenSigAutoGenSnd" SG_ 2499798055 MsgChksum_4 0;
BA_ "GenSigAutoGenDsp" SG_ 2499798055 MsgChksum_4 0;
BA_ "CI_RepetitionNum" SG_ 2499798055 MsgChksum_4 1;
BA_ "CI_RepetitionType" SG_ 2499798055 MsgChksum_4 3;
BA_ "CI_RepetitionComplemented" SG_ 2499798055 MsgChksum_4 2;
BA_ "CI_FullName" SG_ 2499798055 MsgChksum_4 "Message Checksum 4";
BA_ "CI_ParId" SG_ 2499798055 MsgChksum_4 "ESMD_22124";
BA_ "CI_SLOT_Name" SG_ 2499798055 MsgChksum_4 "SAEct08";
BA_ "GenSigStartValue" SG_ 2499798055 MsgChksum_4 15;
BA_ "SPN" SG_ 2499798055 MsgChksum_4 518268;
BA_ "CI_FullName" SG_ 2499798055 KeyPositn "Key Position";
BA_ "CI_ParId" SG_ 2499798055 KeyPositn "ESMD_22053";
BA_ "CI_SLOT_Name" SG_ 2499798055 KeyPositn "SAEbs08";
BA_ "GenSigStartValue" SG_ 2499798055 KeyPositn 255;
BA_ "SPN" SG_ 2499798055 KeyPositn 518023;
BA_ "CI_FullName" SG_ 2499798055 BattMainSwHoldFunct "Battery Main Switch Hold Function";
BA_ "CI_ParId" SG_ 2499798055 BattMainSwHoldFunct "ESMD_22054";
BA_ "CI_SLOT_Name" SG_ 2499798055 BattMainSwHoldFunct "SAEbs04";
BA_ "GenSigStartValue" SG_ 2499798055 BattMainSwHoldFunct 15;
BA_ "SPN" SG_ 2499798055 BattMainSwHoldFunct 518160;
BA_ "CI_FullName" SG_ 2499798055 ThisNetReq "This Net Request";
BA_ "CI_ParId" SG_ 2499798055 ThisNetReq "ESMD_22066";
BA_ "CI_SLOT_Name" SG_ 2499798055 ThisNetReq "SAEbs02";
BA_ "SPN" SG_ 2499798055 ThisNetReq 518162;
BA_ "CI_FullName" SG_ 2499798055 BattMainSwHoldReq "Battery Main Switch Hold Request";
BA_ "CI_ParId" SG_ 2499798055 BattMainSwHoldReq "ESMD_00776";
BA_ "CI_SLOT_Name" SG_ 2499798055 BattMainSwHoldReq "SAEbs02";
BA_ "SPN" SG_ 2499798055 BattMainSwHoldReq 1682;
BA_ "CI_RepetitionNum" SG_ 2499798055 OpSeatSw 1;
BA_ "CI_RepetitionType" SG_ 2499798055 OpSeatSw 3;
BA_ "CI_FullName" SG_ 2499798055 OpSeatSw "Operator Seat Switch";
BA_ "CI_ParId" SG_ 2499798055 OpSeatSw "ESMD_03848";
BA_ "CI_SLOT_Name" SG_ 2499798055 OpSeatSw "SAEbs02";
BA_ "GenSigStartValue" SG_ 2499798055 OpSeatSw 3;
BA_ "SPN" SG_ 2499798055 OpSeatSw 1504;
BA_ "CI_FullName" SG_ 2499798055 AutoGuideEnaSts "Auto Guidance Enable Status";
BA_ "CI_ParId" SG_ 2499798055 AutoGuideEnaSts "ESMD_20027";
BA_ "CI_SLOT_Name" SG_ 2499798055 AutoGuideEnaSts "SAEbs02";
BA_ "GenSigStartValue" SG_ 2499798055 AutoGuideEnaSts 3;
BA_ "SPN" SG_ 2499798055 AutoGuideEnaSts 517677;
BA_ "GenSigAutoGenSnd" SG_ 2499798055 Hrtbt 0;
BA_ "GenSigAutoGenDsp" SG_ 2499798055 Hrtbt 0;
BA_ "CI_RepetitionNum" SG_ 2499798055 Hrtbt 1;
BA_ "CI_RepetitionType" SG_ 2499798055 Hrtbt 3;
BA_ "CI_RepetitionComplemented" SG_ 2499798055 Hrtbt 2;
BA_ "CI_FullName" SG_ 2499798055 Hrtbt "Heartbeat";
BA_ "CI_ParId" SG_ 2499798055 Hrtbt "ESMD_20033";
BA_ "CI_SLOT_Name" SG_ 2499798055 Hrtbt "SAEct03";
BA_ "GenSigStartValue" SG_ 2499798055 Hrtbt 251;
BA_ "SPN" SG_ 2499798055 Hrtbt 518020;
BA_ "CI_FullName" SG_ 2499798055 WakeUpInDozeMode "Wake Up In Doze Mode";
BA_ "CI_ParId" SG_ 2499798055 WakeUpInDozeMode "ESMD_20038";
BA_ "CI_SLOT_Name" SG_ 2499798055 WakeUpInDozeMode "SAEbs02";
BA_ "GenSigStartValue" SG_ 2499798055 WakeUpInDozeMode 3;
BA_ "SPN" SG_ 2499798055 WakeUpInDozeMode 517674;
BA_ "CI_FullName" SG_ 2499798055 WakeUpFunct "Wake Up Function";
BA_ "CI_ParId" SG_ 2499798055 WakeUpFunct "ESMD_20040";
BA_ "CI_SLOT_Name" SG_ 2499798055 WakeUpFunct "SAEbs04";
BA_ "GenSigStartValue" SG_ 2499798055 WakeUpFunct 15;
BA_ "SPN" SG_ 2499798055 WakeUpFunct 518024;
BA_ "CI_FullName" SG_ 2499798055 VehMov "Vehicle moving";
BA_ "CI_ParId" SG_ 2499798055 VehMov "ESMD_20043";
BA_ "CI_SLOT_Name" SG_ 2499798055 VehMov "SAEbs02";
BA_ "GenSigStartValue" SG_ 2499798055 VehMov 3;
BA_ "SPN" SG_ 2499798055 VehMov 517669;
BA_ "CI_FullName" SG_ 2499798055 KeySwNotOFF "Key Switch NOT OFF";
BA_ "CI_ParId" SG_ 2499798055 KeySwNotOFF "ESMD_08769";
BA_ "CI_SLOT_Name" SG_ 2499798055 KeySwNotOFF "SAEbs02";
BA_ "GenSigStartValue" SG_ 2499798055 KeySwNotOFF 3;
BA_ "SPN" SG_ 2499798055 KeySwNotOFF 1865;
BA_ "CI_FullName" SG_ 2499798055 IgnON "Ignition On";
BA_ "CI_ParId" SG_ 2499798055 IgnON "ESMD_20039";
BA_ "CI_SLOT_Name" SG_ 2499798055 IgnON "SAEbs02";
BA_ "GenSigStartValue" SG_ 2499798055 IgnON 3;
BA_ "SPN" SG_ 2499798055 IgnON 518022;
BA_ "GenSigAutoGenSnd" SG_ 2499798055 EngStartSts 0;
BA_ "GenSigAutoGenDsp" SG_ 2499798055 EngStartSts 0;
BA_ "CI_RepetitionComplemented" SG_ 2499798055 EngStartSts 2;
BA_ "CI_FullName" SG_ 2499798055 EngStartSts "Engine Starter Status";
BA_ "CI_ParId" SG_ 2499798055 EngStartSts "ESMD_20041";
BA_ "CI_SLOT_Name" SG_ 2499798055 EngStartSts "SAEbs02";
BA_ "GenSigStartValue" SG_ 2499798055 EngStartSts 3;
BA_ "SPN" SG_ 2499798055 EngStartSts 518021;
BA_ "GenSigAutoGenSnd" SG_ 2499798055 CByteNetManage 0;
BA_ "GenSigAutoGenDsp" SG_ 2499798055 CByteNetManage 0;
BA_ "CI_RepetitionComplemented" SG_ 2499798055 CByteNetManage 2;
BA_ "CI_FullName" SG_ 2499798055 CByteNetManage "Control Byte Network Management";
BA_ "CI_ParId" SG_ 2499798055 CByteNetManage "ESMD_20028";
BA_ "CI_SLOT_Name" SG_ 2499798055 CByteNetManage "SAEbs02";
BA_ "GenSigStartValue" SG_ 2499798055 CByteNetManage 3;
BA_ "SPN" SG_ 2499798055 CByteNetManage 517676;
BA_ "GenSigAutoGenSnd" SG_ 2499798055 EngRun 0;
BA_ "GenSigAutoGenDsp" SG_ 2499798055 EngRun 0;
BA_ "CI_RepetitionComplemented" SG_ 2499798055 EngRun 2;
BA_ "CI_FullName" SG_ 2499798055 EngRun "Engine Running";
BA_ "CI_ParId" SG_ 2499798055 EngRun "ESMD_20042";
BA_ "CI_SLOT_Name" SG_ 2499798055 EngRun "SAEbs02";
BA_ "GenSigStartValue" SG_ 2499798055 EngRun 3;
BA_ "SPN" SG_ 2499798055 EngRun 517670;
BA_ "CI_FullName" SG_ 2499798055 EmergEngOff_ReqSts "Emergency engine OFF request status";
BA_ "CI_ParId" SG_ 2499798055 EmergEngOff_ReqSts "ESMD_23514";
BA_ "CI_SLOT_Name" SG_ 2499798055 EmergEngOff_ReqSts "SAEbs01";
BA_ "SPN" SG_ 2499798055 EmergEngOff_ReqSts 520095;
BA_ "CI_FullName" SG_ 2499798055 MasterDisconnSwSts "Master Disconnect switch status";
BA_ "CI_ParId" SG_ 2499798055 MasterDisconnSwSts "ESMD_23513";
BA_ "CI_SLOT_Name" SG_ 2499798055 MasterDisconnSwSts "SAEbs01";
BA_ "SPN" SG_ 2499798055 MasterDisconnSwSts 520094;
BA_ "CI_RepetitionNum" SG_ 2566887975 EngShaftFanTorq 1;
BA_ "CI_RepetitionType" SG_ 2566887975 EngShaftFanTorq 3;
BA_ "CI_FullName" SG_ 2566887975 EngShaftFanTorq "Engine Shaft Fan Torque";
BA_ "CI_ParId" SG_ 2566887975 EngShaftFanTorq "ESMD_23601";
BA_ "CI_SLOT_Name" SG_ 2566887975 EngShaftFanTorq "SAEtq02";
BA_ "SPN" SG_ 2566887975 EngShaftFanTorq 518960;
BA_ "CI_RepetitionNum" SG_ 2566887975 EngHiLimThrsMinContEngRPM_2 1;
BA_ "CI_RepetitionType" SG_ 2566887975 EngHiLimThrsMinContEngRPM_2 3;
BA_ "CI_FullName" SG_ 2566887975 EngHiLimThrsMinContEngRPM_2 "Engine High Limit Threshold for Minimum Continuous Engine RPM";
BA_ "CI_ParId" SG_ 2566887975 EngHiLimThrsMinContEngRPM_2 "ESMD_23610";
BA_ "CI_SLOT_Name" SG_ 2566887975 EngHiLimThrsMinContEngRPM_2 "SAEvr01";
BA_ "SPN" SG_ 2566887975 EngHiLimThrsMinContEngRPM_2 518634;
BA_ "CI_RepetitionNum" SG_ 2566887975 EngMaxContRPM_2 1;
BA_ "CI_RepetitionType" SG_ 2566887975 EngMaxContRPM_2 3;
BA_ "CI_FullName" SG_ 2566887975 EngMaxContRPM_2 "Engine Maximum Continuous RPM 2";
BA_ "CI_ParId" SG_ 2566887975 EngMaxContRPM_2 "ESMD_23611";
BA_ "CI_SLOT_Name" SG_ 2566887975 EngMaxContRPM_2 "SAEvr01";
BA_ "SPN" SG_ 2566887975 EngMaxContRPM_2 518635;
BA_ "CI_RepetitionNum" SG_ 2566887975 EngMinContRPM_2 1;
BA_ "CI_RepetitionType" SG_ 2566887975 EngMinContRPM_2 3;
BA_ "CI_FullName" SG_ 2566887975 EngMinContRPM_2 "Engine Minimum Continuous RPM 2";
BA_ "CI_ParId" SG_ 2566887975 EngMinContRPM_2 "ESMD_23612";
BA_ "CI_SLOT_Name" SG_ 2566887975 EngMinContRPM_2 "SAEvr01";
BA_ "SPN" SG_ 2566887975 EngMinContRPM_2 518636;
BA_ "SPN_Definition" SG_ 2499777319 KickdnReq "N/A";
BA_ "CI_FullName" SG_ 2499777319 KickdnReq "Kickdown Request";
BA_ "CI_ParId" SG_ 2499777319 KickdnReq "ESMD_20077";
BA_ "CI_SLOT_Name" SG_ 2499777319 KickdnReq "SAEbs02";
BA_ "SPN" SG_ 2499777319 KickdnReq 517654;
BA_ "SigType" SG_ 2499777319 KickdnReq 1.7E-308;
BA_ "SPN_Definition" SG_ 2499777319 EngDroopMaxReq "N/A";
BA_ "CI_FullName" SG_ 2499777319 EngDroopMaxReq "Engine Droop Maximum Request";
BA_ "CI_ParId" SG_ 2499777319 EngDroopMaxReq "ESMD_23633";
BA_ "CI_SLOT_Name" SG_ 2499777319 EngDroopMaxReq "SAEct10";
BA_ "SPN" SG_ 2499777319 EngDroopMaxReq 518727;
BA_ "SigType" SG_ 2499777319 EngDroopMaxReq 1.7E-308;
BA_ "CI_RepetitionNum" SG_ 2499777319 SmoothShftEna 1;
BA_ "CI_RepetitionType" SG_ 2499777319 SmoothShftEna 3;
BA_ "CI_FullName" SG_ 2499777319 SmoothShftEna "Smooth Shift Enabled";
BA_ "CI_ParId" SG_ 2499777319 SmoothShftEna "ESMD_23632";
BA_ "CI_SLOT_Name" SG_ 2499777319 SmoothShftEna "SAEbs02";
BA_ "SPN" SG_ 2499777319 SmoothShftEna 518730;
BA_ "CI_RepetitionNum" SG_ 2499777319 AntiJckKnifeCmd 1;
BA_ "CI_RepetitionType" SG_ 2499777319 AntiJckKnifeCmd 3;
BA_ "CI_FullName" SG_ 2499777319 AntiJckKnifeCmd "Anti Jack Knife Command";
BA_ "CI_ParId" SG_ 2499777319 AntiJckKnifeCmd "ESMD_23631";
BA_ "CI_SLOT_Name" SG_ 2499777319 AntiJckKnifeCmd "SAEbs02";
BA_ "SPN" SG_ 2499777319 AntiJckKnifeCmd 518729;
BA_ "CI_FullName" SG_ 2499777319 B2C_Ena "B2C Enable";
BA_ "CI_ParId" SG_ 2499777319 B2C_Ena "ESMD_23637";
BA_ "CI_SLOT_Name" SG_ 2499777319 B2C_Ena "SAEbs02";
BA_ "SPN" SG_ 2499777319 B2C_Ena 518317;
BA_ "CI_RepetitionNum" SG_ 2499777319 RightBrakeSts 1;
BA_ "CI_RepetitionType" SG_ 2499777319 RightBrakeSts 3;
BA_ "CI_FullName" SG_ 2499777319 RightBrakeSts "Right Brake Status";
BA_ "CI_ParId" SG_ 2499777319 RightBrakeSts "ESMD_20086";
BA_ "CI_SLOT_Name" SG_ 2499777319 RightBrakeSts "SAEbs02";
BA_ "SPN" SG_ 2499777319 RightBrakeSts 518703;
BA_ "CI_RepetitionNum" SG_ 2499777319 LeftBrakeSts 1;
BA_ "CI_RepetitionType" SG_ 2499777319 LeftBrakeSts 3;
BA_ "CI_FullName" SG_ 2499777319 LeftBrakeSts "Left Brake Status";
BA_ "CI_ParId" SG_ 2499777319 LeftBrakeSts "ESMD_20087";
BA_ "CI_SLOT_Name" SG_ 2499777319 LeftBrakeSts "SAEbs02";
BA_ "SPN" SG_ 2499777319 LeftBrakeSts 518704;
BA_ "CI_RepetitionNum" SG_ 2499777319 HandBrakeSw 1;
BA_ "CI_RepetitionType" SG_ 2499777319 HandBrakeSw 3;
BA_ "CI_FullName" SG_ 2499777319 HandBrakeSw "Hand Brake switch";
BA_ "CI_ParId" SG_ 2499777319 HandBrakeSw "ESMD_20856";
BA_ "CI_SLOT_Name" SG_ 2499777319 HandBrakeSw "SAEbs02";
BA_ "SPN" SG_ 2499777319 HandBrakeSw 518693;
BA_ "CI_RepetitionNum" SG_ 2499777319 TransmDsrdModeCmd 1;
BA_ "CI_RepetitionType" SG_ 2499777319 TransmDsrdModeCmd 3;
BA_ "CI_FullName" SG_ 2499777319 TransmDsrdModeCmd "Transmission Desired mode Command";
BA_ "CI_ParId" SG_ 2499777319 TransmDsrdModeCmd "ESMD_20090";
BA_ "CI_SLOT_Name" SG_ 2499777319 TransmDsrdModeCmd "SAEbs04";
BA_ "SPN" SG_ 2499777319 TransmDsrdModeCmd 518705;
BA_ "CI_RepetitionNum" SG_ 2499777319 Bst_pc 1;
BA_ "CI_RepetitionType" SG_ 2499777319 Bst_pc 3;
BA_ "CI_FullName" SG_ 2499777319 Bst_pc "Boost Percentage";
BA_ "CI_ParId" SG_ 2499777319 Bst_pc "ESMD_20088";
BA_ "CI_SLOT_Name" SG_ 2499777319 Bst_pc "SAEpc03";
BA_ "SPN" SG_ 2499777319 Bst_pc 518695;
BA_ "CI_RepetitionNum" SG_ 2499777319 DsrdWhRevolSpd 1;
BA_ "CI_RepetitionType" SG_ 2499777319 DsrdWhRevolSpd 3;
BA_ "CI_FullName" SG_ 2499777319 DsrdWhRevolSpd "Desired Wheel Revolution Speed";
BA_ "CI_ParId" SG_ 2499777319 DsrdWhRevolSpd "ESMD_20012";
BA_ "SPN" SG_ 2499777319 DsrdWhRevolSpd 517667;
BA_ "CI_RepetitionNum" SG_ 2499777319 CltchPedTorqLim 1;
BA_ "CI_RepetitionType" SG_ 2499777319 CltchPedTorqLim 3;
BA_ "CI_FullName" SG_ 2499777319 CltchPedTorqLim "Clutch Pedal Torque Limit";
BA_ "CI_ParId" SG_ 2499777319 CltchPedTorqLim "ESMD_20006";
BA_ "SPN" SG_ 2499777319 CltchPedTorqLim 517637;
BA_ "CI_RepetitionNum" SG_ 2499777319 SecBrakeSetp 1;
BA_ "CI_RepetitionType" SG_ 2499777319 SecBrakeSetp 3;
BA_ "CI_FullName" SG_ 2499777319 SecBrakeSetp "Secondary Brake Setpoint";
BA_ "CI_ParId" SG_ 2499777319 SecBrakeSetp "ESMD_20002";
BA_ "CI_SLOT_Name" SG_ 2499777319 SecBrakeSetp "SAEpc03";
BA_ "SPN" SG_ 2499777319 SecBrakeSetp 517653;
BA_ "CI_FullName" SG_ 2348941095 TransmAutoN_Req "Transmission Auto-Neutral (Manual Return) Request";
BA_ "CI_ParId" SG_ 2348941095 TransmAutoN_Req "ESMD_24009";
BA_ "CI_SLOT_Name" SG_ 2348941095 TransmAutoN_Req "SAEbs02";
BA_ "SPN" SG_ 2348941095 TransmAutoN_Req 7695;
BA_ "CI_FullName" SG_ 2348941095 TransmGearShftInhReq "Transmission Gear Shift Inhibit Request";
BA_ "CI_ParId" SG_ 2348941095 TransmGearShftInhReq "ESMD_03532";
BA_ "CI_SLOT_Name" SG_ 2348941095 TransmGearShftInhReq "SAEbs02";
BA_ "SPN" SG_ 2348941095 TransmGearShftInhReq 681;
BA_ "CI_FullName" SG_ 2348941095 TransmTorqConvLckupDisReq "Transmission Torque Converter Lockup Disable Request";
BA_ "CI_ParId" SG_ 2348941095 TransmTorqConvLckupDisReq "ESMD_03676";
BA_ "CI_SLOT_Name" SG_ 2348941095 TransmTorqConvLckupDisReq "SAEbs02";
BA_ "SPN" SG_ 2348941095 TransmTorqConvLckupDisReq 682;
BA_ "CI_RepetitionNum" SG_ 2348941095 DisengDrvlReq 1;
BA_ "CI_RepetitionType" SG_ 2348941095 DisengDrvlReq 3;
BA_ "CI_FullName" SG_ 2348941095 DisengDrvlReq "Disengage Driveline Request";
BA_ "CI_ParId" SG_ 2348941095 DisengDrvlReq "ESMD_01050";
BA_ "CI_SLOT_Name" SG_ 2348941095 DisengDrvlReq "SAEbs02";
BA_ "SPN" SG_ 2348941095 DisengDrvlReq 683;
BA_ "CI_FullName" SG_ 2348941095 TransmRevGearShftInhReq "Transmission Reverse Gear Shift Inhibit Request";
BA_ "CI_ParId" SG_ 2348941095 TransmRevGearShftInhReq "ESMD_03587";
BA_ "CI_SLOT_Name" SG_ 2348941095 TransmRevGearShftInhReq "SAEbs02";
BA_ "SPN" SG_ 2348941095 TransmRevGearShftInhReq 4242;
BA_ "CI_FullName" SG_ 2348941095 Req_pcCltchSlip "Requested Percent Clutch Slip";
BA_ "CI_ParId" SG_ 2348941095 Req_pcCltchSlip "ESMD_03010";
BA_ "CI_SLOT_Name" SG_ 2348941095 Req_pcCltchSlip "SAEpc03";
BA_ "SPN" SG_ 2348941095 Req_pcCltchSlip 684;
BA_ "CI_RepetitionNum" SG_ 2348941095 TransmReqGear 1;
BA_ "CI_RepetitionType" SG_ 2348941095 TransmReqGear 3;
BA_ "CI_FullName" SG_ 2348941095 TransmReqGear "Transmission Requested Gear";
BA_ "CI_ParId" SG_ 2348941095 TransmReqGear "ESMD_03582";
BA_ "CI_SLOT_Name" SG_ 2348941095 TransmReqGear "SAEgv01";
BA_ "SPN" SG_ 2348941095 TransmReqGear 525;
BA_ "CI_RepetitionNum" SG_ 2348941095 DisengDiffLckReqFAx_1 1;
BA_ "CI_RepetitionType" SG_ 2348941095 DisengDiffLckReqFAx_1 3;
BA_ "CI_FullName" SG_ 2348941095 DisengDiffLckReqFAx_1 "Disengage Differential Lock Request - Front Axle 1";
BA_ "CI_ParId" SG_ 2348941095 DisengDiffLckReqFAx_1 "ESMD_01046";
BA_ "CI_SLOT_Name" SG_ 2348941095 DisengDiffLckReqFAx_1 "SAEbs02";
BA_ "SPN" SG_ 2348941095 DisengDiffLckReqFAx_1 685;
BA_ "CI_FullName" SG_ 2348941095 DisengDiffLckReqFAx_2 "Disengage Differential Lock Request - Front Axle 2";
BA_ "CI_ParId" SG_ 2348941095 DisengDiffLckReqFAx_2 "ESMD_01047";
BA_ "CI_SLOT_Name" SG_ 2348941095 DisengDiffLckReqFAx_2 "SAEbs02";
BA_ "SPN" SG_ 2348941095 DisengDiffLckReqFAx_2 686;
BA_ "CI_RepetitionNum" SG_ 2348941095 DisengDiffLckReqRAx_1 1;
BA_ "CI_RepetitionType" SG_ 2348941095 DisengDiffLckReqRAx_1 3;
BA_ "CI_FullName" SG_ 2348941095 DisengDiffLckReqRAx_1 "Disengage Differential Lock Request - Rear Axle 1";
BA_ "CI_ParId" SG_ 2348941095 DisengDiffLckReqRAx_1 "ESMD_01048";
BA_ "CI_SLOT_Name" SG_ 2348941095 DisengDiffLckReqRAx_1 "SAEbs02";
BA_ "SPN" SG_ 2348941095 DisengDiffLckReqRAx_1 687;
BA_ "CI_FullName" SG_ 2348941095 DisengDiffLckReqRAx_2 "Disengage Differential Lock Request - Rear Axle 2";
BA_ "CI_ParId" SG_ 2348941095 DisengDiffLckReqRAx_2 "ESMD_01049";
BA_ "CI_SLOT_Name" SG_ 2348941095 DisengDiffLckReqRAx_2 "SAEbs02";
BA_ "SPN" SG_ 2348941095 DisengDiffLckReqRAx_2 688;
BA_ "CI_RepetitionNum" SG_ 2348941095 DisengDiffLckReqCent 1;
BA_ "CI_RepetitionType" SG_ 2348941095 DisengDiffLckReqCent 3;
BA_ "CI_FullName" SG_ 2348941095 DisengDiffLckReqCent "Disengage Differential Lock Request - Central";
BA_ "CI_ParId" SG_ 2348941095 DisengDiffLckReqCent "ESMD_01043";
BA_ "CI_SLOT_Name" SG_ 2348941095 DisengDiffLckReqCent "SAEbs02";
BA_ "SPN" SG_ 2348941095 DisengDiffLckReqCent 689;
BA_ "CI_FullName" SG_ 2348941095 DisengDiffLckReqCentFrnt "Disengage Differential Lock Request - Central Front";
BA_ "CI_ParId" SG_ 2348941095 DisengDiffLckReqCentFrnt "ESMD_01044";
BA_ "CI_SLOT_Name" SG_ 2348941095 DisengDiffLckReqCentFrnt "SAEbs02";
BA_ "SPN" SG_ 2348941095 DisengDiffLckReqCentFrnt 690;
BA_ "CI_FullName" SG_ 2348941095 DisengDiffLckReqCentRear "Disengage Differential Lock Request - Central Rear";
BA_ "CI_ParId" SG_ 2348941095 DisengDiffLckReqCentRear "ESMD_01045";
BA_ "CI_SLOT_Name" SG_ 2348941095 DisengDiffLckReqCentRear "SAEbs02";
BA_ "SPN" SG_ 2348941095 DisengDiffLckReqCentRear 691;
BA_ "CI_FullName" SG_ 2348941095 TransmLoadReducInhReq "Transmission Load Reduction Inhibit Request";
BA_ "CI_ParId" SG_ 2348941095 TransmLoadReducInhReq "ESMD_03539";
BA_ "CI_SLOT_Name" SG_ 2348941095 TransmLoadReducInhReq "SAEbs02";
BA_ "SPN" SG_ 2348941095 TransmLoadReducInhReq 5762;
BA_ "CI_FullName" SG_ 2348941095 TransmMode_1 "Transmission Mode 1";
BA_ "CI_ParId" SG_ 2348941095 TransmMode_1 "ESMD_03545";
BA_ "CI_SLOT_Name" SG_ 2348941095 TransmMode_1 "SAEbs02";
BA_ "SPN" SG_ 2348941095 TransmMode_1 1852;
BA_ "CI_FullName" SG_ 2348941095 TransmMode_2 "Transmission Mode 2";
BA_ "CI_ParId" SG_ 2348941095 TransmMode_2 "ESMD_03547";
BA_ "CI_SLOT_Name" SG_ 2348941095 TransmMode_2 "SAEbs02";
BA_ "SPN" SG_ 2348941095 TransmMode_2 1853;
BA_ "CI_FullName" SG_ 2348941095 TransmMode_3 "Transmission Mode 3";
BA_ "CI_ParId" SG_ 2348941095 TransmMode_3 "ESMD_03549";
BA_ "CI_SLOT_Name" SG_ 2348941095 TransmMode_3 "SAEbs02";
BA_ "SPN" SG_ 2348941095 TransmMode_3 1854;
BA_ "CI_FullName" SG_ 2348941095 TransmMode_4 "Transmission Mode 4";
BA_ "CI_ParId" SG_ 2348941095 TransmMode_4 "ESMD_03551";
BA_ "CI_SLOT_Name" SG_ 2348941095 TransmMode_4 "SAEbs02";
BA_ "SPN" SG_ 2348941095 TransmMode_4 1855;
BA_ "CI_FullName" SG_ 2348941095 TransmReqLaunchGear "Transmission Requested Launch Gear";
BA_ "CI_ParId" SG_ 2348941095 TransmReqLaunchGear "ESMD_03584";
BA_ "CI_SLOT_Name" SG_ 2348941095 TransmReqLaunchGear "SAEbs04";
BA_ "SPN" SG_ 2348941095 TransmReqLaunchGear 4255;
BA_ "CI_FullName" SG_ 2348941095 TransmShftSelDisplayModeSw "Transmission Shift Selector Display Mode Switch";
BA_ "CI_ParId" SG_ 2348941095 TransmShftSelDisplayModeSw "ESMD_03672";
BA_ "CI_SLOT_Name" SG_ 2348941095 TransmShftSelDisplayModeSw "SAEbs02";
BA_ "SPN" SG_ 2348941095 TransmShftSelDisplayModeSw 2985;
BA_ "CI_FullName" SG_ 2348941095 TransmMode_5 "Transmission Mode 5";
BA_ "CI_ParId" SG_ 2348941095 TransmMode_5 "ESMD_03553";
BA_ "CI_SLOT_Name" SG_ 2348941095 TransmMode_5 "SAEbs02";
BA_ "SPN" SG_ 2348941095 TransmMode_5 4246;
BA_ "CI_FullName" SG_ 2348941095 TransmMode_6 "Transmission Mode 6";
BA_ "CI_ParId" SG_ 2348941095 TransmMode_6 "ESMD_03555";
BA_ "CI_SLOT_Name" SG_ 2348941095 TransmMode_6 "SAEbs02";
BA_ "SPN" SG_ 2348941095 TransmMode_6 4247;
BA_ "CI_FullName" SG_ 2348941095 TransmMode_7 "Transmission Mode 7";
BA_ "CI_ParId" SG_ 2348941095 TransmMode_7 "ESMD_03557";
BA_ "CI_SLOT_Name" SG_ 2348941095 TransmMode_7 "SAEbs02";
BA_ "SPN" SG_ 2348941095 TransmMode_7 4248;
BA_ "CI_FullName" SG_ 2348941095 TransmMode_8 "Transmission Mode 8";
BA_ "CI_ParId" SG_ 2348941095 TransmMode_8 "ESMD_03559";
BA_ "CI_SLOT_Name" SG_ 2348941095 TransmMode_8 "SAEbs02";
BA_ "SPN" SG_ 2348941095 TransmMode_8 4249;
BA_ "CI_FullName" SG_ 2566852135 MsgChksum_3 "Message Checksum 3";
BA_ "CI_ParId" SG_ 2566852135 MsgChksum_3 "ESMD_16006";
BA_ "CI_SLOT_Name" SG_ 2566852135 MsgChksum_3 "SAEct03";
BA_ "SPN" SG_ 2566852135 MsgChksum_3 7042;
BA_ "GenSigAutoGenSnd" SG_ 2566852135 MsgCnt 0;
BA_ "GenSigAutoGenDsp" SG_ 2566852135 MsgCnt 0;
BA_ "CI_FullName" SG_ 2566852135 MsgCnt "Message Counter";
BA_ "CI_ParId" SG_ 2566852135 MsgCnt "ESMD_02699";
BA_ "CI_SLOT_Name" SG_ 2566852135 MsgCnt "SAEct08";
BA_ "SPN" SG_ 2566852135 MsgCnt 3689;
BA_ "CI_FullName" SG_ 2566852135 PneuSupplyPrs "Pneumatic Supply Pressure";
BA_ "CI_ParId" SG_ 2566852135 PneuSupplyPrs "ESMD_02884";
BA_ "CI_SLOT_Name" SG_ 2566852135 PneuSupplyPrs "SAEpr13";
BA_ "SPN" SG_ 2566852135 PneuSupplyPrs 46;
BA_ "CI_RepetitionNum" SG_ 2566852135 ServBrakeCirc_2AirPrs 1;
BA_ "CI_RepetitionType" SG_ 2566852135 ServBrakeCirc_2AirPrs 3;
BA_ "CI_FullName" SG_ 2566852135 ServBrakeCirc_2AirPrs "Service Brake Circuit 2 Air Pressure";
BA_ "CI_ParId" SG_ 2566852135 ServBrakeCirc_2AirPrs "ESMD_03119";
BA_ "CI_SLOT_Name" SG_ 2566852135 ServBrakeCirc_2AirPrs "SAEpr13";
BA_ "SPN" SG_ 2566852135 ServBrakeCirc_2AirPrs 1088;
BA_ "CI_RepetitionNum" SG_ 2566852135 ServBrakeCirc_1AirPrs 1;
BA_ "CI_RepetitionType" SG_ 2566852135 ServBrakeCirc_1AirPrs 3;
BA_ "CI_FullName" SG_ 2566852135 ServBrakeCirc_1AirPrs "Service Brake Circuit 1 Air Pressure";
BA_ "CI_ParId" SG_ 2566852135 ServBrakeCirc_1AirPrs "ESMD_03118";
BA_ "CI_SLOT_Name" SG_ 2566852135 ServBrakeCirc_1AirPrs "SAEpr13";
BA_ "SPN" SG_ 2566852135 ServBrakeCirc_1AirPrs 1087;
BA_ "CI_RepetitionNum" SG_ 2566852135 Park_aoTrailAirPrs 1;
BA_ "CI_RepetitionType" SG_ 2566852135 Park_aoTrailAirPrs 3;
BA_ "CI_FullName" SG_ 2566852135 Park_aoTrailAirPrs "Parking and/or Trailer Air Pressure";
BA_ "CI_ParId" SG_ 2566852135 Park_aoTrailAirPrs "ESMD_02840";
BA_ "CI_SLOT_Name" SG_ 2566852135 Park_aoTrailAirPrs "SAEpr13";
BA_ "SPN" SG_ 2566852135 Park_aoTrailAirPrs 1086;
BA_ "GenSigAutoGenSnd" SG_ 2566852135 TheoVehSpd 0;
BA_ "GenSigAutoGenDsp" SG_ 2566852135 TheoVehSpd 0;
BA_ "CI_RepetitionNum" SG_ 2566852135 TheoVehSpd 1;
BA_ "CI_RepetitionType" SG_ 2566852135 TheoVehSpd 3;
BA_ "CI_RepetitionComplemented" SG_ 2566852135 TheoVehSpd 2;
BA_ "CI_FullName" SG_ 2566852135 TheoVehSpd "Theoretical Vehicle Speed";
BA_ "CI_ParId" SG_ 2566852135 TheoVehSpd "NWD-2926";
BA_ "CI_SLOT_Name" SG_ 2566852135 TheoVehSpd "SAEvl02";
BA_ "SPN" SG_ 2566852135 TheoVehSpd 84;
BA_ "CI_FullName" SG_ 2632711975 PktDataTPDT "Packetized Data (TP.DT)";
BA_ "CI_ParId" SG_ 2632711975 PktDataTPDT "ESMD_16027";
BA_ "SPN" SG_ 2632711975 PktDataTPDT 2573;
BA_ "CI_FullName" SG_ 2632711975 SN_TPDT "Sequence Number (TP.DT)";
BA_ "CI_ParId" SG_ 2632711975 SN_TPDT "ESMD_03114";
BA_ "SPN" SG_ 2632711975 SN_TPDT 2572;
BA_ "GenSigAutoGenSnd" SG_ 2364539943 ActlEng_pcTorqFrac 0;
BA_ "GenSigAutoGenDsp" SG_ 2364539943 ActlEng_pcTorqFrac 0;
BA_ "CI_RepetitionComplemented" SG_ 2364539943 ActlEng_pcTorqFrac 2;
BA_ "CI_FullName" SG_ 2364539943 ActlEng_pcTorqFrac "Actual Engine - Percent Torque (Fractional)";
BA_ "CI_ParId" SG_ 2364539943 ActlEng_pcTorqFrac "ESMD_00030";
BA_ "CI_SLOT_Name" SG_ 2364539943 ActlEng_pcTorqFrac "SAEpc10";
BA_ "SPN" SG_ 2364539943 ActlEng_pcTorqFrac 4154;
BA_ "GenSigAutoGenSnd" SG_ 2364539943 EngTorqMode 0;
BA_ "GenSigAutoGenDsp" SG_ 2364539943 EngTorqMode 0;
BA_ "CI_RepetitionComplemented" SG_ 2364539943 EngTorqMode 2;
BA_ "CI_FullName" SG_ 2364539943 EngTorqMode "Engine Torque Mode";
BA_ "CI_ParId" SG_ 2364539943 EngTorqMode "ESMD_01836";
BA_ "CI_SLOT_Name" SG_ 2364539943 EngTorqMode "SAEbs04";
BA_ "SPN" SG_ 2364539943 EngTorqMode 899;
BA_ "GenSigAutoGenSnd" SG_ 2364539943 DrivRqstEng_pcTorq 0;
BA_ "GenSigAutoGenDsp" SG_ 2364539943 DrivRqstEng_pcTorq 0;
BA_ "CI_RepetitionComplemented" SG_ 2364539943 DrivRqstEng_pcTorq 2;
BA_ "CI_FullName" SG_ 2364539943 DrivRqstEng_pcTorq "Drivers Demand Engine - Percent Torque";
BA_ "CI_ParId" SG_ 2364539943 DrivRqstEng_pcTorq "ESMD_01076";
BA_ "CI_SLOT_Name" SG_ 2364539943 DrivRqstEng_pcTorq "SAEpc05";
BA_ "SPN" SG_ 2364539943 DrivRqstEng_pcTorq 512;
BA_ "GenSigAutoGenSnd" SG_ 2364539943 ActlEng_pcTorq 0;
BA_ "GenSigAutoGenDsp" SG_ 2364539943 ActlEng_pcTorq 0;
BA_ "CI_RepetitionComplemented" SG_ 2364539943 ActlEng_pcTorq 2;
BA_ "CI_FullName" SG_ 2364539943 ActlEng_pcTorq "Actual Engine - Percent Torque";
BA_ "CI_ParId" SG_ 2364539943 ActlEng_pcTorq "ESMD_00034";
BA_ "CI_SLOT_Name" SG_ 2364539943 ActlEng_pcTorq "SAEpc05";
BA_ "SPN" SG_ 2364539943 ActlEng_pcTorq 513;
BA_ "SigType" SG_ 2364539943 ActlEng_pcTorq 1;
BA_ "GenSigAutoGenSnd" SG_ 2364539943 EngSpd 0;
BA_ "GenSigAutoGenDsp" SG_ 2364539943 EngSpd 0;
BA_ "CI_RepetitionComplemented" SG_ 2364539943 EngSpd 2;
BA_ "CI_FullName" SG_ 2364539943 EngSpd "Engine Speed";
BA_ "CI_ParId" SG_ 2364539943 EngSpd "ESMD_01792";
BA_ "CI_SLOT_Name" SG_ 2364539943 EngSpd "SAEvr01";
BA_ "SPN" SG_ 2364539943 EngSpd 190;
BA_ "GenSigAutoGenSnd" SG_ 2364539943 SA_CntrlDevEngCntrl 0;
BA_ "GenSigAutoGenDsp" SG_ 2364539943 SA_CntrlDevEngCntrl 0;
BA_ "CI_RepetitionComplemented" SG_ 2364539943 SA_CntrlDevEngCntrl 2;
BA_ "CI_FullName" SG_ 2364539943 SA_CntrlDevEngCntrl "Source Address of Controlling Device for Engine Control";
BA_ "CI_ParId" SG_ 2364539943 SA_CntrlDevEngCntrl "ESMD_03261";
BA_ "CI_SLOT_Name" SG_ 2364539943 SA_CntrlDevEngCntrl "SAEsa01";
BA_ "SPN" SG_ 2364539943 SA_CntrlDevEngCntrl 1483;
BA_ "GenSigAutoGenSnd" SG_ 2364539943 EngStartMode 0;
BA_ "GenSigAutoGenDsp" SG_ 2364539943 EngStartMode 0;
BA_ "CI_RepetitionComplemented" SG_ 2364539943 EngStartMode 2;
BA_ "CI_FullName" SG_ 2364539943 EngStartMode "Engine Starter Mode";
BA_ "CI_ParId" SG_ 2364539943 EngStartMode "ESMD_27910";
BA_ "CI_SLOT_Name" SG_ 2364539943 EngStartMode "SAEbs04";
BA_ "SPN" SG_ 2364539943 EngStartMode 1675;
BA_ "GenSigAutoGenSnd" SG_ 2364539943 EngRqst_pcTorq 0;
BA_ "GenSigAutoGenDsp" SG_ 2364539943 EngRqst_pcTorq 0;
BA_ "CI_RepetitionComplemented" SG_ 2364539943 EngRqst_pcTorq 2;
BA_ "CI_FullName" SG_ 2364539943 EngRqst_pcTorq "Engine Demand – Percent Torque";
BA_ "CI_ParId" SG_ 2364539943 EngRqst_pcTorq "ESMD_01409";
BA_ "CI_SLOT_Name" SG_ 2364539943 EngRqst_pcTorq "SAEpc05";
BA_ "SPN" SG_ 2364539943 EngRqst_pcTorq 2432;
BA_ "GenSigAutoGenSnd" SG_ 2632777511 CByteTPCM 0;
BA_ "GenSigAutoGenDsp" SG_ 2632777511 CByteTPCM 0;
BA_ "CI_RepetitionComplemented" SG_ 2632777511 CByteTPCM 2;
BA_ "CI_FullName" SG_ 2632777511 CByteTPCM "Control Byte (TP.CM)";
BA_ "CI_ParId" SG_ 2632777511 CByteTPCM "ESMD_00941";
BA_ "SPN" SG_ 2632777511 CByteTPCM 2556;
BA_ "GenSigAutoGenSnd" SG_ 2632777511 TotMsgSizeTPCM_RTS 0;
BA_ "GenSigAutoGenDsp" SG_ 2632777511 TotMsgSizeTPCM_RTS 0;
BA_ "CI_RepetitionComplemented" SG_ 2632777511 TotMsgSizeTPCM_RTS 2;
BA_ "CI_FullName" SG_ 2632777511 TotMsgSizeTPCM_RTS "Total Message Size (TP.CM_RTS)";
BA_ "CI_ParId" SG_ 2632777511 TotMsgSizeTPCM_RTS "ESMD_03431";
BA_ "SPN" SG_ 2632777511 TotMsgSizeTPCM_RTS 2557;
BA_ "GenSigAutoGenSnd" SG_ 2632777511 TotNumPktTPCM_RTS 0;
BA_ "GenSigAutoGenDsp" SG_ 2632777511 TotNumPktTPCM_RTS 0;
BA_ "CI_RepetitionComplemented" SG_ 2632777511 TotNumPktTPCM_RTS 2;
BA_ "CI_FullName" SG_ 2632777511 TotNumPktTPCM_RTS "Total Number of Packets (TP.CM_RTS)";
BA_ "CI_ParId" SG_ 2632777511 TotNumPktTPCM_RTS "ESMD_03434";
BA_ "SPN" SG_ 2632777511 TotNumPktTPCM_RTS 2558;
BA_ "GenSigAutoGenSnd" SG_ 2632777511 MaxNumPktTPCM_RTS 0;
BA_ "GenSigAutoGenDsp" SG_ 2632777511 MaxNumPktTPCM_RTS 0;
BA_ "CI_RepetitionComplemented" SG_ 2632777511 MaxNumPktTPCM_RTS 2;
BA_ "CI_FullName" SG_ 2632777511 MaxNumPktTPCM_RTS "Maximum Number of Packets (TP.CM_RTS)";
BA_ "CI_ParId" SG_ 2632777511 MaxNumPktTPCM_RTS "ESMD_02684";
BA_ "SPN" SG_ 2632777511 MaxNumPktTPCM_RTS 2559;
BA_ "GenSigAutoGenSnd" SG_ 2632777511 PGN_PktMsgTPCM_RTS 0;
BA_ "GenSigAutoGenDsp" SG_ 2632777511 PGN_PktMsgTPCM_RTS 0;
BA_ "CI_RepetitionComplemented" SG_ 2632777511 PGN_PktMsgTPCM_RTS 2;
BA_ "CI_FullName" SG_ 2632777511 PGN_PktMsgTPCM_RTS "Parameter Group Number of the packeted message (TP.CM_RTS)";
BA_ "CI_ParId" SG_ 2632777511 PGN_PktMsgTPCM_RTS "ESMD_02869";
BA_ "SPN" SG_ 2632777511 PGN_PktMsgTPCM_RTS 2560;
BA_ "GenSigAutoGenSnd" SG_ 2632777511 NumPktSentTPCM_CTS 0;
BA_ "GenSigAutoGenDsp" SG_ 2632777511 NumPktSentTPCM_CTS 0;
BA_ "CI_RepetitionComplemented" SG_ 2632777511 NumPktSentTPCM_CTS 2;
BA_ "CI_FullName" SG_ 2632777511 NumPktSentTPCM_CTS "Number of Packets that can be sent (TP.CM_CTS)";
BA_ "CI_ParId" SG_ 2632777511 NumPktSentTPCM_CTS "ESMD_02790";
BA_ "SPN" SG_ 2632777511 NumPktSentTPCM_CTS 2561;
BA_ "GenSigAutoGenSnd" SG_ 2632777511 NxtPktNumSentTPCM_CTS 0;
BA_ "GenSigAutoGenDsp" SG_ 2632777511 NxtPktNumSentTPCM_CTS 0;
BA_ "CI_RepetitionComplemented" SG_ 2632777511 NxtPktNumSentTPCM_CTS 2;
BA_ "CI_FullName" SG_ 2632777511 NxtPktNumSentTPCM_CTS "Next Packet Number to be sent (TP.CM_CTS)";
BA_ "CI_ParId" SG_ 2632777511 NxtPktNumSentTPCM_CTS "ESMD_02740";
BA_ "SPN" SG_ 2632777511 NxtPktNumSentTPCM_CTS 2562;
BA_ "GenSigAutoGenSnd" SG_ 2632777511 ConnAbrtReason 0;
BA_ "GenSigAutoGenDsp" SG_ 2632777511 ConnAbrtReason 0;
BA_ "CI_RepetitionComplemented" SG_ 2632777511 ConnAbrtReason 2;
BA_ "CI_FullName" SG_ 2632777511 ConnAbrtReason "Connection Abort Reason";
BA_ "CI_ParId" SG_ 2632777511 ConnAbrtReason "ESMD_00939";
BA_ "SPN" SG_ 2632777511 ConnAbrtReason 2570;
BA_ "GenSigAutoGenSnd" SG_ 2632777511 TotNumPktBAM 0;
BA_ "GenSigAutoGenDsp" SG_ 2632777511 TotNumPktBAM 0;
BA_ "CI_RepetitionComplemented" SG_ 2632777511 TotNumPktBAM 2;
BA_ "CI_FullName" SG_ 2632777511 TotNumPktBAM "_";
BA_ "CI_ParId" SG_ 2632777511 TotNumPktBAM "ESMD_03435";
BA_ "SPN" SG_ 2632777511 TotNumPktBAM 2568;
BA_ "GenSigAutoGenSnd" SG_ 2632777511 TotMsgSizeBAM 0;
BA_ "GenSigAutoGenDsp" SG_ 2632777511 TotMsgSizeBAM 0;
BA_ "CI_RepetitionComplemented" SG_ 2632777511 TotMsgSizeBAM 2;
BA_ "CI_FullName" SG_ 2632777511 TotMsgSizeBAM "_";
BA_ "CI_ParId" SG_ 2632777511 TotMsgSizeBAM "ESMD_03432";
BA_ "SPN" SG_ 2632777511 TotMsgSizeBAM 2567;
BA_ "GenSigAutoGenSnd" SG_ 2632777511 TotMsgSizeEoMA 0;
BA_ "GenSigAutoGenDsp" SG_ 2632777511 TotMsgSizeEoMA 0;
BA_ "CI_RepetitionComplemented" SG_ 2632777511 TotMsgSizeEoMA 2;
BA_ "CI_FullName" SG_ 2632777511 TotMsgSizeEoMA "_";
BA_ "CI_ParId" SG_ 2632777511 TotMsgSizeEoMA "ESMD_03433";
BA_ "SPN" SG_ 2632777511 TotMsgSizeEoMA 2564;
BA_ "GenSigAutoGenSnd" SG_ 2632777511 TotNumPktEoMA 0;
BA_ "GenSigAutoGenDsp" SG_ 2632777511 TotNumPktEoMA 0;
BA_ "CI_RepetitionComplemented" SG_ 2632777511 TotNumPktEoMA 2;
BA_ "CI_FullName" SG_ 2632777511 TotNumPktEoMA "_";
BA_ "CI_ParId" SG_ 2632777511 TotNumPktEoMA "ESMD_03436";
BA_ "SPN" SG_ 2632777511 TotNumPktEoMA 2565;
BA_ "GenSigAutoGenSnd" SG_ 2632777511 PGN_PktMsgTPCM_ConnAbort 0;
BA_ "GenSigAutoGenDsp" SG_ 2632777511 PGN_PktMsgTPCM_ConnAbort 0;
BA_ "CI_RepetitionComplemented" SG_ 2632777511 PGN_PktMsgTPCM_ConnAbort 2;
BA_ "CI_FullName" SG_ 2632777511 PGN_PktMsgTPCM_ConnAbort "Parameter Group Number of the packeted message (TP.CM_Conn_Abort)";
BA_ "CI_ParId" SG_ 2632777511 PGN_PktMsgTPCM_ConnAbort "ESMD_03862";
BA_ "SPN" SG_ 2632777511 PGN_PktMsgTPCM_ConnAbort 2571;
BA_ "GenSigAutoGenSnd" SG_ 2632777511 PGN_PktMsgTPCM_BAM 0;
BA_ "GenSigAutoGenDsp" SG_ 2632777511 PGN_PktMsgTPCM_BAM 0;
BA_ "CI_RepetitionComplemented" SG_ 2632777511 PGN_PktMsgTPCM_BAM 2;
BA_ "CI_FullName" SG_ 2632777511 PGN_PktMsgTPCM_BAM "Parameter Group Number of the packeted message (TP.CM_BAM)";
BA_ "CI_ParId" SG_ 2632777511 PGN_PktMsgTPCM_BAM "ESMD_03861";
BA_ "SPN" SG_ 2632777511 PGN_PktMsgTPCM_BAM 2569;
BA_ "CI_FullName" SG_ 2632777511 PGN_PktMsgTPCM_RTS2 "Parameter Group Number of the packeted message (TP.CM_RTS) 2";
BA_ "CI_ParId" SG_ 2632777511 PGN_PktMsgTPCM_RTS2 "ESMD_03860";
BA_ "SPN" SG_ 2632777511 PGN_PktMsgTPCM_RTS2 2566;
BA_ "GenSigAutoGenSnd" SG_ 2632777511 PGN_PktMsgTPCM_CTS 0;
BA_ "GenSigAutoGenDsp" SG_ 2632777511 PGN_PktMsgTPCM_CTS 0;
BA_ "CI_RepetitionComplemented" SG_ 2632777511 PGN_PktMsgTPCM_CTS 2;
BA_ "CI_FullName" SG_ 2632777511 PGN_PktMsgTPCM_CTS "Parameter Group Number of the packeted message (TP.CM_CTS)";
BA_ "CI_ParId" SG_ 2632777511 PGN_PktMsgTPCM_CTS "ESMD_03859";
BA_ "SPN" SG_ 2632777511 PGN_PktMsgTPCM_CTS 2563;
VAL_ 2365473539 RPTO_EconMode 3 "NotAvailabel" 2 "ErrorIndication" 1 "PTOEconomyModeIsEngaged" 0 "PTOEconomyModeIsDisengaged" ;
VAL_ 2365473539 RPTO_Engag 3 "NotAvailable" 2 "ErrorIndication" 1 "PTOEngaged" 0 "PTODisengaged" ;
VAL_ 2365473539 RPTO_Mode 3 "NotAvailable" 2 "ErrorIndication" 1 "PTOModeIs1000" 0 "PTOModeIs540" ;
VAL_ 2365473539 RPTO_ReasonCod 0 "No reason/all clear" 1 "Operator presence not detected" 2 "Implement released control of function" 3 "Operator override of function " 4 "Operator control not in valid position " 5 "Remote command timeout " 6 "Remote command out of range/invalid " 7 "Function not calibrated " 8 "Operator control fault " 9 "Function fault " 20 "Invalid PTO gear" 62 "Error " 63 "Not available (parameter not supported)" ;
VAL_ 2365473539 RPTO_ModeReqSts 0 "External Request accepted" 1 "Control Override" 2 "Error" 3 "Not available" ;
VAL_ 2365473539 RPTO_EconModeReqSts 0 "External Request accepted" 1 "Control Override" 2 "Error" 3 "Not available" ;
VAL_ 2365473539 RPTO_ShaftSpdLimSts 4 "Reserved" 5 "Reserver" 6 "Non-recoverable Fault" 7 "Not available" 0 "Not limited" 1 "Operator Limited" 2 "Limited High" 3 "Limited Low" ;
VAL_ 2365473539 RPTO_EngagReqSts 0 "External Request accepted" 1 "Control Override" 2 "Error" 3 "Not available" ;
VAL_ 2565482243 PGN_RQST_03_27 65395 "ECU_DatasetChksum" 65394 "ECU_Dataset" ;
VAL_ 2566888451 SevTransmOverSpdWarn 1 "Warning" 0 "Not Warning" 3 "NA" 2 "Error" ;
VAL_ 2566888451 InchngFenderFdbk 6 "Error" 4 "N/A" 2 "Not OK -  HIGH SAHR ENERGY LOSS" 1 "Not OK - TRANSM OIL TEMP TOO LOW" 0 "Fender Inching Ok" ;
VAL_ 2566888451 FrntDifflckRecovSts 0 "Not in Fault" 1 "In Fault" 2 "Error" 3 "NA" ;
VAL_ 2566888451 MFD_RecovSts 0 "Not in Fault" 1 "In Fault" 2 "Error" 3 "NA" ;
VAL_ 2566888451 RearDifflckRecovSts 0 "Not in Fault" 1 "In Fault" 2 "Error" 3 "NA" ;
VAL_ 2566888451 AxLubePrsLoWarn 2 "Error" 1 "Warning" 0 "Not Warning" 3 "N/A" ;
VAL_ 2566888451 RPTO_RecovReact 1 "Present" 0 "Not Present" ;
VAL_ 2566888451 ParkChambrPrsLeakWarn 3 "NA" 0 "not warning" 1 "warning" 2 "Error" ;
VAL_ 2566888451 TransmOverSpd 1 "warning" 0 "not warning" 3 "NA" 2 "Error" ;
VAL_ 2566888451 SecWhRevolSpd 64256 "Overspeed" 65534 "Error" 65535 "N/A" ;
VAL_ 2566888451 DrvlOilTempWarn_2 1 "warning" 0 "not warning" 3 "NA" 2 "critical" ;
VAL_ 2566894083 CalibrSts 15 "NA" 14 "Error" 6 "Aborted" 5 "Calibrated" 4 "Calibrating" 3 "Waiting for start" 2 "Pause" 1 "Calibration Check" 0 "Idle" ;
VAL_ 2566894083 RPTO_CalibrProgr 15 "NA" 14 "Error" 6 "Aborted" 5 "Calibrated" 4 "Calibrating" 3 "Waiting for start" 2 "Pause" 1 "RPTO Calibration Check" 0 "Idle" ;
VAL_ 2566801923 TransmReqGearFdbk 125 "Neutral" 223 "Reverse Selector pos" 224 "PosUnknwnAnd/orNoBtnPres-NOTused" 225 "PressMomBtnToReselCurPos-NOTused" 226 "Betw. R and P pos - NOTused" 227 "Betw. N and R pos - NOTused" 228 "Betw.Drivand Neutral pos-NOTused" 229 "BetwD-andDrivshiftSelPos-NOTused" 230 "Betw. D-2 and D-1 pos-NOTused" 231 "Betw. D-3 and D-2 pos-NOTused" 232 "Betw. D-4 and D-3 pos-NOTused" 233 "Betw. D-5 and D-4 pos-NOTused" 234 "Betw. D-6 and D-5 pos-NOTused" 235 "Betw. D-7 and D-6 pos-NOTused" 236 "Betw. two fw pos.-NOTused" 237 "Betw. two reverse pos-NOTused" 238 "Betw. two pos-NOTused" 239 "D-7 7th fw pos from Driv-NOTused" 240 "D-6 6th fw pos from Driv-NOTused" 241 "D-5 5th fw pos from Driv-NOTused" 242 "D-4 4th fw pos from Driv-NOTused" 243 "D-3 3rd fw pos from Driv-NOTused" 244 "D-2 2nd fw pos from Driv-NOTused" 245 "D-1 1st fw pos from Driv-NOTused" 246 "Downshift 2 gear - NOT used" 247 "Downshift 1 gear- NOT used" 248 "Upshift 2 gear- NOT used" 249 "Upshift 1 gear- NOT used" 250 "Fw Low pos" 251 "Park pos" 252 "Fw Drive pos" 253 "Hold current gear" 255 "No action" ;
VAL_ 2566801923 TransmAutoN_Sts 4 "request received-Shift inhibited" 3 "request received-Shift achieved" 2 "request received-Shift pending" 1 "No Req-ConditionWillNotBeHonored" 0 "No Req-ConditionsWillBeHonored" 7 "NA" 6 "Error" 5 "Reserved" ;
VAL_ 2566801923 TransmServInd 0 "Transmission Service Indicator is off" 1 "Transmission Service Indicator is on continuously" 2 "Transmission Service Indicator is flashing" 3 "Not available" ;
VAL_ 2566801923 TransmReqRngDisplayBlnkSts 0 "Inactive Transmission Requested Range display should not be blanked" 1 "Active Transmission Requested Range display should be blanked" 2 "Reserved" 3 "Take no action" ;
VAL_ 2566801923 TransmReqRngDisplayFlashSts 0 "Inactive Transmission Requested Range display should not be flashing" 1 "Active Transmission Requested Range display should be flashing" 2 "Reserved" 3 "Take no action" ;
VAL_ 2566801923 TransmReadyBrakeRleas 0 "Transmission Not Ready for Brake Release" 1 "Transmission Ready for Brake Release" 2 "Error" 3 "Not available" ;
VAL_ 2566801923 ActvShftConsleInd 0 "Primary shift console is active" 1 "Secondary shift console is active" 2 "Reserved" 3 "Not available" ;
VAL_ 2566801923 TransmEngCrkEna 0 "Cranking disabled engine cranking is prohibited by the transmission" 1 "Cranking enabled engine cranking is allowed by the transmission" 2 "Error" 3 "Not available" ;
VAL_ 2566801923 TransmShftInhInd 0 "Inactive shift is not inhibited" 1 "Active shift is inhibited" 2 "Reserved" 3 "Take no action" ;
VAL_ 2566801923 TransmMode_4Ind 0 "Transmission Mode 4 not active" 1 "Transmission Mode 4 Active" 2 "Error" 3 "Not available" ;
VAL_ 2566801923 TransmMode_3Ind 3 "Not available" 0 "Transmission Mode 3 not active" 1 "Transmission Mode 3 Active" 2 "Error" ;
VAL_ 2566801923 TransmMode_2Ind 0 "Transmission Mode 2 not active" 1 "Transmission Mode 2 Active" 2 "Error" 3 "Not available" ;
VAL_ 2566801923 TransmMode_1Ind 0 "Transmission Mode 1 not active" 1 "Transmission Mode 1 Active" 2 "Error" 3 "Not available" ;
VAL_ 2566801923 TransmMode_5Ind 0 "Off" 1 "Transport Mode ON" 2 "Field Mode ON" 3 "Take no action" ;
VAL_ 2566801923 TransmMode_6Ind 0 "Disable" 1 "Enable" 2 "Reserved" 3 "Take no action" ;
VAL_ 2566801923 TransmMode_7Ind 0 "Disable" 1 "Enable" 2 "Reserved" 3 "Take no action" ;
VAL_ 2566801923 TransmMode_8Ind 0 "Disable" 1 "Enable" 2 "Reserved" 3 "Take no action" ;
VAL_ 2566801923 TransmRevGearShftInhSts 2 "Error" 3 "Not Available" 0 "Reverse gear shifts are currently allowed" 1 "Reverse gear shifts are currently inhibited" ;
VAL_ 2566801923 TransmWarnInd 0 "Transmission Warning Indicator is off" 1 "Transmission Warning Indicator is on continuously" 2 "Transmission Warning Indicator is flashing" 3 "Not available" ;
VAL_ 2348820227 EngReqSpdCntrlCondtn 0 "Use Gov 0 of Dataset Req Sheet" 1 "Use Gov 1 of Dataset Req Sheet" 3 "Use Gov 3 of Dataset Req Sheet" 2 "Use Gov 2 of Dataset Req Sheet" ;
VAL_ 2348820227 EngOverrideCntrlMode 0 "Override disabled  Disable any existing control commanded by the source of this command" 1 "Speed control  Govern speed to the included desired speed value" 2 "Torque control  Control torque to the included desired torque value" 3 "Speed/torque limit control  Limit speed and/or torque based on the included limit values  The speed limit governor is" ;
VAL_ 2348820227 MsgCnt_2 14 "Reserved" 13 "Reserved" 12 "Reserved" 11 "Reserved" 10 "Reserved" 9 "Reserved" 8 "Reserved" 15 "Not Available" ;
VAL_ 2348820227 OverrideCntrlModePrio 0 "Highest priority" 1 "High priority" 2 "Medium priority" 3 "Low priority" ;
VAL_ 2348820227 TSC1_TransmRate 0 "1000 ms transmission rate" 1 "750 ms transmission rate" 2 "500 ms transmission rate" 3 "250 ms transmission rate" 4 "100 ms transmission rate" 5 "50 ms transmission rate" 6 "20 ms transmission rate" 7 "Use standard TSC1 transmission rates of 10 ms to engine" ;
VAL_ 2348820227 TSC1_CntrlPurp 0 "P1  Accelerator Pedal/Operator Selection" 1 "P2  Cruise Control" 2 "P3  PTO Governor" 3 "P4  Road Speed Governor" 4 "P5  Engine Protection" 5 "11110  P6P31  Reserved for SAE Assignment" 31 "P32  Temporary Power Train Control Original use of TSC1 Command" ;
VAL_ 2348820227 EngReqTorqFrac 8 "1111  not available" 0 "0000" 1 "0125" 7 "0875" ;
VAL_ 2499778307 B2C_Sts 3 "NA" 2 "Error" 1 "Not Working" 0 "Working" ;
VAL_ 2499778307 RPTO_SpdRatioSts 7 "NA" 6 "Error" 4 "N" 0 " 540" 1 " 540 E" 2 "1000" 3 "1000 E" ;
VAL_ 2499778307 TransmCalibrSts 2 "Transmission calibr in progress" 7 "NA" 6 "Error" 1 "Transmission not calibrated" 0 "Transmission calibrated" ;
VAL_ 2499778307 ESPTO_CalibrSts 7 "NA" 6 "Error" 0 "Not Calibrated" 1 "Calibrated" 2 "Calibration in progress" ;
VAL_ 2499778307 PBrakeReq 0 "Disengaged" 1 "Engaged" 2 "Error" 3 "NA" ;
VAL_ 2499778307 RPTO_CalibrSts 7 "NA" 6 "Error" 0 "Calibrated" 1 "Not Calibrated" 2 "Calibration in progress" ;
VAL_ 2566886915 DrvlOilPrsWarn 4 "Pressure too high(critical)" 0 "Warning Indicator is off" 1 "Pressure too low (warning)" 2 "Pressure too low (critical)" 3 "Pressure too high (warning)" 7 "NA" 6 "Error" ;
VAL_ 2566886915 DrvlOilTempWarn 7 "NA" 6 "Error" 4 "Temperature too high (critical)" 0 "Warning Indicator is off" 1 "Temperature too low (warning)" 2 "Temperature too low (critical)" 3 "Temperature too high (warning)" ;
VAL_ 2566886915 TransmDsrdModeSts 15 "NA" 14 "Error" 8 "Auto Mode Standby" 7 "APM Transport - only DCT/PS" 6 "APM Field - only DCT/PS" 5 "Auto Transport - only DCT/PS" 4 "Auto Field - only DCT/PS" 0 "take no action" 1 "Manual" 2 "Auto Shift" 3 "Auto Up-Shift - only DCT/PS" ;
VAL_ 2566886915 EngShutdnReq 0 "Off" 1 "On" 2 "Off" 3 "Off" ;
VAL_ 2566886915 HydrostatTransmOilPrsWarn 7 "NA" 6 "Error" 4 "too high - critical" 3 "too high - warning" 2 "too low - critical" 1 "too low - warning" 0 "not warning" ;
VAL_ 2566886915 SelCltchSts 0 "disengaged" 1 "engaged" 2 "Error" 3 "NA" ;
VAL_ 2566886915 MachSelDirect 0 "Reverse" 1 "Forward" 2 "ErrorIndication" 3 "NotAvailable" ;
VAL_ 2566886915 HydrostatTransmFiltClogWarn 7 "NA" 6 "Error" 0 "not warning" 1 "warning 1" 2 "critical" ;
VAL_ 2566886915 TransmLubrPrsWarn 3 "Not Available" 2 "Critical - pressure too low" 1 "Warning - Pressure too low" 0 "No Warning" ;
VAL_ 2566886915 HydTemp 255 "N/A" 254 "Error" ;
VAL_ 2566846467 TransmOilLev_1CntdwnTmr 0 "less than 1 minute" 1 "One minute" 2 "Two minutes" 3 "Three minutes" 4 "Four minutes" 5 "Five minutes" 6 "Six minutes" 7 "Seven minutes" 8 "Eight minutes" 9 "Nine minutes" 10 "Ten minutes" 11 "Eleven minutes" 12 "Twelve minutes" 13 "Thirteen minutes" 14 "Error" 15 "Not Available" ;
VAL_ 2566846467 TransmOilLev_1MeasSts 10 "Not defined" 11 "Not defined" 0 "Conditions valid for transmission oil level measurement" 1 "Conditions not valid  Settling timer still counting down" 2 "Conditions not valid  Transmission in gear" 3 "Conditions not valid  Transmission fluid temperature too low" 4 "Conditions not valid  Transmission fluid temperature too high" 5 "Conditions not valid  Vehicle moving output shaft speed too high" 6 "Conditions not valid  Vehicle not level" 7 "Conditions not valid  Engine speed too low" 8 "Conditions not valid  Engine speed too high" 9 "Conditions not valid  No request for reading" 12 "Not defined" 13 "Conditions not valid  Other" 14 "Error" 15 "Not available" ;
VAL_ 2364539395 TransmDrvlEngag 0 "Driveline disengaged" 1 "Driveline engaged" 2 "Error" 3 "Not available" ;
VAL_ 2364539395 TransmTorqConvLckupEngag 0 "Torque converter lockup disengaged" 1 "Torque converter lockup engaged" 2 "Error" 3 "Not available" ;
VAL_ 2364539395 TransmShftInProc 0 "Shift is not in process" 1 "Shift in process" 2 "Error" 3 "Not available" ;
VAL_ 2364539395 TransmTorqConvLckupTransInProc 0 "Transition is not in process" 1 "Transition is in process" 2 "Error" 3 "Not available" ;
VAL_ 2364539395 EngMomentOverspeedEna 0 "Momentary engine overspeed is disabled" 1 "Momentary engine overspeed is enabled" 2 "Reserved" 3 "Take no action" ;
VAL_ 2364539395 ProgveShftDis 0 "Progressive shift is not disabled" 1 "Progressive shift is disabled" 3 "Take no action" 2 "Reserved" ;
VAL_ 2364539395 MomentEngMaxPwrEna 0 "not requesting maximum power available" 1 "momentarily requesting maximum power available" 2 "fault" 3 "not available" ;
VAL_ 2499777795 PBrakeRecovSts 7 "Not Available" 6 "Error" 3 "No Actuation" 2 "Degraded - Forced Manual" 1 "Warning" 0 "None" ;
VAL_ 2499777795 PBrakeSts 15 "NOT_AVAILABLE" 14 "ERROR" 6 "S_NOT_INIT" 5 "S_PARTIAL" 4 "S_RELEASING" 3 "S_APPLYING" 2 "S_RELEASE" 1 "S_APPLY" 0 "RESERVED" ;
VAL_ 2499777795 TransmRecovReact 3 "driveline disengaged - CP reqrd" 7 "Not available" 6 "Error" 0 "none" 1 "driveline disengaged" 2 "driveline in power zero" ;
VAL_ 2499777795 WhRevolSpd 64256 "Overspeed" 65534 "Error" 65535 "N/A" ;
VAL_ 2499777795 GndSpdPTO_Sts 3 "Not Available" 2 "Error indicator" 1 "Enabled" 0 "Disabled" ;
VAL_ 2499777795 AgPTO_ShaftTyp 15 "Not Available" 14 "Error" 2 "PTO Type 2/3 Involute Splines" 1 "PTO Type 1 - 6 Straight Splines" 0 "Detection in Progress" ;
VAL_ 2565867011 DiffLckStsCent 0 "Differential lock disengaged" 1 "Differential lock engaged" 2 "Error" 3 "Not available" ;
VAL_ 2565867011 DiffLckStsRAx_1 0 "Differential lock disengaged" 1 "Differential lock engaged" 2 "Error" 3 "Not available" ;
VAL_ 2565867011 DiffLckStsRAx_3 3 "Not available" 2 "Error" 1 "Differential lock engaged
" 0 "Differential lock disengaged
" ;
VAL_ 2565867011 DiffLckStsFAx_1 0 "Differential lock disengaged" 1 "Differential lock engaged" 2 "Error" 3 "Not available" ;
VAL_ 2565867011 DiffLckStsFAx_2 0 "Differential lock disengaged" 1 "Differential lock engaged" 2 "Error" 3 "Not available" ;
VAL_ 2565867011 DiffLckStsRAx_2 0 "Differential lock disengaged" 1 "Differential lock engaged" 2 "Error" 3 "Not available" ;
VAL_ 2565867011 DiffLckStsCentFrnt 0 "Differential lock disengaged" 1 "Differential lock engaged" 2 "Error" 3 "Not available" ;
VAL_ 2565867011 DiffLckStsCentRear 0 "Differential lock disengaged" 1 "Differential lock engaged" 2 "Error" 3 "Not available" ;
VAL_ 2565867011 FAxGrpEngagSts 0 "front axle group disengaged" 1 "front axle group engaged" 2 "error" 3 "not available" ;
VAL_ 2565867011 RAxGrpEngagSts 0 "rear axle group disengaged" 1 "rear axle group engaged" 2 "error" 3 "not available" ;
VAL_ 2565344807 PGN_RQST2_27_0E 65253 "HOURS" ;
VAL_ 2565344807 CByteAckm 3 "CannotRespond" 2 "AccessDenied" 1 "NACK" 0 "ACK" ;
VAL_ 2565475879 PGN_RQST_27_0E 65259 "CI" 65229 "DM4Req" 64965 "ECUID" 60928 "ACL" 41728 "DM31Req" 65242 "SOFT" 65235 "DM11Req" 65228 "DM3Req" 65227 "DM2Req" ;
VAL_ 2499796007 CRPM_Sts 3 "NA" 2 "Error" 1 "Active" 0 "Not Active" ;
VAL_ 2499796007 RngLckGearReq 7 "N/A" 6 "Error" 5 "Range Gear 5" 4 "Range Gear 4" 3 "Range Gear 3" 2 "Range Gear 2" 1 "Range Gear 1" 0 "Disabled" ;
VAL_ 2499796007 InchngFenderDirectCmd 2 "Error" 3 "N/A" 0 "Forward Inching direction " 1 "Reverse Inching direction " ;
VAL_ 2499796007 WhSpdChgReq 1023 "NA" ;
VAL_ 2499796007 DecelModeReq 15 "NA" 14 "Error" 13 "Reserved" 12 "Reserved" 11 "Reserved" 10 "Fast Stop 3" 9 "Fast Stop 2" 8 "Fast Stop 1" 7 "Shuttling 3" 6 "Shuttling 2" 5 "Shuttling 1" 4 "Normal Mode 3" 3 "Normal Mode 2" 2 "Fast Deceleration Mode" 1 "Normal Mode 1" 0 "None" ;
VAL_ 2499796007 AccelModeReq 15 "NA" 14 "Error" 13 "Reserved" 12 "Reserved" 11 "Reserved" 10 "Reserved" 9 "APM Implement Kickdown Mode" 8 "Normal Foot Pedal Mode" 7 "Shuttling 3" 6 "Shuttling 2" 5 "Shuttling 1" 4 "Normal Mode 3" 3 "Normal Mode 2" 2 "Kick Down Mode" 1 "Normal Mode 1" 0 "None" ;
VAL_ 2499796007 GPTO_EngagCmd 2 "Error" 3 "N/A" 1 "EngangePTO" 0 "DisengagePTO" ;
VAL_ 2565473063 PGN_RQST_27_03 65368 "PB_AxleId_03" 65395 "ECU_DatasetChksum" 65394 "ECU_Dataset" ;
VAL_ 2565341991 PGN_RQST2_27_03 65395 "ECU_Dataset_ChkSum" 65394 "ECU_Dataset" ;
VAL_ 2565341991 CByteAckm 3 "CannotRespond" 2 "AccessDenied" 1 "NACK" 0 "ACK" ;
VAL_ 2566894631 VehPerfMode 7 "N/A" 6 "Error" 2 "Eco" 1 "Balance" 0 "Performance" ;
VAL_ 2566894631 PTO_AntiPitchEna 3 "N/A" 2 "Error" 1 "Enabled" 0 "Disabled" ;
VAL_ 2566894631 CalibrStopReason 9 "Engine Speed error" 8 "Reserved" 7 "Reserved" 6 "Reserved" 5 "Reserved" 11 "Clutch Not Working" 10 "Park Lock Engaged" 15 "NA" 14 "Error" 4 "Waiting for operator ACK" 3 "Cluth pedal to be released" 2 "Handbrake to be applied" 1 "Operator out of seat" 0 "No Pause" 12 "Operator Ack Button Error" ;
VAL_ 2566894631 CalibrCmd 7 "NA" 6 "Error" 5 "Reserved" 4 "Reserved" 3 "Start/Resume" 2 "pause" 1 "Stop" 0 "Idle" ;
VAL_ 2566894631 OverspeedLimFactor 1023 "N/A" 1022 "Error" ;
VAL_ 2566894631 TransmDsrdSubmodeCmd 7 "N/A" 6 "Error" 3 "Temporary Road" 2 "Temporary Field" 1 "Road" 0 "Field" ;
VAL_ 2566877735 RAxRatio 15 "N/A" 14 "Error" 4 "19.636" 3 "18.436" 2 "17.455" 1 "17.018" 0 "15.127" ;
VAL_ 2566877735 FrntBrakeOpt 3 "N/A" 2 "Error" 1 "Present" 0 "Not Present" ;
VAL_ 2566877735 BrandDiff 1 "not available" 0 "available" ;
VAL_ 2566877735 Brand 7 "N/A" 6 "Error" 2 "Steyr" 1 "NH" 0 "CIH" ;
VAL_ 2499798055 SpecialModeResp 1 "Normal Mode" 0 "Special Mode" ;
VAL_ 2499798055 SpecialModeReq 7 "No Special Mode Activated" 6 "Reserved" 5 "Reserved" 4 "Reserved" 3 "Reserved" 2 "Reserved" 1 "EngineCoolDownMode" 0 "Keypad Test Mode" ;
VAL_ 2499798055 KeyPositn 255 "N/A" 4 "Key ON" 1 "Key OFF" ;
VAL_ 2499798055 BattMainSwHoldFunct 15 "Not Available" 14 "Function 15" 13 "Function 14" 12 "Function 13" 11 "Function 12" 10 "Function 11" 9 "Function 10" 8 "Function 9" 7 "Function 8" 6 "Function 7" 5 "Function 6" 4 "Function 5" 3 "Function 4" 2 "Function 3" 1 "Function 2" 0 "Function 1" ;
VAL_ 2499798055 ThisNetReq 3 "Don't care " 2 "Reserved" 1 "Net ON" 0 "Net OFF" ;
VAL_ 2499798055 BattMainSwHoldReq 3 "Dont care/take no action" 2 "undefined" 1 "Hold Battery Main Switch" 0 "Release Battery Main Switch" ;
VAL_ 2499798055 OpSeatSw 0 "Absent" 1 "Present" 2 "Error" 3 "NA" ;
VAL_ 2499798055 AutoGuideEnaSts 3 "Don't care/take no action" 2 "Reserved" 1 "CommandToEnableFunction" 0 "CmdToDisableFunct(NotApplicable)" ;
VAL_ 2499798055 WakeUpInDozeMode 3 "No Action" 2 "Reserved" 1 "On in Doze Mode Command/Request" 0 "Off Command, No Request" ;
VAL_ 2499798055 WakeUpFunct 15 "Not Available" 14 "Function 15" 13 "Function 14" 12 "Function 13" 11 "Function 12" 10 "Function 11" 9 "Function 10" 8 "Function 9" 7 "Function 8" 6 "Function 7" 5 "Function 6" 4 "Function 5" 3 "Function 4" 2 "Function 3" 1 "Function 2" 0 "Function 1" ;
VAL_ 2499798055 VehMov 3 "Not Available" 2 "Error Indicator" 1 "On" 0 "Off" ;
VAL_ 2499798055 KeySwNotOFF 3 "NotAvailable" 2 "ErrorIndication" 1 "KeySwitchNotOff" 0 "KeySwitchOff" ;
VAL_ 2499798055 IgnON 3 "No Action" 2 "Reserved" 1 "On Status/Request" 0 "Off Status, No Request" ;
VAL_ 2499798055 EngStartSts 2 "Error" 3 "Not Available" 1 "On" 0 "Off" ;
VAL_ 2499798055 CByteNetManage 3 "Default or NetWorkMang_N/A" 2 "Reserved" 1 "Command" 0 "Request" ;
VAL_ 2499798055 EngRun 3 "Not Available" 2 "Error Indicator" 1 "On" 0 "Off" ;
VAL_ 2499798055 EmergEngOff_ReqSts 1 "Emergency engine OFF request ACTIVE" 0 "Emergency engine OFF request INACTIVE" ;
VAL_ 2499798055 MasterDisconnSwSts 1 "Master Disconnect switch ACTIVE" 0 "Master Disconnect switch INACTIVE" ;
VAL_ 2499777319 KickdnReq 0 "Not Active" 1 "Active" 2 "Error" 3 "NA" ;
VAL_ 2499777319 EngDroopMaxReq 31 "NA" ;
VAL_ 2499777319 SmoothShftEna 3 "NotAvailable" 2 "Error" 1 "Enabled" 0 "Not enabled" ;
VAL_ 2499777319 AntiJckKnifeCmd 3 "NotAvailable" 2 "Error" 1 "On" 0 "Off" ;
VAL_ 2499777319 B2C_Ena 3 "On - High" 2 "On - Medium" 1 "On - Low" 0 "Off" 7 "NA" 6 "Error" 5 "Reserved" 4 "Reserved" ;
VAL_ 2499777319 RightBrakeSts 0 "Not pushed" 1 "pushed" 2 "Error" 3 "NA" ;
VAL_ 2499777319 LeftBrakeSts 3 "NA" 2 "Error" 1 "Pushed" 0 "Not pushed" ;
VAL_ 2499777319 HandBrakeSw 3 "NOT_AVAILABLE" 2 "ERROR" 1 "ON" 0 "OFF" ;
VAL_ 2499777319 TransmDsrdModeCmd 10 "Manual Quantized" 9 "Advanced APM" 15 "NA" 14 "Error" 8 "Auto Mode Standby" 7 "APM Transport - only DCT/PS" 6 "APM Field - only DCT/PS" 5 "Auto Transport - only DCT/PS" 4 "Auto Field - only DCT/PS" 0 "take no action" 1 "Manual" 2 "Auto Shift" 3 "Auto Up-Shift - only DCT/PS" ;
VAL_ 2348941095 TransmAutoN_Req 3 "Don’t Care / Take No Action" 2 "Reserved" 1 "Request to shift to Auto-Neutral" 0 "No request to shift Auto-Neutral" ;
VAL_ 2348941095 TransmGearShftInhReq 0 "Gear shifts are allowed  disable function" 1 "Gear shifts are inhibited  enable function" 3 "Take no action  leave function as is" 2 "Reserved" ;
VAL_ 2348941095 TransmTorqConvLckupDisReq 0 "Allow torque converter lockup" 1 "Disable torque converter lockup" 2 "Reserved" 3 "Take no action" ;
VAL_ 2348941095 DisengDrvlReq 0 "Allow driveline engagement" 1 "Disengage driveline" 3 "Take no action" 2 "Reserved" ;
VAL_ 2348941095 TransmRevGearShftInhReq 0 "Allow shifts into Reverse gear" 1 "Inhibit shifts into Reverse gear and shift transmission to Neutral if already in Reverse or attempting to shift to" 2 "Reserved" 3 "Take no action" ;
VAL_ 2348941095 TransmReqGear 207 "Neutral Declutch" 127 "Rear with Park Engaged" 126 "Forward with Park Engaged" 254 "Error" 125 "Neutral" 223 "Reverse Selector pos" 224 "N reqstd for SAHR man disngmnt" 225 "PressMomBtnToReselCurPos-NOTused" 226 "Betw. R and P pos - NOTused" 227 "Betw. N and R pos - NOTused" 228 "Betw.Drivand Neutral pos-NOTused" 229 "BetwD-andDrivshiftSelPos-NOTused" 230 "Betw. D-2 and D-1 pos-NOTused" 231 "Betw. D-3 and D-2 pos-NOTused" 232 "Betw. D-4 and D-3 pos-NOTused" 233 "Betw. D-5 and D-4 pos-NOTused" 234 "Betw. D-6 and D-5 pos-NOTused" 235 "Betw. D-7 and D-6 pos-NOTused" 236 "Betw. two fw pos.-NOTused" 237 "Betw. two reverse pos-NOTused" 238 "Betw. two pos-NOTused" 239 "D-7 7th fw pos from Driv-NOTused" 240 "D-6 6th fw pos from Driv-NOTused" 241 "D-5 5th fw pos from Driv-NOTused" 242 "D-4 4th fw pos from Driv-NOTused" 243 "D-3 3rd fw pos from Driv-NOTused" 244 "D-2 2nd fw pos from Driv-NOTused" 245 "D-1 1st fw pos from Driv-NOTused" 246 "Downshift 2 gear - NOT used" 247 "Downshift 1 gear- NOT used" 248 "Upshift 2 gear- NOT used" 249 "Upshift 1 gear- NOT used" 250 "Fw Low pos" 251 "Park pos" 252 "Fw Drive pos" 253 "Hold current gear" 255 "No action" ;
VAL_ 2348941095 DisengDiffLckReqFAx_1 0 "Engage differential lock" 1 "Disengage differential lock" 2 "Reserved" 3 "Take no action" ;
VAL_ 2348941095 DisengDiffLckReqFAx_2 0 "Engage differential lock" 1 "Disengage differential lock" 2 "Reserved" 3 "Take no action" ;
VAL_ 2348941095 DisengDiffLckReqRAx_1 0 "Engage differential lock" 1 "Disengage differential lock" 2 "Reserved" 3 "Take no action" ;
VAL_ 2348941095 DisengDiffLckReqRAx_2 0 "Engage differential lock" 1 "Disengage differential lock" 2 "Reserved" 3 "Take no action" ;
VAL_ 2348941095 DisengDiffLckReqCent 0 "Engage differential lock" 1 "Disengage differential lock" 2 "Reserved" 3 "Take no action" ;
VAL_ 2348941095 DisengDiffLckReqCentFrnt 0 "Engage differential lock" 1 "Disengage differential lock" 2 "Reserved" 3 "Take no action" ;
VAL_ 2348941095 DisengDiffLckReqCentRear 0 "Engage differential lock" 1 "Disengage differential lock" 2 "Reserved" 3 "Take no action" ;
VAL_ 2348941095 TransmLoadReducInhReq 0 "Allow or resume transmission load reduction functions" 1 "Inhibit or abort transmission load reduction functions" 2 "Reserved" 3 "Dont care/take no action" ;
VAL_ 2348941095 TransmMode_1 0 "Disable" 1 "Enable" 2 "Reserved" 3 "Take no action" ;
VAL_ 2348941095 TransmMode_2 0 "Disable - Manual Mode ON" 1 "Enable - Auto Mode ON" 2 "Reserved" 3 "Take no action" ;
VAL_ 2348941095 TransmMode_3 0 "Disable" 1 "Enable" 2 "Reserved" 3 "Take no action" ;
VAL_ 2348941095 TransmMode_4 0 "Disable" 1 "Enable" 2 "Reserved" 3 "Take no action" ;
VAL_ 2348941095 TransmReqLaunchGear 0 "No specific launch gear requested use default launch gear" 1 "Launch the vehicle in 1st gear" 2 "Launch the vehicle in 2nd gear" 3 "Launch the vehicle in 3rd gear" 4 "Launch the vehicle in 4th gear" 5 "Launch the vehicle in 5th gear" 6 "Launch the vehicle in 6th gear" 7 "Launch the vehicle in 7th gear" 8 "Launch the vehicle in 8th gear" 9 "Launch the vehicle in Reverse 1" 10 "Launch the vehicle in Reverse 2" 11 "Launch the vehicle in Reverse 3" 12 "Launch the vehicle in Reverse 4" 13 "Reserved" 14 "Error" 15 "Not Available" ;
VAL_ 2348941095 TransmShftSelDisplayModeSw 0 "Off" 1 "On" 2 "Error" 3 "Not available" ;
VAL_ 2348941095 TransmMode_5 0 "Off" 1 "Transport Mode ON" 2 "Field Mode ON" 3 "Take no action" ;
VAL_ 2348941095 TransmMode_6 0 "Disable" 1 "Enable" 2 "Reserved" 3 "Take no action" ;
VAL_ 2348941095 TransmMode_7 0 "Disable" 1 "Enable" 2 "Reserved" 3 "Take no action" ;
VAL_ 2348941095 TransmMode_8 0 "Proportional Disengage command" 1 "On/Off Disengage command" 2 "Error" 3 "N/A" ;
VAL_ 2566852135 TheoVehSpd 65024 "Error" 65535 "N/A" ;
VAL_ 2632711975 SN_TPDT 255 "NoSequenceAvailable" ;
VAL_ 2364539943 ActlEng_pcTorqFrac 15 "No action" 14 "No action" 13 "No action" 12 "No action" 11 "No action" 10 "No action" 9 "No action" 8 "No action" 7 "additional torque +0.875%" 6 "additional torque +0.750%" 5 "additional torque +0.625%" 4 "additional torque +0.500%" 3 "additional torque +0.375%" 2 "additional torque +0.250%" 1 "additional torque +0.125%" 0 "additional torque +0.000%" ;
VAL_ 2364539943 EngTorqMode 15 "Not available" 14 "VCM_speed_demand" 13 "VCM_torque_demand" 12 "Fuel_limiting" 11 "Not defined" 10 "Retarder_control (not used)" 7 "ABS_control (not used)" 0 "Idling (default)" 1 "Acc_Pedal_Gov(onlyOneBoxApplic)" 2 "Cruise_control (not used)" 3 "PTO_gov (not used)" 4 "Road_speed_limiter (not used)" 5 "ASR_control (not used)" 6 "Trans_control  (not used)" 8 "Torque_limiter" 9 "High_speed_gov" ;
VAL_ 2364539943 DrivRqstEng_pcTorq 254 "Error" 255 "N/A" ;
VAL_ 2364539943 ActlEng_pcTorq 254 "Error" 255 "N/A" ;
VAL_ 2364539943 EngSpd 65024 "Error" 65535 "N/A" ;
VAL_ 2364539943 SA_CntrlDevEngCntrl 254 "Error" 255 "N/A" ;
VAL_ 2364539943 EngStartMode 6 "strtrInhbtdDTDrvlnEnggd(notUsed)" 5 "strtrInhDTEngNtReady4Sta(notUse)" 4 "strtrInhbtdDToEngAlreadyRunning" 3 "StarterFinished" 2 "StarterActiveGearEngaged" 1 "StarterActiveGearNotEngaged" 0 "StartNotRqed" 15 "notAvailable" 14 "error" 12 "starterInhibitedReasonUnknown" 7 "strtrInhbtdDToActiveImmobilizer" ;
VAL_ 2364539943 EngRqst_pcTorq 254 "Error" 255 "N/A" ;
VAL_ 2632777511 CByteTPCM 16 "RTS" 17 "CTS" 19 "EoMA" 32 "BAM" 255 "Abort" ;
VAL_ 2632777511 PGN_PktMsgTPCM_RTS 255 "NotAvailable" ;
VAL_ 2632777511 ConnAbrtReason 1 "AlreadyInConnManagedSession" 2 "NoFreeSystemResources" 3 "Timeout_CloseSession" 4 "UnexpectedDataTransferPacket" 5 "BadSequenceNumber" 6 "DuplicateSequenceNumber" 7 "AnyOtherError" ;
VAL_ 2632777511 PGN_PktMsgTPCM_ConnAbort 255 "NotAvailable" ;
VAL_ 2632777511 PGN_PktMsgTPCM_BAM 255 "NotAvailable" ;
VAL_ 2632777511 PGN_PktMsgTPCM_RTS2 255 "NotAvailable" ;
VAL_ 2632777511 PGN_PktMsgTPCM_CTS 255 "NotAvailable" ;
